VERSION ""

NS_ :

BS_:

BU_: WCM VPM VLM VKM UVM TIM TEST_TOOL_2 TEST_TOOL_1 TCP TCM TCCM3 TCCM STC SRR_SRR SRR_SLR SRR_RR SRR_RF SRR_LR_CR SRR_LF SIB SDM SCL SBZA_R SBZA_L SBM SADS RadioLow RSC RDCM PTM PDR PA NVM MTCM_R MTCM_L MSM_RR MSM_P MSM_LR MSM_D MSB2 MSB1 MRCM_R MRCM_L MFC LRR_HC LRR LIB1 IPC ICS_Info ICCM HVAC_FP_R HVAC_FP_F HUD_CAN HDLM FCM_LC FCM EPS EOCM_HCP2 EOCM_HCP1 EOCM ELM ECP_X1 ECP_MC ECP_E ECM EBCM DMS DEFC DCM CSM CMMb CMMa CGM BSM_MH BSM BCM ARS ARB APA AOS AMP ALC AHS AHL_AFL AGC
VAL_TABLE_ PrsnlMdBrkPdlCstmCurSetVal 0 "SETTING_UNKNOWN" 1 "PERSONAL_MODE_1" 2 "PERSONAL_MODE_2" 3 "PERSONAL_MODE_3" 4 "PERSONAL_MODE_4" 5 "PERSONAL_MODE_5" 6 "PERSONAL_MODE_6" 7 "PERSONAL_MODE_7" ;
VAL_TABLE_ PrsnlMdSpnCstmCurSetVal 0 "SETTING_UNKNOWN" 1 "PERSONAL_MODE_1" 2 "PERSONAL_MODE_2" 3 "PERSONAL_MODE_3" 4 "PERSONAL_MODE_4" 5 "PERSONAL_MODE_5" 6 "PERSONAL_MODE_6" 7 "PERSONAL_MODE_7" ;
VAL_TABLE_ PrsnlMdSndCstmCurSetVal 0 "SETTING_UNKNOWN" 1 "PERSONAL_MODE_1" 2 "PERSONAL_MODE_2" 3 "PERSONAL_MODE_3" 4 "PERSONAL_MODE_4" 5 "PERSONAL_MODE_5" 6 "PERSONAL_MODE_6" 7 "PERSONAL_MODE_7" ;
VAL_TABLE_ PrsnlMdRideHghtCstmSetAv 0 "FALSE" 1 "TRUE" ;
VAL_TABLE_ PrsnlMdDrvlCstmSetAv 0 "FALSE" 1 "TRUE" ;
VAL_TABLE_ PrsnlMdBrkPdlCstmSetAv 0 "FALSE" 1 "TRUE" ;
VAL_TABLE_ PrsnlMdActAeroCstmSetAv 0 "FALSE" 1 "TRUE" ;
VAL_TABLE_ ExtdHillStrtAstCustSetAvl 0 "FALSE" 1 "TRUE" ;
VAL_TABLE_ PrsnlMdStrCstmCurSetVal 0 "SETTING_UNKNOWN" 1 "PERSONAL_MODE_1" 2 "PERSONAL_MODE_2" 3 "PERSONAL_MODE_3" 4 "PERSONAL_MODE_4" 5 "PERSONAL_MODE_5" 6 "PERSONAL_MODE_6" 7 "PERSONAL_MODE_7" ;
VAL_TABLE_ TrlrBrkDtd 0 "FALSE" 1 "TRUE" ;
VAL_TABLE_ PrsnlMdStrCstmSetAv 0 "FALSE" 1 "TRUE" ;
VAL_TABLE_ PrsnlMdSpnCstmSetAv 0 "FALSE" 1 "TRUE" ;
VAL_TABLE_ PrsnlMdSndCstmSetAv 0 "FALSE" 1 "TRUE" ;
VAL_TABLE_ JckKnfDtnCstAvlFlg1 0 "FALSE" 1 "TRUE" ;
VAL_TABLE_ CrgBedVwAutoLgtCstAvlFlg7 0 "FALSE" 1 "TRUE" ;
VAL_TABLE_ CrgBedVwAutoLgtCstAvlFlg6 0 "FALSE" 1 "TRUE" ;
VAL_TABLE_ CrgBedVwAutoLgtCstAvlFlg5 0 "FALSE" 1 "TRUE" ;
VAL_TABLE_ CrgBedVwAutoLgtCstAvlFlg4 0 "FALSE" 1 "TRUE" ;
VAL_TABLE_ CrgBedVwAutoLgtCstAvlFlg3 0 "FALSE" 1 "TRUE" ;
VAL_TABLE_ CrgBedVwAutoLgtCstAvlFlg2 0 "FALSE" 1 "TRUE" ;
VAL_TABLE_ CrgBedVwAutoLgtCstAvlFlg1 0 "FALSE" 1 "TRUE" ;
VAL_TABLE_ RrVwPrkAstSymCsAvlFlg2 0 "FALSE" 1 "TRUE" ;
VAL_TABLE_ RrVwPrkAstSymCsAvlFlg1 0 "FALSE" 1 "TRUE" ;
VAL_TABLE_ JckKnfDtnCstAvlFlg7 0 "FALSE" 1 "TRUE" ;
VAL_TABLE_ JckKnfDtnCstAvlFlg6 0 "FALSE" 1 "TRUE" ;
VAL_TABLE_ JckKnfDtnCstAvlFlg5 0 "FALSE" 1 "TRUE" ;
VAL_TABLE_ JckKnfDtnCstAvlFlg4 0 "FALSE" 1 "TRUE" ;
VAL_TABLE_ JckKnfDtnCstAvlFlg3 0 "FALSE" 1 "TRUE" ;
VAL_TABLE_ JckKnfDtnCstAvlFlg2 0 "FALSE" 1 "TRUE" ;
VAL_TABLE_ SrrndVwLghtCsAvlFlg3 0 "FALSE" 1 "TRUE" ;
VAL_TABLE_ SrrndVwLghtCsAvlFlg2 0 "FALSE" 1 "TRUE" ;
VAL_TABLE_ SrrndVwLghtCsAvlFlg1 0 "FALSE" 1 "TRUE" ;
VAL_TABLE_ RrVwPrkAstSymCsAvlFlg7 0 "FALSE" 1 "TRUE" ;
VAL_TABLE_ RrVwPrkAstSymCsAvlFlg6 0 "FALSE" 1 "TRUE" ;
VAL_TABLE_ RrVwPrkAstSymCsAvlFlg5 0 "FALSE" 1 "TRUE" ;
VAL_TABLE_ RrVwPrkAstSymCsAvlFlg4 0 "FALSE" 1 "TRUE" ;
VAL_TABLE_ RrVwPrkAstSymCsAvlFlg3 0 "FALSE" 1 "TRUE" ;
VAL_TABLE_ TrlrMirVidEnblCstAvlFlg4 0 "FALSE" 1 "TRUE" ;
VAL_TABLE_ TrlrMirVidEnblCstAvlFlg3 0 "FALSE" 1 "TRUE" ;
VAL_TABLE_ TrlrMirVidEnblCstAvlFlg2 0 "FALSE" 1 "TRUE" ;
VAL_TABLE_ TrlrMirVidEnblCstAvlFlg1 0 "FALSE" 1 "TRUE" ;
VAL_TABLE_ SrrndVwLghtCsAvlFlg7 0 "FALSE" 1 "TRUE" ;
VAL_TABLE_ SrrndVwLghtCsAvlFlg6 0 "FALSE" 1 "TRUE" ;
VAL_TABLE_ SrrndVwLghtCsAvlFlg5 0 "FALSE" 1 "TRUE" ;
VAL_TABLE_ SrrndVwLghtCsAvlFlg4 0 "FALSE" 1 "TRUE" ;
VAL_TABLE_ TrlrMirVidGdlnsCstAvlFlg5 0 "FALSE" 1 "TRUE" ;
VAL_TABLE_ TrlrMirVidGdlnsCstAvlFlg4 0 "FALSE" 1 "TRUE" ;
VAL_TABLE_ TrlrMirVidGdlnsCstAvlFlg3 0 "FALSE" 1 "TRUE" ;
VAL_TABLE_ TrlrMirVidGdlnsCstAvlFlg2 0 "FALSE" 1 "TRUE" ;
VAL_TABLE_ TrlrMirVidGdlnsCstAvlFlg1 0 "FALSE" 1 "TRUE" ;
VAL_TABLE_ TrlrMirVidEnblCstAvlFlg7 0 "FALSE" 1 "TRUE" ;
VAL_TABLE_ TrlrMirVidEnblCstAvlFlg6 0 "FALSE" 1 "TRUE" ;
VAL_TABLE_ TrlrMirVidEnblCstAvlFlg5 0 "FALSE" 1 "TRUE" ;
VAL_TABLE_ TrlrMirVidGdlnsCstAvlFlg7 0 "FALSE" 1 "TRUE" ;
VAL_TABLE_ TrlrMirVidGdlnsCstAvlFlg6 0 "FALSE" 1 "TRUE" ;
VAL_TABLE_ IndTmpStngStFR 0 "Off" 1 "Auto" 2 "Auto Lo" 3 "Auto Hi" 4 "Manual" ;
VAL_TABLE_ IndTmpStngStFL 0 "Off" 1 "Auto" 2 "Auto Lo" 3 "Auto Hi" 4 "Manual" ;
VAL_TABLE_ IndTmpStngStRR 0 "Off" 1 "Auto" 2 "Auto Lo" 3 "Auto Hi" 4 "Manual" ;
VAL_TABLE_ IndTmpStngStRL 0 "Off" 1 "Auto" 2 "Auto Lo" 3 "Auto Hi" 4 "Manual" ;
VAL_TABLE_ NoRtDetWrngChmEvSt 0 "NO_ACTION" 1 "ACTIVE" 2 "CANCEL_CHIME" ;
VAL_TABLE_ ManlPrkLmpChmEvtSt 0 "NO ACTION" 1 "ACTIVE" 2 "CANCEL CHIME" ;
VAL_TABLE_ LDCLDlydLkChmEvSt 0 "NO_ACTION" 1 "ACTIVE" 2 "CANCEL_CHIME" ;
VAL_TABLE_ KeyInRmdrChmEvntSt 0 "NO_ACTION" 1 "ACTIVE" 2 "CANCEL_CHIME" ;
VAL_TABLE_ PwrRrClsrObstclChmEvntStat 0 "No_Action" 1 "Active" 2 "Cancel_Chime" ;
VAL_TABLE_ PwrRrClsrNtfnChmEvntStat 0 "No_Action" 1 "Active" 2 "Cancel_Chime" ;
VAL_TABLE_ PwrRrClsrNormOpChmEvntStat 0 "No_Action" 1 "Active" 2 "Cancel_Chime" ;
VAL_TABLE_ OneSidedPrkLmpActvnChmEvtSt 0 "NO_ACTION" 1 "ACTIVE" 2 "CANCEL_CHIME" ;
VAL_TABLE_ StrgLckd 0 "FALSE" 1 "TRUE" ;
VAL_TABLE_ WlkAwyLkInhbtChmEvSt 0 "NO_ACTION" 1 "ACTIVE" 2 "CANCEL_CHIME" ;
VAL_TABLE_ ShfttoPrkChmEvntSt 0 "NO_ACTION" 1 "ACTIVE" 2 "CANCEL_CHIME" ;
VAL_TABLE_ RemLtInVhWrngChmEvSt 0 "NO_ACTION" 1 "ACTIVE" 2 "CANCEL_CHIME" ;
VAL_TABLE_ IndAirDstFR 0 "Off" 1 "Auto" 2 "Floor" 3 "Floor And Vent" 4 "Vent" 5 "Vent And Windshield" 6 "Windshield" 7 "Floor And Windshield" 8 "Floor And Vent And Windshield" 9 "Max Defrost" ;
VAL_TABLE_ IndAirDstFL 0 "Off" 1 "Auto" 2 "Floor" 3 "Floor And Vent" 4 "Vent" 5 "Vent And Windshield" 6 "Windshield" 7 "Floor And Windshield" 8 "Floor And Vent And Windshield" 9 "Max Defrost" ;
VAL_TABLE_ IndBlwStngStFrt 0 "Off" 1 "Auto" 2 "Manual" ;
VAL_TABLE_ IndRecircStng 0 "Off" 1 "Fresh Air" 2 "Recirc" ;
VAL_TABLE_ IndCompStng 0 "OFF" 1 "COMP_OFF" 2 "COMP_ON" 3 "COMP_ECON" ;
VAL_TABLE_ IndClmMdStng 0 "OFF" 1 "Comfort" 2 "ECO" 3 "Fan Only" ;
VAL_TABLE_ IndBlwStngStRr 0 "Off" 1 "Auto" 2 "Manual" ;
VAL_TABLE_ IndAirDstRL 0 "Off" 1 "Auto" 2 "Floor" 3 "Floor And Vent" 4 "Vent" 5 "Vent And Roof" 6 "Roof" 7 "Roof And Floor" 8 "Floor And Vent And Roof" ;
VAL_TABLE_ IndSYNC_Rr 0 "FALSE" 1 "TRUE" ;
VAL_TABLE_ IndSYNC_All 0 "FALSE" 1 "TRUE" ;
VAL_TABLE_ IndRrWndDfgStng 0 "Rear Defog OFF" 1 "Rear Defog ON" ;
VAL_TABLE_ IndRrHVAC_On 0 "FALSE" 1 "TRUE" ;
VAL_TABLE_ IndRrHVAC_Lckd 0 "FALSE" 1 "TRUE" ;
VAL_TABLE_ IndHtdFrtWshldSet 0 "HFWS_OFF" 1 "HFWS_ON" ;
VAL_TABLE_ IndFrtHVAC_On 0 "FALSE" 1 "TRUE" ;
VAL_TABLE_ IndAirDstRR 0 "Off" 1 "Auto" 2 "Floor" 3 "Floor And Vent" 4 "Vent" 5 "Vent And Roof" 6 "Roof" 7 "Roof And Floor" 8 "Floor And Vent And Roof" ;
VAL_TABLE_ DslExhFldRmnDist_Inv 0 "FALSE" 1 "TRUE" ;
VAL_TABLE_ FI_FiltdDispTotFlLvlPct_Inv 0 "FALSE" 1 "TRUE" ;
VAL_TABLE_ FI_FiltdDispTotFlLvlTnk2Pct_Inv 0 "FALSE" 1 "TRUE" ;
VAL_TABLE_ EngIntAirTmp_Inv 0 "FALSE" 1 "TRUE" ;
VAL_TABLE_ ASIRI_Ind08 0 "FALSE" 1 "TRUE" ;
VAL_TABLE_ ASIRI_Ind06 0 "FALSE" 1 "TRUE" ;
VAL_TABLE_ ASIRI_Ind04 0 "FALSE" 1 "TRUE" ;
VAL_TABLE_ ASIRI_Ind01 0 "FALSE" 1 "TRUE" ;
VAL_TABLE_ ASIRI_Ind05 0 "FALSE" 1 "TRUE" ;
VAL_TABLE_ ASIRI_Ind07 0 "FALSE" 1 "TRUE" ;
VAL_TABLE_ ASIRI_Ind02 0 "FALSE" 1 "TRUE" ;
VAL_TABLE_ VhSpdCntlSystmTyp 0 "No Vehicle Speed Control" 1 "Conventional Cruise Control" 2 "Adaptive Cruise Control" ;
VAL_TABLE_ MnlTrnsIndReq 0 "No Indication" 1 "Indication 1" 2 "Indication 2" 3 "Indication 3" ;
VAL_TABLE_ EngEmsRltMlfIndRq 0 "Continuous Indication" 1 "No Indication" 2 "Flashing 1 Hertz Indication" 3 "Flashing 2 Hertz Indication" 4 "Flashing 0.5 Hertz Indication" ;
VAL_TABLE_ ASIRI_Ind03 0 "FALSE" 1 "TRUE" ;
VAL_TABLE_ ElecShfPriTransCtlrMalfIndOn 0 "FALSE" 1 "TRUE" ;
VAL_TABLE_ ElecShfPriShfToDrvTryAgnIndOn 0 "FALSE" 1 "TRUE" ;
VAL_TABLE_ EngCmptHotWrnIndReq 0 "Off" 1 "Service" 2 "Hot Idle" 3 "Hot" ;
VAL_TABLE_ ElecShftPrTwoGrsSelIndRq 0 "OFF" 1 "PARK" 2 "NEUTRAL" 3 "DRIVE" ;
VAL_TABLE_ ElecShftPrLtdPrfMdIO 0 "FALSE" 1 "TRUE" ;
VAL_TABLE_ ElecShftPrHldShftLevEngRngIO 0 "FALSE" 1 "TRUE" ;
VAL_TABLE_ ElecShftPrDrPrkIntShftAtmpIO 0 "FALSE" 1 "TRUE" ;
VAL_TABLE_ ElecShftPrDrIntShftAtmpIO 0 "FALSE" 1 "TRUE" ;
VAL_TABLE_ ElecShftPrDrExitIO 0 "FALSE" 1 "TRUE" ;
VAL_TABLE_ ElecShftPrDrDoorStIndIO 0 "FALSE" 1 "TRUE" ;
VAL_TABLE_ ElecShftPrAtPrkIO 0 "FALSE" 1 "TRUE" ;
VAL_TABLE_ ElecShfPriTrnVehOffForPrkIndOn 0 "FALSE" 1 "TRUE" ;
VAL_TABLE_ EngOilChngIO 0 "FALSE" 1 "TRUE" ;
VAL_TABLE_ EngNEmsnsRltMlfnAct 0 "FALSE" 1 "TRUE" ;
VAL_TABLE_ EngHtStpEngIO 0 "FALSE" 1 "TRUE" ;
VAL_TABLE_ EngHtFlEnrchmntIO 0 "FALSE" 1 "TRUE" ;
VAL_TABLE_ EngCstFlCtOffAct 0 "FALSE" 1 "TRUE" ;
VAL_TABLE_ ElecShftPrTrnMlfIO 0 "FALSE" 1 "TRUE" ;
VAL_TABLE_ ElecShftPrRngInvRqIO 0 "FALSE" 1 "TRUE" ;
VAL_TABLE_ ElecShftPrPrkInvRqIO 0 "FALSE" 1 "TRUE" ;
VAL_TABLE_ GenFld 0 "FALSE" 1 "TRUE" ;
VAL_TABLE_ EngWtrInFlIO 0 "FALSE" 1 "TRUE" ;
VAL_TABLE_ EngSpdLmtnMdAct 0 "FALSE" 1 "TRUE" ;
VAL_TABLE_ EngShtdwnPndgIO 0 "FALSE" 1 "TRUE" ;
VAL_TABLE_ EngOilStrvtnIO 0 "FALSE" 1 "TRUE" ;
VAL_TABLE_ EngOilPrsLwIO 0 "FALSE" 1 "TRUE" ;
VAL_TABLE_ EngOilLvlLwIO 0 "FALSE" 1 "TRUE" ;
VAL_TABLE_ EngOilHotIO 0 "FALSE" 1 "TRUE" ;
VAL_TABLE_ TrnsSkpShftIO 0 "FALSE" 1 "TRUE" ;
VAL_TABLE_ PTWrmgWtToShftIO 0 "FALSE" 1 "TRUE" ;
VAL_TABLE_ PTExPrtclFltrWrnIO 0 "FALSE" 1 "TRUE" ;
VAL_TABLE_ PTExPrtclFltrWrn2IO 0 "FALSE" 1 "TRUE" ;
VAL_TABLE_ DslExFldCnWrngIndRq 0 "No Indication" 1 "Warning Level 1" 2 "Warning Level 2" 3 "Warning Level 3" 4 "Warning Level 4" 5 "Warning Level 5" 6 "Warning Level 6" 7 "Warning Level 7" 8 "Warning Level 8" 9 "Warning Level 9" 10 "Warning Level 10" 11 "Warning Level 11" 12 "Warning Level 12" 13 "Warning Level 13" 14 "Warning Level 14" 15 "Warning Level 15" ;
VAL_TABLE_ DslExNxEmWrngIndRq 0 "No Indication" 1 "Warning Level 1" 2 "Warning Level 2" 3 "Warning Level 3" 4 "Warning Level 4" 5 "Warning Level 5" 6 "Warning Level 6" 7 "Warning Level 7" 8 "Warning Level 8" 9 "Warning Level 9" 10 "Warning Level 10" 11 "Warning Level 11" 12 "Warning Level 12" 13 "Warning Level 13" 14 "Warning Level 14" 15 "Warning Level 15" ;
VAL_TABLE_ DslExFldTpWrngIndRq 0 "No Indication" 1 "Warning Level 1" 2 "Warning Level 2" 3 "Warning Level 3" 4 "Warning Level 4" 5 "Warning Level 5" 6 "Warning Level 6" 7 "Warning Level 7" 8 "Warning Level 8" 9 "Warning Level 9" 10 "Warning Level 10" 11 "Warning Level 11" 12 "Warning Level 12" 13 "Warning Level 13" 14 "Warning Level 14" 15 "Warning Level 15" ;
VAL_TABLE_ DslExhFldWrngIdRqER 0 "No Indication" 1 "Warning Level 1" 2 "Warning Level 2" 3 "Warning Level 3" 4 "Warning Level 4" 5 "Warning Level 5" 6 "Warning Level 6" 7 "Warning Level 7" 8 "Warning Level 8" 9 "Warning Level 9" 10 "Warning Level 10" 11 "Warning Level 11" 12 "Warning Level 12" 13 "Warning Level 13" 14 "Warning Level 14" 15 "Warning Level 15" ;
VAL_TABLE_ DslExhFldQlyWrngIReq 0 "No Indication" 1 "Warning Level 1" 2 "Warning Level 2" 3 "Warning Level 3" 4 "Warning Level 4" 5 "Warning Level 5" 6 "Warning Level 6" 7 "Warning Level 7" 8 "Warning Level 8" 9 "Warning Level 9" 10 "Warning Level 10" 11 "Warning Level 11" 12 "Warning Level 12" 13 "Warning Level 13" 14 "Warning Level 14" 15 "Warning Level 15" ;
VAL_TABLE_ DslExhFldDiagWrnIdRq 0 "No Indication" 1 "Warning Level 1" 2 "Warning Level 2" 3 "Warning Level 3" 4 "Warning Level 4" 5 "Warning Level 5" 6 "Warning Level 6" 7 "Warning Level 7" ;
VAL_TABLE_ DrvrSeltdSpdLmtrIndReq 0 "No Action" 1 "Driver Selected Speed Limiter Telltale Off" 2 "Driver Selected Speed Limiter Unavailable Telltale On" 3 "Driver Selected Speed Limiter White Telltale On" 4 "Driver Selected Speed Limiter Green Telltale On" ;
VAL_TABLE_ CnvntlCruzCtlIndReq 0 "No Action" 1 "Cruise Control Telltale Off" 2 "Cruise Control Unavailable Telltale On" 3 "Cruise Control White Telltale On" 4 "Cruise Control Green Telltale On" 5 "Cruise Control Blue Telltale On" ;
VAL_TABLE_ ACCompCmnd 0 "Off" 1 "On" ;
VAL_TABLE_ DslEmnsOBDMrkt 0 "North America" 1 "Europe" ;
VAL_TABLE_ DrSlctdSpdLmtrStSpdLmtRchd 0 "No Limit Reached" 1 "High Limit Reached" 2 "Low Limit Reached" 3 "Reserved" ;
VAL_TABLE_ DrSlctdSpdLmtrSetTypActv 0 "Off" 1 "Manual" 2 "Auto" 3 "Reserved" ;
VAL_TABLE_ ElecShfPriRdcSpdForReqdShfIndOn 0 "FALSE" 1 "TRUE" ;
VAL_TABLE_ CbnHtrWrmUpIndOn 0 "FALSE" 1 "TRUE" ;
VAL_TABLE_ DrSlctdSpdLmtrEnbld 0 "FALSE" 1 "TRUE" ;
VAL_TABLE_ DrSlctdSpdLmtrActv 0 "FALSE" 1 "TRUE" ;
VAL_TABLE_ CkFlFilrCapIO 0 "FALSE" 1 "TRUE" ;
VAL_TABLE_ Bat12VSysUnStab 0 "FALSE" 1 "TRUE" ;
VAL_TABLE_ AppCltchAutSrtIO 0 "FALSE" 1 "TRUE" ;
VAL_TABLE_ AirCndOffIO 0 "FALSE" 1 "TRUE" ;
VAL_TABLE_ EBDFld 0 "FALSE" 1 "TRUE" ;
VAL_TABLE_ CustMdTrcStbCstmAvFlg7 0 "FALSE" 1 "TRUE" ;
VAL_TABLE_ CustMdTrcStbCstmAvFlg6 0 "FALSE" 1 "TRUE" ;
VAL_TABLE_ CustMdTrcStbCstmAvFlg5 0 "FALSE" 1 "TRUE" ;
VAL_TABLE_ CustMdTrcStbCstmAvFlg4 0 "FALSE" 1 "TRUE" ;
VAL_TABLE_ CustMdTrcStbCstmAvFlg3 0 "FALSE" 1 "TRUE" ;
VAL_TABLE_ CustMdTrcStbCstmAvFlg2 0 "FALSE" 1 "TRUE" ;
VAL_TABLE_ CustMdTrcStbCstmAvFlg1 0 "FALSE" 1 "TRUE" ;
VAL_TABLE_ PrsnlMdActAeroCstmAvFlg1 0 "FALSE" 1 "TRUE" ;
VAL_TABLE_ ExtdHillStrtAstCustAvlFlg7 0 "FALSE" 1 "TRUE" ;
VAL_TABLE_ ExtdHillStrtAstCustAvlFlg6 0 "FALSE" 1 "TRUE" ;
VAL_TABLE_ ExtdHillStrtAstCustAvlFlg5 0 "FALSE" 1 "TRUE" ;
VAL_TABLE_ ExtdHillStrtAstCustAvlFlg4 0 "FALSE" 1 "TRUE" ;
VAL_TABLE_ ExtdHillStrtAstCustAvlFlg3 0 "FALSE" 1 "TRUE" ;
VAL_TABLE_ ExtdHillStrtAstCustAvlFlg2 0 "FALSE" 1 "TRUE" ;
VAL_TABLE_ ExtdHillStrtAstCustAvlFlg1 0 "FALSE" 1 "TRUE" ;
VAL_TABLE_ PrsnlMdBrkPdlCstmAvFlg2 0 "FALSE" 1 "TRUE" ;
VAL_TABLE_ PrsnlMdBrkPdlCstmAvFlg1 0 "FALSE" 1 "TRUE" ;
VAL_TABLE_ PrsnlMdActAeroCstmAvFlg7 0 "FALSE" 1 "TRUE" ;
VAL_TABLE_ PrsnlMdActAeroCstmAvFlg6 0 "FALSE" 1 "TRUE" ;
VAL_TABLE_ PrsnlMdActAeroCstmAvFlg5 0 "FALSE" 1 "TRUE" ;
VAL_TABLE_ PrsnlMdActAeroCstmAvFlg4 0 "FALSE" 1 "TRUE" ;
VAL_TABLE_ PrsnlMdActAeroCstmAvFlg3 0 "FALSE" 1 "TRUE" ;
VAL_TABLE_ PrsnlMdActAeroCstmAvFlg2 0 "FALSE" 1 "TRUE" ;
VAL_TABLE_ PrsnlMdDrvlCstmAvFlg3 0 "FALSE" 1 "TRUE" ;
VAL_TABLE_ PrsnlMdDrvlCstmAvFlg2 0 "FALSE" 1 "TRUE" ;
VAL_TABLE_ PrsnlMdDrvlCstmAvFlg1 0 "FALSE" 1 "TRUE" ;
VAL_TABLE_ PrsnlMdBrkPdlCstmAvFlg7 0 "FALSE" 1 "TRUE" ;
VAL_TABLE_ PrsnlMdBrkPdlCstmAvFlg6 0 "FALSE" 1 "TRUE" ;
VAL_TABLE_ PrsnlMdBrkPdlCstmAvFlg5 0 "FALSE" 1 "TRUE" ;
VAL_TABLE_ PrsnlMdBrkPdlCstmAvFlg4 0 "FALSE" 1 "TRUE" ;
VAL_TABLE_ PrsnlMdBrkPdlCstmAvFlg3 0 "FALSE" 1 "TRUE" ;
VAL_TABLE_ PrsnlMdRideHghtCstmAvFlg4 0 "FALSE" 1 "TRUE" ;
VAL_TABLE_ PrsnlMdRideHghtCstmAvFlg3 0 "FALSE" 1 "TRUE" ;
VAL_TABLE_ PrsnlMdRideHghtCstmAvFlg2 0 "FALSE" 1 "TRUE" ;
VAL_TABLE_ PrsnlMdRideHghtCstmAvFlg1 0 "FALSE" 1 "TRUE" ;
VAL_TABLE_ PrsnlMdDrvlCstmAvFlg7 0 "FALSE" 1 "TRUE" ;
VAL_TABLE_ PrsnlMdDrvlCstmAvFlg6 0 "FALSE" 1 "TRUE" ;
VAL_TABLE_ PrsnlMdDrvlCstmAvFlg5 0 "FALSE" 1 "TRUE" ;
VAL_TABLE_ PrsnlMdDrvlCstmAvFlg4 0 "FALSE" 1 "TRUE" ;
VAL_TABLE_ PrsnlMdSndCstmAvFlg5 0 "FALSE" 1 "TRUE" ;
VAL_TABLE_ PrsnlMdSndCstmAvFlg4 0 "FALSE" 1 "TRUE" ;
VAL_TABLE_ PrsnlMdSndCstmAvFlg3 0 "FALSE" 1 "TRUE" ;
VAL_TABLE_ PrsnlMdSndCstmAvFlg2 0 "FALSE" 1 "TRUE" ;
VAL_TABLE_ PrsnlMdSndCstmAvFlg1 0 "FALSE" 1 "TRUE" ;
VAL_TABLE_ PrsnlMdRideHghtCstmAvFlg7 0 "FALSE" 1 "TRUE" ;
VAL_TABLE_ PrsnlMdRideHghtCstmAvFlg6 0 "FALSE" 1 "TRUE" ;
VAL_TABLE_ PrsnlMdRideHghtCstmAvFlg5 0 "FALSE" 1 "TRUE" ;
VAL_TABLE_ PrsnlMdSpnCstmAvFlg6 0 "FALSE" 1 "TRUE" ;
VAL_TABLE_ PrsnlMdSpnCstmAvFlg5 0 "FALSE" 1 "TRUE" ;
VAL_TABLE_ PrsnlMdSpnCstmAvFlg4 0 "FALSE" 1 "TRUE" ;
VAL_TABLE_ PrsnlMdSpnCstmAvFlg3 0 "FALSE" 1 "TRUE" ;
VAL_TABLE_ PrsnlMdSpnCstmAvFlg2 0 "FALSE" 1 "TRUE" ;
VAL_TABLE_ PrsnlMdSpnCstmAvFlg1 0 "FALSE" 1 "TRUE" ;
VAL_TABLE_ PrsnlMdSndCstmAvFlg7 0 "FALSE" 1 "TRUE" ;
VAL_TABLE_ PrsnlMdSndCstmAvFlg6 0 "FALSE" 1 "TRUE" ;
VAL_TABLE_ PrsnlMdStrCstmAvFlg7 0 "FALSE" 1 "TRUE" ;
VAL_TABLE_ PrsnlMdStrCstmAvFlg6 0 "FALSE" 1 "TRUE" ;
VAL_TABLE_ PrsnlMdStrCstmAvFlg5 0 "FALSE" 1 "TRUE" ;
VAL_TABLE_ PrsnlMdStrCstmAvFlg4 0 "FALSE" 1 "TRUE" ;
VAL_TABLE_ PrsnlMdStrCstmAvFlg3 0 "FALSE" 1 "TRUE" ;
VAL_TABLE_ PrsnlMdStrCstmAvFlg2 0 "FALSE" 1 "TRUE" ;
VAL_TABLE_ PrsnlMdStrCstmAvFlg1 0 "FALSE" 1 "TRUE" ;
VAL_TABLE_ PrsnlMdSpnCstmAvFlg7 0 "FALSE" 1 "TRUE" ;
VAL_TABLE_ CustMdActAeroCstmAvFlg6 0 "FALSE" 1 "TRUE" ;
VAL_TABLE_ CustMdActAeroCstmAvFlg5 0 "FALSE" 1 "TRUE" ;
VAL_TABLE_ CustMdActAeroCstmAvFlg4 0 "FALSE" 1 "TRUE" ;
VAL_TABLE_ CustMdActAeroCstmAvFlg3 0 "FALSE" 1 "TRUE" ;
VAL_TABLE_ CustMdActAeroCstmAvFlg2 0 "FALSE" 1 "TRUE" ;
VAL_TABLE_ CustMdActAeroCstmAvFlg1 0 "FALSE" 1 "TRUE" ;
VAL_TABLE_ BrkFldLvlSt 0 "Normal" 1 "Low" 2 "Unknown" ;
VAL_TABLE_ CustMdBrkPdlCstmAvFlg7 0 "FALSE" 1 "TRUE" ;
VAL_TABLE_ CustMdBrkPdlCstmAvFlg6 0 "FALSE" 1 "TRUE" ;
VAL_TABLE_ CustMdBrkPdlCstmAvFlg5 0 "FALSE" 1 "TRUE" ;
VAL_TABLE_ CustMdBrkPdlCstmAvFlg4 0 "FALSE" 1 "TRUE" ;
VAL_TABLE_ CustMdBrkPdlCstmAvFlg3 0 "FALSE" 1 "TRUE" ;
VAL_TABLE_ CustMdBrkPdlCstmAvFlg2 0 "FALSE" 1 "TRUE" ;
VAL_TABLE_ CustMdBrkPdlCstmAvFlg1 0 "FALSE" 1 "TRUE" ;
VAL_TABLE_ CustMdActAeroCstmAvFlg7 0 "FALSE" 1 "TRUE" ;
VAL_TABLE_ CustMdPTCstmAvFlg1 0 "FALSE" 1 "TRUE" ;
VAL_TABLE_ CustMdDrvlCstmAvFlg7 0 "FALSE" 1 "TRUE" ;
VAL_TABLE_ CustMdDrvlCstmAvFlg6 0 "FALSE" 1 "TRUE" ;
VAL_TABLE_ CustMdDrvlCstmAvFlg5 0 "FALSE" 1 "TRUE" ;
VAL_TABLE_ CustMdDrvlCstmAvFlg4 0 "FALSE" 1 "TRUE" ;
VAL_TABLE_ CustMdDrvlCstmAvFlg3 0 "FALSE" 1 "TRUE" ;
VAL_TABLE_ CustMdDrvlCstmAvFlg2 0 "FALSE" 1 "TRUE" ;
VAL_TABLE_ CustMdDrvlCstmAvFlg1 0 "FALSE" 1 "TRUE" ;
VAL_TABLE_ CustMdRideHghtCstmAvFlg2 0 "FALSE" 1 "TRUE" ;
VAL_TABLE_ CustMdRideHghtCstmAvFlg1 0 "FALSE" 1 "TRUE" ;
VAL_TABLE_ CustMdPTCstmAvFlg7 0 "FALSE" 1 "TRUE" ;
VAL_TABLE_ CustMdPTCstmAvFlg6 0 "FALSE" 1 "TRUE" ;
VAL_TABLE_ CustMdPTCstmAvFlg5 0 "FALSE" 1 "TRUE" ;
VAL_TABLE_ CustMdPTCstmAvFlg4 0 "FALSE" 1 "TRUE" ;
VAL_TABLE_ CustMdPTCstmAvFlg3 0 "FALSE" 1 "TRUE" ;
VAL_TABLE_ CustMdPTCstmAvFlg2 0 "FALSE" 1 "TRUE" ;
VAL_TABLE_ CustMdSndCstmAvFlg3 0 "FALSE" 1 "TRUE" ;
VAL_TABLE_ CustMdSndCstmAvFlg2 0 "FALSE" 1 "TRUE" ;
VAL_TABLE_ CustMdSndCstmAvFlg1 0 "FALSE" 1 "TRUE" ;
VAL_TABLE_ CustMdRideHghtCstmAvFlg7 0 "FALSE" 1 "TRUE" ;
VAL_TABLE_ CustMdRideHghtCstmAvFlg6 0 "FALSE" 1 "TRUE" ;
VAL_TABLE_ CustMdRideHghtCstmAvFlg5 0 "FALSE" 1 "TRUE" ;
VAL_TABLE_ CustMdRideHghtCstmAvFlg4 0 "FALSE" 1 "TRUE" ;
VAL_TABLE_ CustMdRideHghtCstmAvFlg3 0 "FALSE" 1 "TRUE" ;
VAL_TABLE_ CustMdSpnCstmAvFlg4 0 "FALSE" 1 "TRUE" ;
VAL_TABLE_ CustMdSpnCstmAvFlg3 0 "FALSE" 1 "TRUE" ;
VAL_TABLE_ CustMdSpnCstmAvFlg2 0 "FALSE" 1 "TRUE" ;
VAL_TABLE_ CustMdSpnCstmAvFlg1 0 "FALSE" 1 "TRUE" ;
VAL_TABLE_ CustMdSndCstmAvFlg7 0 "FALSE" 1 "TRUE" ;
VAL_TABLE_ CustMdSndCstmAvFlg6 0 "FALSE" 1 "TRUE" ;
VAL_TABLE_ CustMdSndCstmAvFlg5 0 "FALSE" 1 "TRUE" ;
VAL_TABLE_ CustMdSndCstmAvFlg4 0 "FALSE" 1 "TRUE" ;
VAL_TABLE_ CustMdStrCstmAvFlg5 0 "FALSE" 1 "TRUE" ;
VAL_TABLE_ CustMdStrCstmAvFlg4 0 "FALSE" 1 "TRUE" ;
VAL_TABLE_ CustMdStrCstmAvFlg3 0 "FALSE" 1 "TRUE" ;
VAL_TABLE_ CustMdStrCstmAvFlg2 0 "FALSE" 1 "TRUE" ;
VAL_TABLE_ CustMdStrCstmAvFlg1 0 "FALSE" 1 "TRUE" ;
VAL_TABLE_ CustMdSpnCstmAvFlg7 0 "FALSE" 1 "TRUE" ;
VAL_TABLE_ CustMdSpnCstmAvFlg6 0 "FALSE" 1 "TRUE" ;
VAL_TABLE_ CustMdSpnCstmAvFlg5 0 "FALSE" 1 "TRUE" ;
VAL_TABLE_ CustMdStrCstmAvFlg7 0 "FALSE" 1 "TRUE" ;
VAL_TABLE_ CustMdStrCstmAvFlg6 0 "FALSE" 1 "TRUE" ;
VAL_TABLE_ TkModeDrvlineVisDispVal 0 "Setting_Unknown" 1 "Custom_Mode_1" 2 "Custom_Mode_2" 3 "Custom_Mode_3" 4 "Custom_Mode_4" 5 "Custom_Mode_5" 6 "Custom_Mode_6" 7 "Custom_Mode_7" ;
VAL_TABLE_ TkModeBrkPedVisDispVal 0 "Setting_Unknown" 1 "Custom_Mode_1" 2 "Custom_Mode_2" 3 "Custom_Mode_3" 4 "Custom_Mode_4" 5 "Custom_Mode_5" 6 "Custom_Mode_6" 7 "Custom_Mode_7" ;
VAL_TABLE_ TkModeActvAeroVisDispVal 0 "Setting_Unknown" 1 "Custom_Mode_1" 2 "Custom_Mode_2" 3 "Custom_Mode_3" 4 "Custom_Mode_4" 5 "Custom_Mode_5" 6 "Custom_Mode_6" 7 "Custom_Mode_7" ;
VAL_TABLE_ TkModeRideHghtVisDispVal 0 "Setting_Unknown" 1 "Custom_Mode_1" 2 "Custom_Mode_2" 3 "Custom_Mode_3" 4 "Custom_Mode_4" 5 "Custom_Mode_5" 6 "Custom_Mode_6" 7 "Custom_Mode_7" ;
VAL_TABLE_ TkModePwrtrnVisDispVal 0 "Setting_Unknown" 1 "Custom_Mode_1" 2 "Custom_Mode_2" 3 "Custom_Mode_3" 4 "Custom_Mode_4" 5 "Custom_Mode_5" 6 "Custom_Mode_6" 7 "Custom_Mode_7" ;
VAL_TABLE_ TkModeESCVisDispVal 0 "Setting_Unknown" 1 "Custom_Mode_1" 2 "Custom_Mode_2" 3 "Custom_Mode_3" 4 "Custom_Mode_4" 5 "Custom_Mode_5" 6 "Custom_Mode_6" 7 "Custom_Mode_7" ;
VAL_TABLE_ TkModeSpnsnVisDispVal 0 "Setting_Unknown" 1 "Custom_Mode_1" 2 "Custom_Mode_2" 3 "Custom_Mode_3" 4 "Custom_Mode_4" 5 "Custom_Mode_5" 6 "Custom_Mode_6" 7 "Custom_Mode_7" ;
VAL_TABLE_ TkModeSndVisDispVal 0 "Setting_Unknown" 1 "Custom_Mode_1" 2 "Custom_Mode_2" 3 "Custom_Mode_3" 4 "Custom_Mode_4" 5 "Custom_Mode_5" 6 "Custom_Mode_6" 7 "Custom_Mode_7" ;
VAL_TABLE_ WthrSnwModeBrkPedVisDispVal 0 "Setting_Unknown" 1 "Custom_Mode_1" 2 "Custom_Mode_2" 3 "Custom_Mode_3" 4 "Custom_Mode_4" 5 "Custom_Mode_5" 6 "Custom_Mode_6" 7 "Custom_Mode_7" ;
VAL_TABLE_ WthrSnwModeActvAeroVisDispVal 0 "Setting_Unknown" 1 "Custom_Mode_1" 2 "Custom_Mode_2" 3 "Custom_Mode_3" 4 "Custom_Mode_4" 5 "Custom_Mode_5" 6 "Custom_Mode_6" 7 "Custom_Mode_7" ;
VAL_TABLE_ TkModeStrgVisDispVal 0 "Setting_Unknown" 1 "Custom_Mode_1" 2 "Custom_Mode_2" 3 "Custom_Mode_3" 4 "Custom_Mode_4" 5 "Custom_Mode_5" 6 "Custom_Mode_6" 7 "Custom_Mode_7" ;
VAL_TABLE_ WthrSnwModePwrtrnVisDispVal 0 "Setting_Unknown" 1 "Custom_Mode_1" 2 "Custom_Mode_2" 3 "Custom_Mode_3" 4 "Custom_Mode_4" 5 "Custom_Mode_5" 6 "Custom_Mode_6" 7 "Custom_Mode_7" ;
VAL_TABLE_ WthrSnwModeESCVisDispVal 0 "Setting_Unknown" 1 "Custom_Mode_1" 2 "Custom_Mode_2" 3 "Custom_Mode_3" 4 "Custom_Mode_4" 5 "Custom_Mode_5" 6 "Custom_Mode_6" 7 "Custom_Mode_7" ;
VAL_TABLE_ WthrSnwModeDrvlineVisDispVal 0 "Setting_Unknown" 1 "Custom_Mode_1" 2 "Custom_Mode_2" 3 "Custom_Mode_3" 4 "Custom_Mode_4" 5 "Custom_Mode_5" 6 "Custom_Mode_6" 7 "Custom_Mode_7" ;
VAL_TABLE_ WthrSnwModeSndVisDispVal 0 "Setting_Unknown" 1 "Custom_Mode_1" 2 "Custom_Mode_2" 3 "Custom_Mode_3" 4 "Custom_Mode_4" 5 "Custom_Mode_5" 6 "Custom_Mode_6" 7 "Custom_Mode_7" ;
VAL_TABLE_ WthrSnwModeRideHghtVisDispVal 0 "Setting_Unknown" 1 "Custom_Mode_1" 2 "Custom_Mode_2" 3 "Custom_Mode_3" 4 "Custom_Mode_4" 5 "Custom_Mode_5" 6 "Custom_Mode_6" 7 "Custom_Mode_7" ;
VAL_TABLE_ TrcStbScrConfig 0 "None" 1 "TCS Only" 2 "TCS and ESC" 3 "TCS ESC and Comp" ;
VAL_TABLE_ WthrSnwModeStrgVisDispVal 0 "Setting_Unknown" 1 "Custom_Mode_1" 2 "Custom_Mode_2" 3 "Custom_Mode_3" 4 "Custom_Mode_4" 5 "Custom_Mode_5" 6 "Custom_Mode_6" 7 "Custom_Mode_7" ;
VAL_TABLE_ WthrSnwModeSpnsnVisDispVal 0 "Setting_Unknown" 1 "Custom_Mode_1" 2 "Custom_Mode_2" 3 "Custom_Mode_3" 4 "Custom_Mode_4" 5 "Custom_Mode_5" 6 "Custom_Mode_6" 7 "Custom_Mode_7" ;
VAL_TABLE_ TrcCntrlSysTmpDisReqIO 0 "FALSE" 1 "TRUE" ;
VAL_TABLE_ TrcCntrlOnIO 0 "FALSE" 1 "TRUE" ;
VAL_TABLE_ TrcCntrlOffIO 0 "FALSE" 1 "TRUE" ;
VAL_TABLE_ TCSCustAv 0 "FALSE" 1 "TRUE" ;
VAL_TABLE_ TCSCurStat 0 "On" 1 "Off" ;
VAL_TABLE_ SprtModeBrkPedVisDispVal 0 "Setting_Unknown" 1 "Custom_Mode_1" 2 "Custom_Mode_2" 3 "Custom_Mode_3" 4 "Custom_Mode_4" 5 "Custom_Mode_5" 6 "Custom_Mode_6" 7 "Custom_Mode_7" ;
VAL_TABLE_ SprtModeActvAeroVisDispVal 0 "Setting_Unknown" 1 "Custom_Mode_1" 2 "Custom_Mode_2" 3 "Custom_Mode_3" 4 "Custom_Mode_4" 5 "Custom_Mode_5" 6 "Custom_Mode_6" 7 "Custom_Mode_7" ;
VAL_TABLE_ PerfTracMgmtMode 0 "Disabled" 1 "Wet" 2 "Dry" 3 "Sport 1" 4 "Sport 2/Race 1" 5 "Race" 6 "Inactive" ;
VAL_TABLE_ SprtModePwrtrnVisDispVal 0 "Setting_Unknown" 1 "Custom_Mode_1" 2 "Custom_Mode_2" 3 "Custom_Mode_3" 4 "Custom_Mode_4" 5 "Custom_Mode_5" 6 "Custom_Mode_6" 7 "Custom_Mode_7" ;
VAL_TABLE_ SprtModeESCVisDispVal 0 "Setting_Unknown" 1 "Custom_Mode_1" 2 "Custom_Mode_2" 3 "Custom_Mode_3" 4 "Custom_Mode_4" 5 "Custom_Mode_5" 6 "Custom_Mode_6" 7 "Custom_Mode_7" ;
VAL_TABLE_ SprtModeDrvlineVisDispVal 0 "Setting_Unknown" 1 "Custom_Mode_1" 2 "Custom_Mode_2" 3 "Custom_Mode_3" 4 "Custom_Mode_4" 5 "Custom_Mode_5" 6 "Custom_Mode_6" 7 "Custom_Mode_7" ;
VAL_TABLE_ SprtModeSndVisDispVal 0 "Setting_Unknown" 1 "Custom_Mode_1" 2 "Custom_Mode_2" 3 "Custom_Mode_3" 4 "Custom_Mode_4" 5 "Custom_Mode_5" 6 "Custom_Mode_6" 7 "Custom_Mode_7" ;
VAL_TABLE_ SprtModeRideHghtVisDispVal 0 "Setting_Unknown" 1 "Custom_Mode_1" 2 "Custom_Mode_2" 3 "Custom_Mode_3" 4 "Custom_Mode_4" 5 "Custom_Mode_5" 6 "Custom_Mode_6" 7 "Custom_Mode_7" ;
VAL_TABLE_ TireTrdTempSts 0 "Unknown" 1 "Cold" 2 "Cool" 3 "Normal" 4 "Warm" 5 "Hot" ;
VAL_TABLE_ SprtModeStrgVisDispVal 0 "Setting_Unknown" 1 "Custom_Mode_1" 2 "Custom_Mode_2" 3 "Custom_Mode_3" 4 "Custom_Mode_4" 5 "Custom_Mode_5" 6 "Custom_Mode_6" 7 "Custom_Mode_7" ;
VAL_TABLE_ SprtModeSpnsnVisDispVal 0 "Setting_Unknown" 1 "Custom_Mode_1" 2 "Custom_Mode_2" 3 "Custom_Mode_3" 4 "Custom_Mode_4" 5 "Custom_Mode_5" 6 "Custom_Mode_6" 7 "Custom_Mode_7" ;
VAL_TABLE_ TourModeDrvlineVisDispVal 0 "Setting_Unknown" 1 "Custom_Mode_1" 2 "Custom_Mode_2" 3 "Custom_Mode_3" 4 "Custom_Mode_4" 5 "Custom_Mode_5" 6 "Custom_Mode_6" 7 "Custom_Mode_7" ;
VAL_TABLE_ TourModeBrkPedVisDispVal 0 "Setting_Unknown" 1 "Custom_Mode_1" 2 "Custom_Mode_2" 3 "Custom_Mode_3" 4 "Custom_Mode_4" 5 "Custom_Mode_5" 6 "Custom_Mode_6" 7 "Custom_Mode_7" ;
VAL_TABLE_ TourModeActvAeroVisDispVal 0 "Setting_Unknown" 1 "Custom_Mode_1" 2 "Custom_Mode_2" 3 "Custom_Mode_3" 4 "Custom_Mode_4" 5 "Custom_Mode_5" 6 "Custom_Mode_6" 7 "Custom_Mode_7" ;
VAL_TABLE_ TourModePwrtrnVisDispVal 0 "Setting_Unknown" 1 "Custom_Mode_1" 2 "Custom_Mode_2" 3 "Custom_Mode_3" 4 "Custom_Mode_4" 5 "Custom_Mode_5" 6 "Custom_Mode_6" 7 "Custom_Mode_7" ;
VAL_TABLE_ TourModeESCVisDispVal 0 "Setting_Unknown" 1 "Custom_Mode_1" 2 "Custom_Mode_2" 3 "Custom_Mode_3" 4 "Custom_Mode_4" 5 "Custom_Mode_5" 6 "Custom_Mode_6" 7 "Custom_Mode_7" ;
VAL_TABLE_ TourModeSpnsnVisDispVal 0 "Setting_Unknown" 1 "Custom_Mode_1" 2 "Custom_Mode_2" 3 "Custom_Mode_3" 4 "Custom_Mode_4" 5 "Custom_Mode_5" 6 "Custom_Mode_6" 7 "Custom_Mode_7" ;
VAL_TABLE_ TourModeSndVisDispVal 0 "Setting_Unknown" 1 "Custom_Mode_1" 2 "Custom_Mode_2" 3 "Custom_Mode_3" 4 "Custom_Mode_4" 5 "Custom_Mode_5" 6 "Custom_Mode_6" 7 "Custom_Mode_7" ;
VAL_TABLE_ TourModeRideHghtVisDispVal 0 "Setting_Unknown" 1 "Custom_Mode_1" 2 "Custom_Mode_2" 3 "Custom_Mode_3" 4 "Custom_Mode_4" 5 "Custom_Mode_5" 6 "Custom_Mode_6" 7 "Custom_Mode_7" ;
VAL_TABLE_ TnDrvTrCtrlOffUnvIndOn 0 "FALSE" 1 "TRUE" ;
VAL_TABLE_ SrBkLwBkFlDrVisMsgRqOn 0 "FALSE" 1 "TRUE" ;
VAL_TABLE_ ShfToPrkBfrExtIndOn 0 "FALSE" 1 "TRUE" ;
VAL_TABLE_ TourModeStrgVisDispVal 0 "Setting_Unknown" 1 "Custom_Mode_1" 2 "Custom_Mode_2" 3 "Custom_Mode_3" 4 "Custom_Mode_4" 5 "Custom_Mode_5" 6 "Custom_Mode_6" 7 "Custom_Mode_7" ;
VAL_TABLE_ HillDscntCtlSysSts 0 "Unknown" 1 "Normal" 2 "Enabled" 3 "Active" 4 "Failed" ;
VAL_TABLE_ EngSndPerfModeReq 0 "No Action" 1 "Tour" 2 "Sport" 3 "Track" 4 "Stealth" 5 "Performance Mode 5" 6 "Performance Mode 6" 7 "Performance Mode 7" ;
VAL_TABLE_ DrvModeVisScreenSts 0 "No_Action" 1 "Custom" 2 "Personal" 3 "Sport" 4 "Snow_Ice" 5 "Weather" 6 "Tour" 7 "Track" 8 "Offroad" 9 "TowHaul" 10 "PerformanceSportPlus" ;
VAL_TABLE_ BrksOvrht 0 "FALSE" 1 "TRUE" ;
VAL_TABLE_ BrkSysHillStrtAsstAvl 0 "FALSE" 1 "TRUE" ;
VAL_TABLE_ BrkPadLifeRrCnfrmRplcmtIndOn 0 "FALSE" 1 "TRUE" ;
VAL_TABLE_ BrkPadLifeFrtCnfrmRplcmtIndOn 0 "FALSE" 1 "TRUE" ;
VAL_TABLE_ BrkPadLifeRrDistWrnIndReq 0 "No Action" 1 "Low" 2 "Display Distance" ;
VAL_TABLE_ HillDscntCtlRdcVehSpdIndOn 0 "FALSE" 1 "TRUE" ;
VAL_TABLE_ CustmStbCtlRdctReqIndOn 0 "FALSE" 1 "TRUE" ;
VAL_TABLE_ AutMirFldCstCurSetVal 0 "SETTING_UNKNOWN" 1 "Off" 2 "On" 3 "RESERVED_3" 4 "RESERVED_4" 5 "RESERVED_5" 6 "RESERVED_6" 7 "RESERVED_7" ;
VAL_TABLE_ AutDrvLckCstCurSetVal 0 "SETTING_UNKNOWN" 1 "OFF" 2 "ON" 3 "RESERVED_3" 4 "RESERVED_4" 5 "RESERVED_5" 6 "RESERVED_6" 7 "RESERVED_7" ;
VAL_TABLE_ AirQltySnsCstCrStVal 0 "SETTING_UNKNOWN" 1 "OFF" 2 "LOW_SENSITIVITY" 3 "HI_SENSITIVITY" 4 "RESERVED_1" 5 "RESERVED_2" 6 "RESERVED_3" 7 "RESERVED_4" ;
VAL_TABLE_ AutoCoolStCstCrStVal 0 "SETTING_UNKNOWN" 1 "OFF" 2 "ON" 3 "RESERVED_1" 4 "RESERVED_2" 5 "RESERVED_3" 6 "RESERVED_4" 7 "RESERVED_5" ;
VAL_TABLE_ AutoAirDstCstCrStVal 0 "SETTING_UNKNOWN" 1 "DIFFUSE_AIRFLOW" 2 "NORMAL" 3 "DIRECT_AIRFLOW" 4 "OSCILLATING_AIRFLOW" 5 "RESERVED_1" 6 "RESERVED_2" 7 "RESERVED_3" ;
VAL_TABLE_ AutUnlckCstCurSetVal 0 "NO_ACTION" 1 "OFF" 2 "ALL_DOORS" 3 "DRIVER_DOOR" 4 "RESERVED_4" 5 "RESERVED_5" 6 "RESERVED_6" 7 "RESERVED_7" ;
VAL_TABLE_ AutoFanCstCrStVal 0 "SETTING_UNKNOWN" 1 "LOW" 2 "NORMAL" 3 "HIGH" 4 "RESERVED_1" 5 "RESERVED_2" 6 "RESERVED_3" 7 "RESERVED_4" ;
VAL_TABLE_ AutoDfgCstCrStVal 0 "SETTING_UNKNOWN" 1 "OFF" 2 "ON" 3 "RESERVED_1" 4 "RESERVED_2" 5 "RESERVED_3" 6 "RESERVED_4" 7 "RESERVED_5" ;
VAL_TABLE_ DaytimeTlLghtsCstCurSetVal 0 "SETTING_UNKNOWN" 1 "OFF" 2 "ON" 3 "RESERVED_3" 4 "RESERVED_4" 5 "RESERVED_5" 6 "RESERVED_6" 7 "RESERVED_7" ;
VAL_TABLE_ AutoRrWpCstCurSetVal 0 "SETTING_UNKNOWN" 1 "OFF" 2 "ON" 3 "RESERVED_3" 4 "RESERVED_4" 5 "RESERVED_5" 6 "RESERVED_6" 7 "RESERVED_7" ;
VAL_TABLE_ AutoHtdStCstCrStVal 0 "SETTING_UNKNOWN" 1 "OFF" 2 "ON" 3 "RESERVED_1" 4 "RESERVED_2" 5 "RESERVED_3" 6 "RESERVED_4" 7 "RESERVED_5" ;
VAL_TABLE_ AutoAirDstCstStAvl 0 "FALSE" 1 "TRUE" ;
VAL_TABLE_ AutUnlckCstStAvl 0 "FALSE" 1 "TRUE" ;
VAL_TABLE_ AutMirFldCstStAvl 0 "FALSE" 1 "TRUE" ;
VAL_TABLE_ AutDrvLckCstStAvl 0 "FALSE" 1 "TRUE" ;
VAL_TABLE_ AirQltySnsCstStAvl 0 "FALSE" 1 "TRUE" ;
VAL_TABLE_ CurbVwFtrActvReq 0 "On" 1 "Off" 2 "Failed" ;
VAL_TABLE_ DM1Unavailable 0 "FALSE" 1 "TRUE" ;
VAL_TABLE_ DM1Pending 0 "FALSE" 1 "TRUE" ;
VAL_TABLE_ CrsCntCncRq 0 "Do Not Cancel" 1 "Cancel" ;
VAL_TABLE_ AutoRrWpCstStAvl 0 "FALSE" 1 "TRUE" ;
VAL_TABLE_ AutoHtdStCstStAvl 0 "FALSE" 1 "TRUE" ;
VAL_TABLE_ AutoFanCstStAvl 0 "FALSE" 1 "TRUE" ;
VAL_TABLE_ AutoDfgCstStAvl 0 "FALSE" 1 "TRUE" ;
VAL_TABLE_ AutoCoolStCstStAvl 0 "FALSE" 1 "TRUE" ;
VAL_TABLE_ DM5Unavailable 0 "FALSE" 1 "TRUE" ;
VAL_TABLE_ DM5Pending 0 "FALSE" 1 "TRUE" ;
VAL_TABLE_ DM4Unavailable 0 "FALSE" 1 "TRUE" ;
VAL_TABLE_ DM4Pending 0 "FALSE" 1 "TRUE" ;
VAL_TABLE_ DM3Unavailable 0 "FALSE" 1 "TRUE" ;
VAL_TABLE_ DM3Pending 0 "FALSE" 1 "TRUE" ;
VAL_TABLE_ DM2Unavailable 0 "FALSE" 1 "TRUE" ;
VAL_TABLE_ DM2Pending 0 "FALSE" 1 "TRUE" ;
VAL_TABLE_ DaytimeTlLghtsCstStAvl 0 "FALSE" 1 "TRUE" ;
VAL_TABLE_ DM8Unavailable 0 "FALSE" 1 "TRUE" ;
VAL_TABLE_ DM8Pending 0 "FALSE" 1 "TRUE" ;
VAL_TABLE_ DM7Unavailable 0 "FALSE" 1 "TRUE" ;
VAL_TABLE_ DM7Pending 0 "FALSE" 1 "TRUE" ;
VAL_TABLE_ DM6Unavailable 0 "FALSE" 1 "TRUE" ;
VAL_TABLE_ DM6Pending 0 "FALSE" 1 "TRUE" ;
VAL_TABLE_ IntDimSeldAnmTypStVal 0 "No Action" 1 "Off" 2 "Animation Type 1" 3 "Animation Type 2" 4 "Animation Type 3" 5 "Animation Type 4" 6 "Animation Type 5" 7 "Animation Type 6" 8 "Animation Type 7" 9 "Animation Type 8" 10 "Animation Type 9" 11 "Animation Type 10" 12 "Animation Type 11" 13 "Animation Type 12" 14 "Animation Type 13" 15 "Animation Type 14" ;
VAL_TABLE_ IntDimSeldClrTypStVal 0 "No Action" 1 "Off" 2 "Color Type 1" 3 "Color Type 2" 4 "Color Type 3" 5 "Color Type 4" 6 "Color Type 5" 7 "Color Type 6" 8 "Color Type 7" 9 "Color Type 8" 10 "Color Type 9" 11 "Color Type 10" 12 "Color Type 11" 13 "Color Type 12" 14 "Color Type 13" 15 "Color Type 14" 16 "Color Type 15" 17 "Color Type 16" 18 "Color Type 17" 19 "Color Type 18" 20 "Color Type 19" 21 "Color Type 20" 22 "Color Type 21" 23 "Color Type 22" 24 "Color Type 23" 25 "Color Type 24" 26 "Color Type 25" 27 "Color Type 26" 28 "Color Type 27" 29 "Color Type 28" 30 "Color Type 29" 31 "Color Type 30" ;
VAL_TABLE_ IonzrCtrlCstCrStVal 0 "SETTING_UNKNOWN" 1 "OFF" 2 "ON" 3 "RESERVED_1" 4 "RESERVED_2" 5 "RESERVED_3" 6 "RESERVED_4" 7 "RESERVED_5" ;
VAL_TABLE_ HFRCCstCurSetVal 0 "SETTING_UNKNOWN" 1 "OFF" 2 "OPEN_AND_CLOSE" 3 "OPEN_ONLY" 4 "RESERVED_4" 5 "RESERVED_5" 6 "RESERVED_6" 7 "RESERVED_7" ;
VAL_TABLE_ ExtLghtCstCurSetVal 0 "SETTING_UNKNOWN" 1 "OFF" 2 "THIRTY_SECONDS_DEFAULT" 3 "ONE_MINUTE" 4 "TWO_MINUTES" 5 "RESERVED_5" 6 "RESERVED_6" 7 "RESERVED_7" ;
VAL_TABLE_ OpDrAtLOCstCurSetVal 0 "SETTING_UNKNOWN" 1 "OFF" 2 "ON" 3 "RESERVED_3" 4 "RESERVED_4" 5 "RESERVED_5" 6 "RESERVED_6" 7 "RESERVED_7" ;
VAL_TABLE_ LDCLCstCurSetVal 0 "SETTING_UNKNOWN" 1 "OFF" 2 "ON" 3 "RESERVED_3" 4 "RESERVED_4" 5 "RESERVED_5" 6 "RESERVED_6" 7 "RESERVED_7" ;
VAL_TABLE_ RlkRtUlkDrCstCrSetVal 0 "SETTING_UNKNOWN" 1 "OFF" 2 "ON" 3 "RESERVED_3" 4 "RESERVED_4" 5 "RESERVED_5" 6 "RESERVED_6" 7 "RESERVED_7" ;
VAL_TABLE_ PsvUnlckCstCurSetVal 0 "SETTING_UNKNOWN" 1 "DRIVER_DOOR" 2 "ALL_DOORS" 3 "OFF" 4 "RESERVED_4" 5 "RESERVED_5" 6 "RESERVED_6" 7 "RESERVED_7" ;
VAL_TABLE_ PlltnCtrlCstCrStVal 0 "SETTING_UNKNOWN" 1 "OFF" 2 "ON" 3 "RESERVED_1" 4 "RESERVED_2" 5 "RESERVED_3" 6 "RESERVED_4" 7 "RESERVED_5" ;
VAL_TABLE_ RrStRmndrEnblDsblCstCurrSetVal 0 "Setting_Unknown" 1 "Off" 2 "On" 3 "(Reserved_3" 4 "Reserved_4" 5 "Reserved_5" 6 "Reserved_6" 7 "Reserved_7)" ;
VAL_TABLE_ RrDfgStUpCstCrStVal 0 "SETTING_UNKNOWN" 1 "MANUAL" 2 "AUTOMATIC" 3 "RESERVED_1" 4 "RESERVED_2" 5 "RESERVED_3" 6 "RESERVED_4" 7 "RESERVED_5" ;
VAL_TABLE_ RnSnsCstCurSetVal 0 "SETTING_UNKNOWN" 1 "OFF" 2 "ON" 3 "RESERVED_3" 4 "RESERVED_4" 5 "RESERVED_5" 6 "RESERVED_6" 7 "RESERVED_7" ;
VAL_TABLE_ ExtLghtCstStAvl 0 "FALSE" 1 "TRUE" ;
VAL_TABLE_ RrAirHandlingDrActrPwrReq 0 "No Action" 1 "Power Off" 2 "Power On" ;
VAL_TABLE_ RrZnStUpCstCrStVal 0 "SETTING_UNKNOWN" 1 "REAR_OFF" 2 "REAR_MIMIC_FRONT" 3 "REAR_LAST_KNOWN" 4 "RESERVED_1" 5 "RESERVED_2" 6 "RESERVED_3" 7 "RESERVED_4" ;
VAL_TABLE_ RnSnsCstStAvl 0 "FALSE" 1 "TRUE" ;
VAL_TABLE_ RlkRtUlkDrCstStAvl 0 "FALSE" 1 "TRUE" ;
VAL_TABLE_ PsvUnlckCstStAvl 0 "FALSE" 1 "TRUE" ;
VAL_TABLE_ PlltnCtrlCstStAvl 0 "FALSE" 1 "TRUE" ;
VAL_TABLE_ OpDrAtLOCstStAvl 0 "FALSE" 1 "TRUE" ;
VAL_TABLE_ LDCLCstStAvl 0 "FALSE" 1 "TRUE" ;
VAL_TABLE_ IonzrCtrlCstStAvl 0 "FALSE" 1 "TRUE" ;
VAL_TABLE_ HFRCCstStAvl 0 "FALSE" 1 "TRUE" ;
VAL_TABLE_ RrZnStUpCstStAvl 0 "FALSE" 1 "TRUE" ;
VAL_TABLE_ RrStRmndrEnblDsblCstSetAval 0 "FALSE" 1 "TRUE" ;
VAL_TABLE_ RrDfgStUpCstStAvl 0 "FALSE" 1 "TRUE" ;
VAL_TABLE_ RevTltMirCstCurSetVal 0 "SETTING_UNKNOWN" 1 "OFF" 2 "DRIVER" 3 "PASSENGER" 4 "DRIVER_AND_PASSENGER" 5 "RESERVED_5" 6 "RESERVED_6" 7 "RESERVED_7" ;
VAL_TABLE_ RemLftVehRmndrCstCurSetVal 0 "SETTING_UNKNOWN" 1 "OFF" 2 "ON" 3 "RESERVED_3" 4 "RESERVED_4" 5 "RESERVED_5" 6 "RESERVED_6" 7 "RESERVED_7" ;
VAL_TABLE_ RemInVehRmndrCstCurSetVal 0 "SETTING_UNKNOWN" 1 "OFF" 2 "ON" 3 "RESERVED_3" 4 "RESERVED_4" 5 "RESERVED_5" 6 "RESERVED_6" 7 "RESERVED_7" ;
VAL_TABLE_ RmtStrtHtdStCstCrStVal 0 "SETTING_UNKNOWN" 1 "OFF" 2 "ON" 3 "RESERVED_1" 4 "RESERVED_2" 5 "RESERVED_3" 6 "RESERVED_4" 7 "RESERVED_5" ;
VAL_TABLE_ RmtStrtCoolStCstCrStVal 0 "SETTING_UNKNOWN" 1 "OFF" 2 "ON" 3 "RESERVED_1" 4 "RESERVED_2" 5 "RESERVED_3" 6 "RESERVED_4" 7 "RESERVED_5" ;
VAL_TABLE_ RmtSnrfOpCstCurrSetVal 0 "Setting_Unknown" 1 "Off" 2 "On" 3 "Reserved_3" 4 "Reserved_4" 5 "Reserved_5" 6 "Reserved_6" 7 "Reserved_7" ;
VAL_TABLE_ RtLkFdbkCstCurSetVal 0 "SETTING_UNKNOWN" 1 "HORN_AND_LIGHTS_OFF" 2 "HORN_AND_LIGHTS_ON" 3 "FLASH_LIGHTS_ONLY" 4 "HORN_CHIRP_ONLY" 5 "RESERVED_5" 6 "RESERVED_6" 7 "RESERVED_7" ;
VAL_TABLE_ RmtWndOpCstCurSetVal 0 "SETTING_UNKNOWN" 1 "OFF" 2 "ON" 3 "RESERVED_3" 4 "RESERVED_4" 5 "RESERVED_5" 6 "RESERVED_6" 7 "RESERVED_7" ;
VAL_TABLE_ VehLctrLghtsCstCurSetVal 0 "SETTING_UNKNOWN" 1 "OFF" 2 "ON" 3 "RESERVED_3" 4 "RESERVED_4" 5 "RESERVED_5" 6 "RESERVED_6" 7 "RESERVED_7" ;
VAL_TABLE_ SelUlkCstCurSetVal 0 "SETTING_UNKNOWN" 1 "DRIVER_DOOR_ONLY" 2 "ALL_DOORS" 3 "RESERVED_3" 4 "RESERVED_4" 5 "RESERVED_5" 6 "RESERVED_6" 7 "RESERVED_7" ;
VAL_TABLE_ RtUlkLtFbCstCurSetVal 0 "SETTING_UNKNOWN" 1 "OFF" 2 "FLASH_LIGHTS_ON" 3 "RESERVED_3" 4 "RESERVED_4" 5 "RESERVED_5" 6 "RESERVED_6" 7 "RESERVED_7" ;
VAL_TABLE_ RemLftVehRmndrCstStAvl 0 "FALSE" 1 "TRUE" ;
VAL_TABLE_ RemInVehRmndrCstStAvl 0 "FALSE" 1 "TRUE" ;
VAL_TABLE_ TrnSwAct 0 "NO_ACTIVATION" 1 "LEFT" 2 "RIGHT" ;
VAL_TABLE_ WlkAwyLckCstCurSetVal 0 "SETTING_UNKNOWN" 1 "OFF" 2 "ON" 3 "ON_WITH_CHIRP" 4 "RESERVED_4" 5 "RESERVED_5" 6 "RESERVED_6" 7 "RESERVED_7" ;
VAL_TABLE_ SelUlkCstStAvl 0 "FALSE" 1 "TRUE" ;
VAL_TABLE_ RtUlkLtFbCstStAvl 0 "FALSE" 1 "TRUE" ;
VAL_TABLE_ RtLkFdbkCstStAvl 0 "FALSE" 1 "TRUE" ;
VAL_TABLE_ RmtWndOpCstStAvl 0 "FALSE" 1 "TRUE" ;
VAL_TABLE_ RmtStrtHtdStCstStAvl 0 "FALSE" 1 "TRUE" ;
VAL_TABLE_ RmtStrtCoolStCstStAvl 0 "FALSE" 1 "TRUE" ;
VAL_TABLE_ RmtSnrfOpCstSetAval 0 "FALSE" 1 "TRUE" ;
VAL_TABLE_ RevTltMirCstStAvl 0 "FALSE" 1 "TRUE" ;
VAL_TABLE_ WprFrActFltdStat 0 "FALSE" 1 "TRUE" ;
VAL_TABLE_ WlkAwyLckCstStAvl 0 "FALSE" 1 "TRUE" ;
VAL_TABLE_ VehLctrLghtsCstStAvl 0 "FALSE" 1 "TRUE" ;
VAL_TABLE_ TnDrvSpdLmtCstStAvl 0 "FALSE" 1 "TRUE" ;
VAL_TABLE_ TnDrvOvSpdWrnCstStAvl 0 "FALSE" 1 "TRUE" ;
VAL_TABLE_ IHVSLF_HtdBckLvl1 0 "FALSE" 1 "TRUE" ;
VAL_TABLE_ IHVSLF_HtdCushBckMd 0 "FALSE" 1 "TRUE" ;
VAL_TABLE_ IHVSLF_HtdBckLvl3 0 "FALSE" 1 "TRUE" ;
VAL_TABLE_ IHVSLF_HtdCushBckLvl3 0 "FALSE" 1 "TRUE" ;
VAL_TABLE_ IHVSLF_HtdCushBckAuto 0 "FALSE" 1 "TRUE" ;
VAL_TABLE_ IHVSLF_VntLvl1 0 "FALSE" 1 "TRUE" ;
VAL_TABLE_ IHVSLF_HtdBckAuto 0 "FALSE" 1 "TRUE" ;
VAL_TABLE_ IHVSLF_VntLvl2 0 "FALSE" 1 "TRUE" ;
VAL_TABLE_ IHVSRF_HtdBckMd 0 "FALSE" 1 "TRUE" ;
VAL_TABLE_ IHVSLF_VntLvl3 0 "FALSE" 1 "TRUE" ;
VAL_TABLE_ IHVSLF_HtdBckLvl2 0 "FALSE" 1 "TRUE" ;
VAL_TABLE_ IHVSLF_HtdBckMd 0 "FALSE" 1 "TRUE" ;
VAL_TABLE_ IHVSLF_HtdCushBckLvl1 0 "FALSE" 1 "TRUE" ;
VAL_TABLE_ IHVSLF_VntAuto 0 "FALSE" 1 "TRUE" ;
VAL_TABLE_ IHVSLF_HtdCushBckLvl2 0 "FALSE" 1 "TRUE" ;
VAL_TABLE_ IHVSLF_VntMd 0 "FALSE" 1 "TRUE" ;
VAL_TABLE_ IHVSRF_VntLvl2 0 "FALSE" 1 "TRUE" ;
VAL_TABLE_ IHVSRF_HtdCushBckMd 0 "FALSE" 1 "TRUE" ;
VAL_TABLE_ IHVSRF_HtdBckLvl3 0 "FALSE" 1 "TRUE" ;
VAL_TABLE_ IHVSRF_HtdCushBckAuto 0 "FALSE" 1 "TRUE" ;
VAL_TABLE_ IHVSRF_HtdCushBckLvl3 0 "FALSE" 1 "TRUE" ;
VAL_TABLE_ IHVSRF_HtdBckAuto 0 "FALSE" 1 "TRUE" ;
VAL_TABLE_ IHVSRF_HtdCushBckLvl1 0 "FALSE" 1 "TRUE" ;
VAL_TABLE_ IHVSRF_VntLvl1 0 "FALSE" 1 "TRUE" ;
VAL_TABLE_ TDOSWCCSV_CrSetVal 0 "SETTING_UNKNOWN" 1 "OFF" 2 "ON" 3 "RESERVED_3" 4 "RESERVED_4" 5 "RESERVED_5" 6 "RESERVED_6" 7 "RESERVED_7" ;
VAL_TABLE_ IHVSRF_VntAuto 0 "FALSE" 1 "TRUE" ;
VAL_TABLE_ IHVSRF_HtdBckLvl1 0 "FALSE" 1 "TRUE" ;
VAL_TABLE_ IHVSRF_HtdBckLvl2 0 "FALSE" 1 "TRUE" ;
VAL_TABLE_ IHVSRF_VntLvl3 0 "FALSE" 1 "TRUE" ;
VAL_TABLE_ IHVSRF_HtdCushBckLvl2 0 "FALSE" 1 "TRUE" ;
VAL_TABLE_ IHVSRF_VntMd 0 "FALSE" 1 "TRUE" ;
VAL_TABLE_ TDSLCCSV_CrSetVal 0 "SETTING_UNKNOWN" 1 "OFF" 2 "ON" 3 "RESERVED_3" 4 "RESERVED_4" 5 "RESERVED_5" 6 "RESERVED_6" 7 "RESERVED_7" ;
VAL_TABLE_ AmbtLgtMnMenuTyp 0 "Off" 1 "RGB Lighting" 2 "Ambient Brightness Only" 3 "Reserved 1" 4 "Reserved 2" 5 "Reserved 3" 6 "Reserved 4" 7 "Reserved 5" ;
VAL_TABLE_ ConThftAlrmTrg 0 "NO_DATA" 1 "DRIVER DOOR AJAR" 2 "CODRIVER DOOR AJAR" 3 "LEFT REAR DOOR AJAR" 4 "RIGHT REAR DOOR AJAR" 5 "GLASS BREAKAGE" 6 "HOOD AJAR" 7 "INTRUSION" 8 "INCLINATION" 9 "REAR CLOSURE AJAR" 10 "LIFTGLASS AJAR" 11 "TARGA AJAR" 12 "TONNEAU AJAR" 13 "VEHICLE POWER MODE" 14 "CHARGE CORD ALERT" 15 "WHEEL TAMPER" 16 "PANIC ALARM" 17 "MODULE RESET" 18 "ENHANCED SERVICES ALARM" 19 "Trailer Theft" ;
VAL_TABLE_ BattVltIRq 0 "Battery Voltage OK" 1 "Battery Voltage Low" 2 "Battery Voltage High" 3 "Battery Voltage Very Low" ;
VAL_TABLE_ AlrmClckMgrAlrmCmdFtr6 0 "InActive" 1 "Active" 2 "Expired" ;
VAL_TABLE_ BdyCtlTopSpdLimSrc 0 "None" 1 "Teen" 2 "Valet" 3 "HoodOpen" 4 "Reserved" 5 "Reserved" 6 "Reserved" 7 "Reserved" ;
VAL_TABLE_ BdyCtlTopSpdLimIndOn 0 "FALSE" 1 "TRUE" ;
VAL_TABLE_ BdyCtlAccelLimIndOn 0 "FALSE" 1 "TRUE" ;
VAL_TABLE_ BatLoStrtVehIndOn 0 "FALSE" 1 "TRUE" ;
VAL_TABLE_ AutoLgtsInActvIndOn 0 "FALSE" 1 "TRUE" ;
VAL_TABLE_ AutoLgtsActvIndOn 0 "FALSE" 1 "TRUE" ;
VAL_TABLE_ ACCmpsrOprtng 0 "FALSE" 1 "TRUE" ;
VAL_TABLE_ HtdFrntWSSt 0 "UNKNOWN" 1 "OFF" 2 "ON" ;
VAL_TABLE_ ConThftAttmpdIO 0 "FALSE" 1 "TRUE" ;
VAL_TABLE_ CnvtBkWndNotNormzIO 0 "FALSE" 1 "TRUE" ;
VAL_TABLE_ CmpSftTopMotBfrOpTrnkIO 0 "FALSE" 1 "TRUE" ;
VAL_TABLE_ CmbdDrHndlActvRF 0 "INACTIVE" 1 "ACTIVE" ;
VAL_TABLE_ CmbdDrHndlActvLF 0 "INACTIVE" 1 "ACTIVE" ;
VAL_TABLE_ ClmSysDfgRdcdIndOn 0 "FALSE" 1 "TRUE" ;
VAL_TABLE_ ClmSysDfgActvIndOn 0 "FALSE" 1 "TRUE" ;
VAL_TABLE_ ClmCtlBatSvrIndOn 0 "FALSE" 1 "TRUE" ;
VAL_TABLE_ FobProgMdStatCmplt 0 "FALSE" 1 "TRUE" ;
VAL_TABLE_ FobPrevLrndIndOn 0 "FALSE" 1 "TRUE" ;
VAL_TABLE_ FobPogLimRchdIndOn 0 "FALSE" 1 "TRUE" ;
VAL_TABLE_ EntrFobProgIndOn 0 "FALSE" 1 "TRUE" ;
VAL_TABLE_ DlydAccTmrActv 0 "FALSE" 1 "TRUE" ;
VAL_TABLE_ CrgLghtEnbldIO 0 "FALSE" 1 "TRUE" ;
VAL_TABLE_ CrgLghtDsbldIO 0 "FALSE" 1 "TRUE" ;
VAL_TABLE_ ConThftSrvcIO 0 "FALSE" 1 "TRUE" ;
VAL_TABLE_ HiVltgHtrFaildIndOn 0 "FALSE" 1 "TRUE" ;
VAL_TABLE_ HiBmIO 0 "FALSE" 1 "TRUE" ;
VAL_TABLE_ HazSwAtvIO 0 "FALSE" 1 "TRUE" ;
VAL_TABLE_ HVAC_StngsCtrlAvlbl 0 "FALSE" 1 "TRUE" ;
VAL_TABLE_ FrtSnshdNormzRqrdIO 0 "FALSE" 1 "TRUE" ;
VAL_TABLE_ FrtCmptServIndOn 0 "FALSE" 1 "TRUE" ;
VAL_TABLE_ FrtClmAppFltDtnActv 0 "FALSE" 1 "TRUE" ;
VAL_TABLE_ FuelOprtdHtrOprtgMode 0 "Unknown" 1 "Off" 2 "Parkheater" 3 "auxiliary mode" 4 "ventilation" ;
VAL_TABLE_ HtdFrtWshldUnvIndOn 0 "FALSE" 1 "TRUE" ;
VAL_TABLE_ HiVltgHtrOvrTempIndOn 0 "FALSE" 1 "TRUE" ;
VAL_TABLE_ IAQI_IntrAirQltyGasStat 0 "NoDisplay" 1 "AQIstate1" 2 "AQIstate2" 3 "AQIstate3" 4 "AQIstate4" 5 "AQIstate5" 6 "AQIstate6" 7 "NoDataAvailable" 8 "ServiceSensor" 9 "Unknown" ;
VAL_TABLE_ IAQI_IntrAirQltyOvrallStat 0 "NoDisplay" 1 "AQIstate1" 2 "AQIstate2" 3 "AQIstate3" 4 "AQIstate4" 5 "AQIstate5" 6 "AQIstate6" 7 "NoDataAvailable" 8 "ServiceSensor" 9 "Unknown" ;
VAL_TABLE_ IAQI_IntrAirQltyPrtclteStat 0 "NoDisplay" 1 "AQIstate1" 2 "AQIstate2" 3 "AQIstate3" 4 "AQIstate4" 5 "AQIstate5" 6 "AQIstate6" 7 "NoDataAvailable" 8 "ServiceSensor" 9 "Unknown" ;
VAL_TABLE_ TDRCADD_WOTEvnts 0 "FALSE" 1 "TRUE" ;
VAL_TABLE_ TDRCADD_StCtrlEvnts 0 "FALSE" 1 "TRUE" ;
VAL_TABLE_ TDRCADD_OvrSpdDistDrvn 0 "FALSE" 1 "TRUE" ;
VAL_TABLE_ TDRCADD_ABSAtvEvt 0 "FALSE" 1 "TRUE" ;
VAL_TABLE_ TDRCADD_DistDrvn 0 "FALSE" 1 "TRUE" ;
VAL_TABLE_ TDRCADD_FCHdwyAlrt 0 "FALSE" 1 "TRUE" ;
VAL_TABLE_ TDRCADD_LKAstAlrtsEvnts 0 "FALSE" 1 "TRUE" ;
VAL_TABLE_ TDRCADD_MaxSpd 0 "FALSE" 1 "TRUE" ;
VAL_TABLE_ TDRCADD_TrCtrlEvnts 0 "FALSE" 1 "TRUE" ;
VAL_TABLE_ TDRCADD_FCMBrEvts 0 "FALSE" 1 "TRUE" ;
VAL_TABLE_ TDRCADD_LDWEvnts 0 "FALSE" 1 "TRUE" ;
VAL_TABLE_ TDRCADD_RCMBrEvts 0 "FALSE" 1 "TRUE" ;
VAL_TABLE_ TDRCADD_OvSpdEvnt 0 "FALSE" 1 "TRUE" ;
VAL_TABLE_ TDRCADD_DrwDrvAlrt 0 "FALSE" 1 "TRUE" ;
VAL_TABLE_ TDRCADD_FCImntAlrts 0 "FALSE" 1 "TRUE" ;
VAL_TABLE_ TDRCADD_UnbckldDistDrvn 0 "FALSE" 1 "TRUE" ;
VAL_TABLE_ WndNormzRR 0 "FALSE" 1 "TRUE" ;
VAL_TABLE_ WndNormzRF 0 "FALSE" 1 "TRUE" ;
VAL_TABLE_ WndNormzLR 0 "FALSE" 1 "TRUE" ;
VAL_TABLE_ WndNormzLF 0 "FALSE" 1 "TRUE" ;
VAL_TABLE_ VTDDrvMsgIO 0 "FALSE" 1 "TRUE" ;
VAL_TABLE_ VTDDrvIndReq 0 "OFF" 1 "ON" 2 "0.5_Hz" 3 "1_Hz" 4 "2_Hz" 5 "4_Hz" 6 "RESERVED" ;
VAL_TABLE_ WndNtNrmzdIORR 0 "FALSE" 1 "TRUE" ;
VAL_TABLE_ WndNtNrmzdIOLR 0 "FALSE" 1 "TRUE" ;
VAL_TABLE_ WndNtNrmzdIODrv 0 "FALSE" 1 "TRUE" ;
VAL_TABLE_ WndNtNrmzdIOCoDrv 0 "FALSE" 1 "TRUE" ;
VAL_TABLE_ TirePrsStatLR 0 "Unknown" 1 "Nominal" 2 "Low - Service Now" 3 "Low" 4 "Low - Extended Mobility" 5 "High" ;
VAL_TABLE_ TirePrsStatLR_Inv 0 "FALSE" 1 "TRUE" ;
VAL_TABLE_ TirePrsStatLF 0 "Unknown" 1 "Nominal" 2 "Low - Service Now" 3 "Low" 4 "Low - Extended Mobility" 5 "High" ;
VAL_TABLE_ TirePrsStatLF_Inv 0 "FALSE" 1 "TRUE" ;
VAL_TABLE_ TirePrsStatRR 0 "Unknown" 1 "Nominal" 2 "Low - Service Now" 3 "Low" 4 "Low - Extended Mobility" 5 "High" ;
VAL_TABLE_ TirePrsStatRR_Inv 0 "FALSE" 1 "TRUE" ;
VAL_TABLE_ TirePrsStatRF 0 "Unknown" 1 "Nominal" 2 "Low - Service Now" 3 "Low" 4 "Low - Extended Mobility" 5 "High" ;
VAL_TABLE_ TirePrsStatRF_Inv 0 "FALSE" 1 "TRUE" ;
VAL_TABLE_ TrPrsMntrTrLdStat 0 "Unkown" 1 "Light Load" 2 "Best Economy Load" 3 "Max Load" ;
VAL_TABLE_ TrlrLtngSeqStat 0 "Sequence_Off" 1 "Sequence_On" ;
VAL_TABLE_ TrPrsMntrSysFld 0 "FALSE" 1 "TRUE" ;
VAL_TABLE_ TlmtcsImmbAtv 0 "FALSE" 1 "TRUE" ;
VAL_TABLE_ TirePrsLrnActIO 0 "FALSE" 1 "TRUE" ;
VAL_TABLE_ TireLocatnWarnEn 0 "FALSE" 1 "TRUE" ;
VAL_TABLE_ TPMTrLrnMdCmplt 0 "FALSE" 1 "TRUE" ;
VAL_TABLE_ ValetMdResponse 0 "No Action" 1 "Valet Active - PIN Updated" 2 "Valet Active - PIN Invalid" 3 "Valet Inactive - PIN Valid" ;
VAL_TABLE_ XmtrSecurConfRqrdIO 0 "FALSE" 1 "TRUE" ;
VAL_TABLE_ VehLoBatIndOn 0 "FALSE" 1 "TRUE" ;
VAL_TABLE_ UIDInStatusSD 0 "Not Present" 1 "Present" ;
VAL_TABLE_ TxLrnFldIO 0 "FALSE" 1 "TRUE" ;
VAL_TABLE_ TxBkUpLctIO 0 "FALSE" 1 "TRUE" ;
VAL_TABLE_ TurnWprIntIO 0 "FALSE" 1 "TRUE" ;
VAL_TABLE_ TrnstStrgLogisticsMdActivation 0 "FALSE" 1 "TRUE" ;
VAL_TABLE_ TeenDrvRsp 0 "No_Action" 1 "Teen PIN Verified" 2 "Teen PIN Updated" 3 "Teen PIN Mismatch" 4 "Teen Key Set Complete" 5 "Teen Key Clear Complete" 6 "Key Not Present" 7 "Key Detected As Teen Key" 8 "Key Detected As NOT Teen Key" 9 "PIN Locked" ;
VAL_TABLE_ TnDrvRptCrdAval 0 "FALSE" 1 "TRUE" ;
VAL_TABLE_ TnDrvPINStrd 0 "FALSE" 1 "TRUE" ;
VAL_TABLE_ TnDrvOvrSpdIO 0 "FALSE" 1 "TRUE" ;
VAL_TABLE_ RemCtrlFobNumForProg 0 "No Fob" 1 "Remote Control Fob #1" 2 "Remote Control Fob #2" 3 "Remote Control Fob #3" 4 "Remote Control Fob #4" 5 "Remote Control Fob #5" 6 "Remote Control Fob #6" 7 "Remote Control Fob #7" 8 "Remote Control Fob #8" 9 "Reserved_1" 10 "Reserved_2" 11 "Reserved_3" 12 "Reserved_4" 13 "Reserved_5" 14 "Reserved_6" 15 "Reserved_7" ;
VAL_TABLE_ DrExtHndlActnStatRR 0 "INACTIVE" 1 "ACTIVE" ;
VAL_TABLE_ DrExtHndlActnStatRF 0 "INACTIVE" 1 "ACTIVE" ;
VAL_TABLE_ SnrfPstnSts 0 "Fully Closed" 1 "Vent" 2 "Partially Open" 3 "Fully Open" 4 "Comfort Open" ;
VAL_TABLE_ ServPwrLftgtIndOn 0 "FALSE" 1 "TRUE" ;
VAL_TABLE_ ServKylsStSysIO 0 "FALSE" 1 "TRUE" ;
VAL_TABLE_ ServHtdStrgWhlIndOn 0 "FALSE" 1 "TRUE" ;
VAL_TABLE_ ServDrLtchSysIO 0 "FALSE" 1 "TRUE" ;
VAL_TABLE_ ServBatChrgSysIndOn 0 "FALSE" 1 "TRUE" ;
VAL_TABLE_ RmtCtlFobBatLoIndOn 0 "FALSE" 1 "TRUE" ;
VAL_TABLE_ DrIntHndlActnStatRR 0 "INACTIVE" 1 "ACTIVE" ;
VAL_TABLE_ DrIntHndlActnStatRF 0 "INACTIVE" 1 "ACTIVE" ;
VAL_TABLE_ TnDrvDRLOffUnbIO 0 "FALSE" 1 "TRUE" ;
VAL_TABLE_ TnDrvALCOffUnbIO 0 "FALSE" 1 "TRUE" ;
VAL_TABLE_ TeenDrvFtrAvl 0 "FALSE" 1 "TRUE" ;
VAL_TABLE_ StlthModeActv 0 "FALSE" 1 "TRUE" ;
VAL_TABLE_ StNtLtchdThrdRowIO 0 "FALSE" 1 "TRUE" ;
VAL_TABLE_ SnrfNormzRqrdIO 0 "FALSE" 1 "TRUE" ;
VAL_TABLE_ ShftoNeutIndOn 0 "FALSE" 1 "TRUE" ;
VAL_TABLE_ DrExtHndlActnStatLF 0 "INACTIVE" 1 "ACTIVE" ;
VAL_TABLE_ LstKyFbFnctnReq 0 "No Request" 1 "Remote Door Unlock Request" 2 "Remote Door Lock Request" 3 "Remote Start Request" 4 "Remote Stop Request" 5 "Remote Rear Closure Release Request" 6 "Remote Power Rear Closure Start Request" 7 "Remote Power Rear Closure Stop Request" 8 "Remote Fuel Operated Heater Request Off" 9 "RFA Mirror Unfold Request" 10 "RFA Mirror Fold Request" 11 "RFA Window Open Request" 12 "RFA Windows Close Request" 13 "Remote Fuel Operated Heater Request On" 14 "Remote Power Top Open" 15 "Remote Power Top Close" 16 "Remote Power Top Pause" 17 "Remote Power Top Stop" 18 "Remote Panic Alarm" 19 "Remote Locator Alarm" 20 "Remote Front Closure Release Request" ;
VAL_TABLE_ IndLowSpdPlltnTkngRecircActMsg 0 "FALSE" 1 "TRUE" ;
VAL_TABLE_ IndIntrAirQltyDispActv 0 "FALSE" 1 "TRUE" ;
VAL_TABLE_ IndFogPrtcTkngFrshAirActMsg 0 "FALSE" 1 "TRUE" ;
VAL_TABLE_ IndAirQltSysTkngRecircActMsg 0 "FALSE" 1 "TRUE" ;
VAL_TABLE_ IndAC_OnBatCoolMsg 0 "FALSE" 1 "TRUE" ;
VAL_TABLE_ DrIntHndlActnStatLR 0 "INACTIVE" 1 "ACTIVE" ;
VAL_TABLE_ DrIntHndlActnStatLF 0 "INACTIVE" 1 "ACTIVE" ;
VAL_TABLE_ DrExtHndlActnStatLR 0 "INACTIVE" 1 "ACTIVE" ;
VAL_TABLE_ PwrLftgtOffIndOn 0 "FALSE" 1 "TRUE" ;
VAL_TABLE_ PrkLmpIO 0 "FALSE" 1 "TRUE" ;
VAL_TABLE_ NghtSchmAtv 0 "FALSE" 1 "TRUE" ;
VAL_TABLE_ LdShedRdcdFtrsIndOn 0 "FALSE" 1 "TRUE" ;
VAL_TABLE_ KyIdDevNotPrIO 0 "FALSE" 1 "TRUE" ;
VAL_TABLE_ KeyInWrnIO 0 "FALSE" 1 "TRUE" ;
VAL_TABLE_ IntrSnsDsbld 0 "FALSE" 1 "TRUE" ;
VAL_TABLE_ IndTmpUnts 0 "Celcius" 1 "Fahrenheit" ;
VAL_TABLE_ IndInzrStat 0 "OFF" 1 "Ionizer ON" 2 "Ionizer OFF" 3 "Ionizer LO" 4 "Ionizer HI" ;
VAL_TABLE_ RrStRmndrIndOn 0 "FALSE" 1 "TRUE" ;
VAL_TABLE_ RrSnshdNormzRqrdIO 0 "FALSE" 1 "TRUE" ;
VAL_TABLE_ RrDrUnlckIO 0 "FALSE" 1 "TRUE" ;
VAL_TABLE_ RnSnsOffIO 0 "FALSE" 1 "TRUE" ;
VAL_TABLE_ RnSnsActIO 0 "FALSE" 1 "TRUE" ;
VAL_TABLE_ PwrLftgtUnvIndOn 0 "FALSE" 1 "TRUE" ;
VAL_TABLE_ AutDrvLckCstAvlFlg1 0 "FALSE" 1 "TRUE" ;
VAL_TABLE_ AirQltySnsCstAvlFlg7 0 "FALSE" 1 "TRUE" ;
VAL_TABLE_ AirQltySnsCstAvlFlg6 0 "FALSE" 1 "TRUE" ;
VAL_TABLE_ AirQltySnsCstAvlFlg5 0 "FALSE" 1 "TRUE" ;
VAL_TABLE_ AirQltySnsCstAvlFlg4 0 "FALSE" 1 "TRUE" ;
VAL_TABLE_ AirQltySnsCstAvlFlg3 0 "FALSE" 1 "TRUE" ;
VAL_TABLE_ AirQltySnsCstAvlFlg2 0 "FALSE" 1 "TRUE" ;
VAL_TABLE_ AirQltySnsCstAvlFlg1 0 "FALSE" 1 "TRUE" ;
VAL_TABLE_ AutMirFldCstAvlFlg2 0 "FALSE" 1 "TRUE" ;
VAL_TABLE_ AutMirFldCstAvlFlg1 0 "FALSE" 1 "TRUE" ;
VAL_TABLE_ AutDrvLckCstAvlFlg7 0 "FALSE" 1 "TRUE" ;
VAL_TABLE_ AutDrvLckCstAvlFlg6 0 "FALSE" 1 "TRUE" ;
VAL_TABLE_ AutDrvLckCstAvlFlg5 0 "FALSE" 1 "TRUE" ;
VAL_TABLE_ AutDrvLckCstAvlFlg4 0 "FALSE" 1 "TRUE" ;
VAL_TABLE_ AutDrvLckCstAvlFlg3 0 "FALSE" 1 "TRUE" ;
VAL_TABLE_ AutDrvLckCstAvlFlg2 0 "FALSE" 1 "TRUE" ;
VAL_TABLE_ AutUnlckCstAvlFlg3 0 "FALSE" 1 "TRUE" ;
VAL_TABLE_ AutUnlckCstAvlFlg2 0 "FALSE" 1 "TRUE" ;
VAL_TABLE_ AutUnlckCstAvlFlg1 0 "FALSE" 1 "TRUE" ;
VAL_TABLE_ AutMirFldCstAvlFlg7 0 "FALSE" 1 "TRUE" ;
VAL_TABLE_ AutMirFldCstAvlFlg6 0 "FALSE" 1 "TRUE" ;
VAL_TABLE_ AutMirFldCstAvlFlg5 0 "FALSE" 1 "TRUE" ;
VAL_TABLE_ AutMirFldCstAvlFlg4 0 "FALSE" 1 "TRUE" ;
VAL_TABLE_ AutMirFldCstAvlFlg3 0 "FALSE" 1 "TRUE" ;
VAL_TABLE_ AutoAirDstCstAvlFlg4 0 "FALSE" 1 "TRUE" ;
VAL_TABLE_ AutoAirDstCstAvlFlg3 0 "FALSE" 1 "TRUE" ;
VAL_TABLE_ AutoAirDstCstAvlFlg2 0 "FALSE" 1 "TRUE" ;
VAL_TABLE_ AutoAirDstCstAvlFlg1 0 "FALSE" 1 "TRUE" ;
VAL_TABLE_ AutUnlckCstAvlFlg7 0 "FALSE" 1 "TRUE" ;
VAL_TABLE_ AutUnlckCstAvlFlg6 0 "FALSE" 1 "TRUE" ;
VAL_TABLE_ AutUnlckCstAvlFlg5 0 "FALSE" 1 "TRUE" ;
VAL_TABLE_ AutUnlckCstAvlFlg4 0 "FALSE" 1 "TRUE" ;
VAL_TABLE_ AutoCoolStCstAvlFlg5 0 "FALSE" 1 "TRUE" ;
VAL_TABLE_ AutoCoolStCstAvlFlg4 0 "FALSE" 1 "TRUE" ;
VAL_TABLE_ AutoCoolStCstAvlFlg3 0 "FALSE" 1 "TRUE" ;
VAL_TABLE_ AutoCoolStCstAvlFlg2 0 "FALSE" 1 "TRUE" ;
VAL_TABLE_ AutoCoolStCstAvlFlg1 0 "FALSE" 1 "TRUE" ;
VAL_TABLE_ AutoAirDstCstAvlFlg7 0 "FALSE" 1 "TRUE" ;
VAL_TABLE_ AutoAirDstCstAvlFlg6 0 "FALSE" 1 "TRUE" ;
VAL_TABLE_ AutoAirDstCstAvlFlg5 0 "FALSE" 1 "TRUE" ;
VAL_TABLE_ AutoDfgCstAvlFlg6 0 "FALSE" 1 "TRUE" ;
VAL_TABLE_ AutoDfgCstAvlFlg5 0 "FALSE" 1 "TRUE" ;
VAL_TABLE_ AutoDfgCstAvlFlg4 0 "FALSE" 1 "TRUE" ;
VAL_TABLE_ AutoDfgCstAvlFlg3 0 "FALSE" 1 "TRUE" ;
VAL_TABLE_ AutoDfgCstAvlFlg2 0 "FALSE" 1 "TRUE" ;
VAL_TABLE_ AutoDfgCstAvlFlg1 0 "FALSE" 1 "TRUE" ;
VAL_TABLE_ AutoCoolStCstAvlFlg7 0 "FALSE" 1 "TRUE" ;
VAL_TABLE_ AutoCoolStCstAvlFlg6 0 "FALSE" 1 "TRUE" ;
VAL_TABLE_ AutoFanCstAvlFlg7 0 "FALSE" 1 "TRUE" ;
VAL_TABLE_ AutoFanCstAvlFlg6 0 "FALSE" 1 "TRUE" ;
VAL_TABLE_ AutoFanCstAvlFlg5 0 "FALSE" 1 "TRUE" ;
VAL_TABLE_ AutoFanCstAvlFlg4 0 "FALSE" 1 "TRUE" ;
VAL_TABLE_ AutoFanCstAvlFlg3 0 "FALSE" 1 "TRUE" ;
VAL_TABLE_ AutoFanCstAvlFlg2 0 "FALSE" 1 "TRUE" ;
VAL_TABLE_ AutoFanCstAvlFlg1 0 "FALSE" 1 "TRUE" ;
VAL_TABLE_ AutoDfgCstAvlFlg7 0 "FALSE" 1 "TRUE" ;
VAL_TABLE_ AutoHtdStCstAvlFlg7 0 "FALSE" 1 "TRUE" ;
VAL_TABLE_ AutoHtdStCstAvlFlg6 0 "FALSE" 1 "TRUE" ;
VAL_TABLE_ AutoHtdStCstAvlFlg5 0 "FALSE" 1 "TRUE" ;
VAL_TABLE_ AutoHtdStCstAvlFlg4 0 "FALSE" 1 "TRUE" ;
VAL_TABLE_ AutoHtdStCstAvlFlg3 0 "FALSE" 1 "TRUE" ;
VAL_TABLE_ AutoHtdStCstAvlFlg2 0 "FALSE" 1 "TRUE" ;
VAL_TABLE_ AutoHtdStCstAvlFlg1 0 "FALSE" 1 "TRUE" ;
VAL_TABLE_ AutoRrWpCstAvlFlg7 0 "FALSE" 1 "TRUE" ;
VAL_TABLE_ AutoRrWpCstAvlFlg6 0 "FALSE" 1 "TRUE" ;
VAL_TABLE_ AutoRrWpCstAvlFlg5 0 "FALSE" 1 "TRUE" ;
VAL_TABLE_ AutoRrWpCstAvlFlg4 0 "FALSE" 1 "TRUE" ;
VAL_TABLE_ AutoRrWpCstAvlFlg3 0 "FALSE" 1 "TRUE" ;
VAL_TABLE_ AutoRrWpCstAvlFlg2 0 "FALSE" 1 "TRUE" ;
VAL_TABLE_ AutoRrWpCstAvlFlg1 0 "FALSE" 1 "TRUE" ;
VAL_TABLE_ ExtLghtCstAvlFlg1 0 "FALSE" 1 "TRUE" ;
VAL_TABLE_ DaytimeTlLghtsCstAvlFlg7 0 "FALSE" 1 "TRUE" ;
VAL_TABLE_ DaytimeTlLghtsCstAvlFlg6 0 "FALSE" 1 "TRUE" ;
VAL_TABLE_ DaytimeTlLghtsCstAvlFlg5 0 "FALSE" 1 "TRUE" ;
VAL_TABLE_ DaytimeTlLghtsCstAvlFlg4 0 "FALSE" 1 "TRUE" ;
VAL_TABLE_ DaytimeTlLghtsCstAvlFlg3 0 "FALSE" 1 "TRUE" ;
VAL_TABLE_ DaytimeTlLghtsCstAvlFlg2 0 "FALSE" 1 "TRUE" ;
VAL_TABLE_ DaytimeTlLghtsCstAvlFlg1 0 "FALSE" 1 "TRUE" ;
VAL_TABLE_ HFRCCstAvlFlg2 0 "FALSE" 1 "TRUE" ;
VAL_TABLE_ HFRCCstAvlFlg1 0 "FALSE" 1 "TRUE" ;
VAL_TABLE_ ExtLghtCstAvlFlg7 0 "FALSE" 1 "TRUE" ;
VAL_TABLE_ ExtLghtCstAvlFlg6 0 "FALSE" 1 "TRUE" ;
VAL_TABLE_ ExtLghtCstAvlFlg5 0 "FALSE" 1 "TRUE" ;
VAL_TABLE_ ExtLghtCstAvlFlg4 0 "FALSE" 1 "TRUE" ;
VAL_TABLE_ ExtLghtCstAvlFlg3 0 "FALSE" 1 "TRUE" ;
VAL_TABLE_ ExtLghtCstAvlFlg2 0 "FALSE" 1 "TRUE" ;
VAL_TABLE_ HFRCCstAvlFlg7 0 "FALSE" 1 "TRUE" ;
VAL_TABLE_ HFRCCstAvlFlg6 0 "FALSE" 1 "TRUE" ;
VAL_TABLE_ HFRCCstAvlFlg5 0 "FALSE" 1 "TRUE" ;
VAL_TABLE_ HFRCCstAvlFlg4 0 "FALSE" 1 "TRUE" ;
VAL_TABLE_ HFRCCstAvlFlg3 0 "FALSE" 1 "TRUE" ;
VAL_TABLE_ IonzrCtrlCstAvlFlg4 0 "FALSE" 1 "TRUE" ;
VAL_TABLE_ IonzrCtrlCstAvlFlg3 0 "FALSE" 1 "TRUE" ;
VAL_TABLE_ IonzrCtrlCstAvlFlg2 0 "FALSE" 1 "TRUE" ;
VAL_TABLE_ IonzrCtrlCstAvlFlg1 0 "FALSE" 1 "TRUE" ;
VAL_TABLE_ LDCLCstAvlFlg5 0 "FALSE" 1 "TRUE" ;
VAL_TABLE_ LDCLCstAvlFlg4 0 "FALSE" 1 "TRUE" ;
VAL_TABLE_ LDCLCstAvlFlg3 0 "FALSE" 1 "TRUE" ;
VAL_TABLE_ LDCLCstAvlFlg2 0 "FALSE" 1 "TRUE" ;
VAL_TABLE_ LDCLCstAvlFlg1 0 "FALSE" 1 "TRUE" ;
VAL_TABLE_ IonzrCtrlCstAvlFlg7 0 "FALSE" 1 "TRUE" ;
VAL_TABLE_ IonzrCtrlCstAvlFlg6 0 "FALSE" 1 "TRUE" ;
VAL_TABLE_ IonzrCtrlCstAvlFlg5 0 "FALSE" 1 "TRUE" ;
VAL_TABLE_ OpDrAtLOCstAvlFlg6 0 "FALSE" 1 "TRUE" ;
VAL_TABLE_ OpDrAtLOCstAvlFlg5 0 "FALSE" 1 "TRUE" ;
VAL_TABLE_ OpDrAtLOCstAvlFlg4 0 "FALSE" 1 "TRUE" ;
VAL_TABLE_ OpDrAtLOCstAvlFlg3 0 "FALSE" 1 "TRUE" ;
VAL_TABLE_ OpDrAtLOCstAvlFlg2 0 "FALSE" 1 "TRUE" ;
VAL_TABLE_ OpDrAtLOCstAvlFlg1 0 "FALSE" 1 "TRUE" ;
VAL_TABLE_ LDCLCstAvlFlg7 0 "FALSE" 1 "TRUE" ;
VAL_TABLE_ LDCLCstAvlFlg6 0 "FALSE" 1 "TRUE" ;
VAL_TABLE_ PlltnCtrlCstAvlFlg7 0 "FALSE" 1 "TRUE" ;
VAL_TABLE_ PlltnCtrlCstAvlFlg6 0 "FALSE" 1 "TRUE" ;
VAL_TABLE_ PlltnCtrlCstAvlFlg5 0 "FALSE" 1 "TRUE" ;
VAL_TABLE_ PlltnCtrlCstAvlFlg4 0 "FALSE" 1 "TRUE" ;
VAL_TABLE_ PlltnCtrlCstAvlFlg3 0 "FALSE" 1 "TRUE" ;
VAL_TABLE_ PlltnCtrlCstAvlFlg2 0 "FALSE" 1 "TRUE" ;
VAL_TABLE_ PlltnCtrlCstAvlFlg1 0 "FALSE" 1 "TRUE" ;
VAL_TABLE_ OpDrAtLOCstAvlFlg7 0 "FALSE" 1 "TRUE" ;
VAL_TABLE_ PsvUnlckCstAvlFlg7 0 "FALSE" 1 "TRUE" ;
VAL_TABLE_ PsvUnlckCstAvlFlg6 0 "FALSE" 1 "TRUE" ;
VAL_TABLE_ PsvUnlckCstAvlFlg5 0 "FALSE" 1 "TRUE" ;
VAL_TABLE_ PsvUnlckCstAvlFlg4 0 "FALSE" 1 "TRUE" ;
VAL_TABLE_ PsvUnlckCstAvlFlg3 0 "FALSE" 1 "TRUE" ;
VAL_TABLE_ PsvUnlckCstAvlFlg2 0 "FALSE" 1 "TRUE" ;
VAL_TABLE_ PsvUnlckCstAvlFlg1 0 "FALSE" 1 "TRUE" ;
VAL_TABLE_ RlkRtUlkDrCstAvlFlg1 0 "FALSE" 1 "TRUE" ;
VAL_TABLE_ RemInVehRmndrCstAvlFlg7 0 "FALSE" 1 "TRUE" ;
VAL_TABLE_ RemInVehRmndrCstAvlFlg6 0 "FALSE" 1 "TRUE" ;
VAL_TABLE_ RemInVehRmndrCstAvlFlg5 0 "FALSE" 1 "TRUE" ;
VAL_TABLE_ RemInVehRmndrCstAvlFlg4 0 "FALSE" 1 "TRUE" ;
VAL_TABLE_ RemInVehRmndrCstAvlFlg3 0 "FALSE" 1 "TRUE" ;
VAL_TABLE_ RemInVehRmndrCstAvlFlg2 0 "FALSE" 1 "TRUE" ;
VAL_TABLE_ RemInVehRmndrCstAvlFlg1 0 "FALSE" 1 "TRUE" ;
VAL_TABLE_ RmtSnrfOpCstAvlFlg2 0 "FALSE" 1 "TRUE" ;
VAL_TABLE_ RmtSnrfOpCstAvlFlg1 0 "FALSE" 1 "TRUE" ;
VAL_TABLE_ RlkRtUlkDrCstAvlFlg7 0 "FALSE" 1 "TRUE" ;
VAL_TABLE_ RlkRtUlkDrCstAvlFlg6 0 "FALSE" 1 "TRUE" ;
VAL_TABLE_ RlkRtUlkDrCstAvlFlg5 0 "FALSE" 1 "TRUE" ;
VAL_TABLE_ RlkRtUlkDrCstAvlFlg4 0 "FALSE" 1 "TRUE" ;
VAL_TABLE_ RlkRtUlkDrCstAvlFlg3 0 "FALSE" 1 "TRUE" ;
VAL_TABLE_ RlkRtUlkDrCstAvlFlg2 0 "FALSE" 1 "TRUE" ;
VAL_TABLE_ RmtStrtCoolStCstAvlFlg3 0 "FALSE" 1 "TRUE" ;
VAL_TABLE_ RmtStrtCoolStCstAvlFlg2 0 "FALSE" 1 "TRUE" ;
VAL_TABLE_ RmtStrtCoolStCstAvlFlg1 0 "FALSE" 1 "TRUE" ;
VAL_TABLE_ RmtSnrfOpCstAvlFlg7 0 "FALSE" 1 "TRUE" ;
VAL_TABLE_ RmtSnrfOpCstAvlFlg6 0 "FALSE" 1 "TRUE" ;
VAL_TABLE_ RmtSnrfOpCstAvlFlg5 0 "FALSE" 1 "TRUE" ;
VAL_TABLE_ RmtSnrfOpCstAvlFlg4 0 "FALSE" 1 "TRUE" ;
VAL_TABLE_ RmtSnrfOpCstAvlFlg3 0 "FALSE" 1 "TRUE" ;
VAL_TABLE_ RmtStrtHtdStCstAvlFlg4 0 "FALSE" 1 "TRUE" ;
VAL_TABLE_ RmtStrtHtdStCstAvlFlg3 0 "FALSE" 1 "TRUE" ;
VAL_TABLE_ RmtStrtHtdStCstAvlFlg2 0 "FALSE" 1 "TRUE" ;
VAL_TABLE_ RmtStrtHtdStCstAvlFlg1 0 "FALSE" 1 "TRUE" ;
VAL_TABLE_ RmtStrtCoolStCstAvlFlg7 0 "FALSE" 1 "TRUE" ;
VAL_TABLE_ RmtStrtCoolStCstAvlFlg6 0 "FALSE" 1 "TRUE" ;
VAL_TABLE_ RmtStrtCoolStCstAvlFlg5 0 "FALSE" 1 "TRUE" ;
VAL_TABLE_ RmtStrtCoolStCstAvlFlg4 0 "FALSE" 1 "TRUE" ;
VAL_TABLE_ RnSnsCstAvlFlg5 0 "FALSE" 1 "TRUE" ;
VAL_TABLE_ RnSnsCstAvlFlg4 0 "FALSE" 1 "TRUE" ;
VAL_TABLE_ RnSnsCstAvlFlg3 0 "FALSE" 1 "TRUE" ;
VAL_TABLE_ RnSnsCstAvlFlg2 0 "FALSE" 1 "TRUE" ;
VAL_TABLE_ RnSnsCstAvlFlg1 0 "FALSE" 1 "TRUE" ;
VAL_TABLE_ RmtStrtHtdStCstAvlFlg7 0 "FALSE" 1 "TRUE" ;
VAL_TABLE_ RmtStrtHtdStCstAvlFlg6 0 "FALSE" 1 "TRUE" ;
VAL_TABLE_ RmtStrtHtdStCstAvlFlg5 0 "FALSE" 1 "TRUE" ;
VAL_TABLE_ RrDfgStUpCstAvlFlg6 0 "FALSE" 1 "TRUE" ;
VAL_TABLE_ RrDfgStUpCstAvlFlg5 0 "FALSE" 1 "TRUE" ;
VAL_TABLE_ RrDfgStUpCstAvlFlg4 0 "FALSE" 1 "TRUE" ;
VAL_TABLE_ RrDfgStUpCstAvlFlg3 0 "FALSE" 1 "TRUE" ;
VAL_TABLE_ RrDfgStUpCstAvlFlg2 0 "FALSE" 1 "TRUE" ;
VAL_TABLE_ RrDfgStUpCstAvlFlg1 0 "FALSE" 1 "TRUE" ;
VAL_TABLE_ RnSnsCstAvlFlg7 0 "FALSE" 1 "TRUE" ;
VAL_TABLE_ RnSnsCstAvlFlg6 0 "FALSE" 1 "TRUE" ;
VAL_TABLE_ RrStRmndrEnblDsblCstAvlFlg7 0 "FALSE" 1 "TRUE" ;
VAL_TABLE_ RrStRmndrEnblDsblCstAvlFlg6 0 "FALSE" 1 "TRUE" ;
VAL_TABLE_ RrStRmndrEnblDsblCstAvlFlg5 0 "FALSE" 1 "TRUE" ;
VAL_TABLE_ RrStRmndrEnblDsblCstAvlFlg4 0 "FALSE" 1 "TRUE" ;
VAL_TABLE_ RrStRmndrEnblDsblCstAvlFlg3 0 "FALSE" 1 "TRUE" ;
VAL_TABLE_ RrStRmndrEnblDsblCstAvlFlg2 0 "FALSE" 1 "TRUE" ;
VAL_TABLE_ RrStRmndrEnblDsblCstAvlFlg1 0 "FALSE" 1 "TRUE" ;
VAL_TABLE_ RrDfgStUpCstAvlFlg7 0 "FALSE" 1 "TRUE" ;
VAL_TABLE_ RrZnStUpCstAvlFlg7 0 "FALSE" 1 "TRUE" ;
VAL_TABLE_ RrZnStUpCstAvlFlg6 0 "FALSE" 1 "TRUE" ;
VAL_TABLE_ RrZnStUpCstAvlFlg5 0 "FALSE" 1 "TRUE" ;
VAL_TABLE_ RrZnStUpCstAvlFlg4 0 "FALSE" 1 "TRUE" ;
VAL_TABLE_ RrZnStUpCstAvlFlg3 0 "FALSE" 1 "TRUE" ;
VAL_TABLE_ RrZnStUpCstAvlFlg2 0 "FALSE" 1 "TRUE" ;
VAL_TABLE_ RrZnStUpCstAvlFlg1 0 "FALSE" 1 "TRUE" ;
VAL_TABLE_ RemLftVehRmndrCstAvlFlg6 0 "FALSE" 1 "TRUE" ;
VAL_TABLE_ RemLftVehRmndrCstAvlFlg5 0 "FALSE" 1 "TRUE" ;
VAL_TABLE_ RemLftVehRmndrCstAvlFlg4 0 "FALSE" 1 "TRUE" ;
VAL_TABLE_ RemLftVehRmndrCstAvlFlg3 0 "FALSE" 1 "TRUE" ;
VAL_TABLE_ RemLftVehRmndrCstAvlFlg2 0 "FALSE" 1 "TRUE" ;
VAL_TABLE_ RemLftVehRmndrCstAvlFlg1 0 "FALSE" 1 "TRUE" ;
VAL_TABLE_ RVCBatSOCOver 0 "None" 1 "Plant Assembly Mode" 2 "Charge Recovery Mode" 3 "Default Mode" ;
VAL_TABLE_ RevTltMirCstAvlFlg7 0 "FALSE" 1 "TRUE" ;
VAL_TABLE_ RevTltMirCstAvlFlg6 0 "FALSE" 1 "TRUE" ;
VAL_TABLE_ RevTltMirCstAvlFlg5 0 "FALSE" 1 "TRUE" ;
VAL_TABLE_ RevTltMirCstAvlFlg4 0 "FALSE" 1 "TRUE" ;
VAL_TABLE_ RevTltMirCstAvlFlg3 0 "FALSE" 1 "TRUE" ;
VAL_TABLE_ RevTltMirCstAvlFlg2 0 "FALSE" 1 "TRUE" ;
VAL_TABLE_ RevTltMirCstAvlFlg1 0 "FALSE" 1 "TRUE" ;
VAL_TABLE_ RemLftVehRmndrCstAvlFlg7 0 "FALSE" 1 "TRUE" ;
VAL_TABLE_ RtLkFdbkCstAvlFlg1 0 "FALSE" 1 "TRUE" ;
VAL_TABLE_ RmtWndOpCstAvlFlg7 0 "FALSE" 1 "TRUE" ;
VAL_TABLE_ RmtWndOpCstAvlFlg6 0 "FALSE" 1 "TRUE" ;
VAL_TABLE_ RmtWndOpCstAvlFlg5 0 "FALSE" 1 "TRUE" ;
VAL_TABLE_ RmtWndOpCstAvlFlg4 0 "FALSE" 1 "TRUE" ;
VAL_TABLE_ RmtWndOpCstAvlFlg3 0 "FALSE" 1 "TRUE" ;
VAL_TABLE_ RmtWndOpCstAvlFlg2 0 "FALSE" 1 "TRUE" ;
VAL_TABLE_ RmtWndOpCstAvlFlg1 0 "FALSE" 1 "TRUE" ;
VAL_TABLE_ RtUlkLtFbCstAvlFlg2 0 "FALSE" 1 "TRUE" ;
VAL_TABLE_ RtUlkLtFbCstAvlFlg1 0 "FALSE" 1 "TRUE" ;
VAL_TABLE_ RtLkFdbkCstAvlFlg7 0 "FALSE" 1 "TRUE" ;
VAL_TABLE_ RtLkFdbkCstAvlFlg6 0 "FALSE" 1 "TRUE" ;
VAL_TABLE_ RtLkFdbkCstAvlFlg5 0 "FALSE" 1 "TRUE" ;
VAL_TABLE_ RtLkFdbkCstAvlFlg4 0 "FALSE" 1 "TRUE" ;
VAL_TABLE_ RtLkFdbkCstAvlFlg3 0 "FALSE" 1 "TRUE" ;
VAL_TABLE_ RtLkFdbkCstAvlFlg2 0 "FALSE" 1 "TRUE" ;
VAL_TABLE_ SelUlkCstAvlFlg3 0 "FALSE" 1 "TRUE" ;
VAL_TABLE_ SelUlkCstAvlFlg2 0 "FALSE" 1 "TRUE" ;
VAL_TABLE_ SelUlkCstAvlFlg1 0 "FALSE" 1 "TRUE" ;
VAL_TABLE_ RtUlkLtFbCstAvlFlg7 0 "FALSE" 1 "TRUE" ;
VAL_TABLE_ RtUlkLtFbCstAvlFlg6 0 "FALSE" 1 "TRUE" ;
VAL_TABLE_ RtUlkLtFbCstAvlFlg5 0 "FALSE" 1 "TRUE" ;
VAL_TABLE_ RtUlkLtFbCstAvlFlg4 0 "FALSE" 1 "TRUE" ;
VAL_TABLE_ RtUlkLtFbCstAvlFlg3 0 "FALSE" 1 "TRUE" ;
VAL_TABLE_ SelUlkCstAvlFlg7 0 "FALSE" 1 "TRUE" ;
VAL_TABLE_ SelUlkCstAvlFlg6 0 "FALSE" 1 "TRUE" ;
VAL_TABLE_ SelUlkCstAvlFlg5 0 "FALSE" 1 "TRUE" ;
VAL_TABLE_ SelUlkCstAvlFlg4 0 "FALSE" 1 "TRUE" ;
VAL_TABLE_ IDCTA_ClrTyp20Avl 0 "FALSE" 1 "TRUE" ;
VAL_TABLE_ IDCTA_ClrTyp28Avl 0 "FALSE" 1 "TRUE" ;
VAL_TABLE_ IDCTA_ClrTyp15Avl 0 "FALSE" 1 "TRUE" ;
VAL_TABLE_ IDCTA_ClrTyp30Avl 0 "FALSE" 1 "TRUE" ;
VAL_TABLE_ IDCTA_ClrTyp13Avl 0 "FALSE" 1 "TRUE" ;
VAL_TABLE_ IDCTA_ClrTyp22Avl 0 "FALSE" 1 "TRUE" ;
VAL_TABLE_ IDCTA_ClrTyp17Avl 0 "FALSE" 1 "TRUE" ;
VAL_TABLE_ IDCTA_OffAvl 0 "FALSE" 1 "TRUE" ;
VAL_TABLE_ IDCTA_ClrTyp29Avl 0 "FALSE" 1 "TRUE" ;
VAL_TABLE_ IDCTA_ClrTyp8Avl 0 "FALSE" 1 "TRUE" ;
VAL_TABLE_ IDCTA_ClrTyp27Avl 0 "FALSE" 1 "TRUE" ;
VAL_TABLE_ IDCTA_ClrTyp1Avl 0 "FALSE" 1 "TRUE" ;
VAL_TABLE_ IDCTA_ClrTyp14Avl 0 "FALSE" 1 "TRUE" ;
VAL_TABLE_ IDCTA_ClrTyp25Avl 0 "FALSE" 1 "TRUE" ;
VAL_TABLE_ IDCTA_ClrTyp3Avl 0 "FALSE" 1 "TRUE" ;
VAL_TABLE_ IDCTA_ClrTyp12Avl 0 "FALSE" 1 "TRUE" ;
VAL_TABLE_ IDCTA_ClrTyp18Avl 0 "FALSE" 1 "TRUE" ;
VAL_TABLE_ IDCTA_ClrTyp9Avl 0 "FALSE" 1 "TRUE" ;
VAL_TABLE_ IDCTA_ClrTyp16Avl 0 "FALSE" 1 "TRUE" ;
VAL_TABLE_ IDCTA_ClrTyp21Avl 0 "FALSE" 1 "TRUE" ;
VAL_TABLE_ IDCTA_ClrTyp11Avl 0 "FALSE" 1 "TRUE" ;
VAL_TABLE_ IDCTA_ClrTyp5Avl 0 "FALSE" 1 "TRUE" ;
VAL_TABLE_ IDCTA_ClrTyp24Avl 0 "FALSE" 1 "TRUE" ;
VAL_TABLE_ IDCTA_ClrTyp7Avl 0 "FALSE" 1 "TRUE" ;
VAL_TABLE_ IDATA_AnmTyp10Avl 0 "FALSE" 1 "TRUE" ;
VAL_TABLE_ IDCTA_ClrTyp23Avl 0 "FALSE" 1 "TRUE" ;
VAL_TABLE_ IDCTA_ClrTyp19Avl 0 "FALSE" 1 "TRUE" ;
VAL_TABLE_ IDCTA_ClrTyp26Avl 0 "FALSE" 1 "TRUE" ;
VAL_TABLE_ IDCTA_ClrTyp2Avl 0 "FALSE" 1 "TRUE" ;
VAL_TABLE_ IDCTA_ClrTyp6Avl 0 "FALSE" 1 "TRUE" ;
VAL_TABLE_ IDCTA_ClrTyp4Avl 0 "FALSE" 1 "TRUE" ;
VAL_TABLE_ IDCTA_ClrTyp10Avl 0 "FALSE" 1 "TRUE" ;
VAL_TABLE_ IDATA_AnmTyp7Avl 0 "FALSE" 1 "TRUE" ;
VAL_TABLE_ IDATA_AnmTyp9Avl 0 "FALSE" 1 "TRUE" ;
VAL_TABLE_ IDATA_AnmTyp3Avl 0 "FALSE" 1 "TRUE" ;
VAL_TABLE_ IDATA_AnmTyp14Avl 0 "FALSE" 1 "TRUE" ;
VAL_TABLE_ IDATA_AnmTyp12Avl 0 "FALSE" 1 "TRUE" ;
VAL_TABLE_ IDATA_OffAvl 0 "FALSE" 1 "TRUE" ;
VAL_TABLE_ IDATA_AnmTyp8Avl 0 "FALSE" 1 "TRUE" ;
VAL_TABLE_ IDATA_AnmTyp13Avl 0 "FALSE" 1 "TRUE" ;
VAL_TABLE_ WlkAwyLckCstAvlFlg2 0 "FALSE" 1 "TRUE" ;
VAL_TABLE_ WlkAwyLckCstAvlFlg1 0 "FALSE" 1 "TRUE" ;
VAL_TABLE_ IDATA_AnmTyp2Avl 0 "FALSE" 1 "TRUE" ;
VAL_TABLE_ IDATA_AnmTyp4Avl 0 "FALSE" 1 "TRUE" ;
VAL_TABLE_ IDATA_AnmTyp5Avl 0 "FALSE" 1 "TRUE" ;
VAL_TABLE_ IDATA_AnmTyp1Avl 0 "FALSE" 1 "TRUE" ;
VAL_TABLE_ IDATA_AnmTyp6Avl 0 "FALSE" 1 "TRUE" ;
VAL_TABLE_ IDATA_AnmTyp11Avl 0 "FALSE" 1 "TRUE" ;
VAL_TABLE_ WlkAwyLckCstAvlFlg7 0 "FALSE" 1 "TRUE" ;
VAL_TABLE_ WlkAwyLckCstAvlFlg6 0 "FALSE" 1 "TRUE" ;
VAL_TABLE_ WlkAwyLckCstAvlFlg5 0 "FALSE" 1 "TRUE" ;
VAL_TABLE_ WlkAwyLckCstAvlFlg4 0 "FALSE" 1 "TRUE" ;
VAL_TABLE_ WlkAwyLckCstAvlFlg3 0 "FALSE" 1 "TRUE" ;
VAL_TABLE_ TrlrTireRRPres_Inv 0 "FALSE" 1 "TRUE" ;
VAL_TABLE_ TrlrTireRRTemp_Inv 0 "FALSE" 1 "TRUE" ;
VAL_TABLE_ VehLctrLghtsCstAvlFlg2 0 "FALSE" 1 "TRUE" ;
VAL_TABLE_ VehLctrLghtsCstAvlFlg1 0 "FALSE" 1 "TRUE" ;
VAL_TABLE_ TrlrTireRRPresSts 0 "Unknown" 1 "Normal" 2 "Low Pressure" 3 "Malfunction" 4 "Learning in Progress" 5 "Learn Tire" 6 "Tire Learning Complete" 7 "High Pressure" 8 "High Temperature" ;
VAL_TABLE_ TrlrTireRRPresSts_Inv 0 "FALSE" 1 "TRUE" ;
VAL_TABLE_ VehLctrLghtsCstAvlFlg7 0 "FALSE" 1 "TRUE" ;
VAL_TABLE_ VehLctrLghtsCstAvlFlg6 0 "FALSE" 1 "TRUE" ;
VAL_TABLE_ VehLctrLghtsCstAvlFlg5 0 "FALSE" 1 "TRUE" ;
VAL_TABLE_ VehLctrLghtsCstAvlFlg4 0 "FALSE" 1 "TRUE" ;
VAL_TABLE_ VehLctrLghtsCstAvlFlg3 0 "FALSE" 1 "TRUE" ;
VAL_TABLE_ TrlrTireRtMdlPres_Inv 0 "FALSE" 1 "TRUE" ;
VAL_TABLE_ TrlrTireRtMdlTemp_Inv 0 "FALSE" 1 "TRUE" ;
VAL_TABLE_ TrlrTireRtMdlPresSts 0 "Unknown" 1 "Normal" 2 "Low Pressure" 3 "Malfunction" 4 "Learning in Progress" 5 "Learn Tire" 6 "Tire Learning Complete" 7 "High Pressure" 8 "High Temperature" ;
VAL_TABLE_ TrlrTireRtMdlPresSts_Inv 0 "FALSE" 1 "TRUE" ;
VAL_TABLE_ TrlrTireRFPres_Inv 0 "FALSE" 1 "TRUE" ;
VAL_TABLE_ TrlrTireRFTemp_Inv 0 "FALSE" 1 "TRUE" ;
VAL_TABLE_ TrlrTirePresSysFaild 0 "FALSE" 1 "TRUE" ;
VAL_TABLE_ TrlrTirePresFtrEnbld 0 "FALSE" 1 "TRUE" ;
VAL_TABLE_ TrlrTireRFPresSts 0 "Unknown" 1 "Normal" 2 "Low Pressure" 3 "Malfunction" 4 "Learning in Progress" 5 "Learn Tire" 6 "Tire Learning Complete" 7 "High Pressure" 8 "High Temperature" ;
VAL_TABLE_ TrlrTireRFPresSts_Inv 0 "FALSE" 1 "TRUE" ;
VAL_TABLE_ TrlrTireLRPres_Inv 0 "FALSE" 1 "TRUE" ;
VAL_TABLE_ TrlrTireLRTemp_Inv 0 "FALSE" 1 "TRUE" ;
VAL_TABLE_ TnDrvOvSpdWrnCstAvlFlg2 0 "FALSE" 1 "TRUE" ;
VAL_TABLE_ TnDrvOvSpdWrnCstAvlFlg1 0 "FALSE" 1 "TRUE" ;
VAL_TABLE_ TrlrTireLRPresSts 0 "Unknown" 1 "Normal" 2 "Low Pressure" 3 "Malfunction" 4 "Learning in Progress" 5 "Learn Tire" 6 "Tire Learning Complete" 7 "High Pressure" 8 "High Temperature" ;
VAL_TABLE_ TrlrTireLRPresSts_Inv 0 "FALSE" 1 "TRUE" ;
VAL_TABLE_ TnDrvOvSpdWrnCstAvlFlg7 0 "FALSE" 1 "TRUE" ;
VAL_TABLE_ TnDrvOvSpdWrnCstAvlFlg6 0 "FALSE" 1 "TRUE" ;
VAL_TABLE_ TnDrvOvSpdWrnCstAvlFlg5 0 "FALSE" 1 "TRUE" ;
VAL_TABLE_ TnDrvOvSpdWrnCstAvlFlg4 0 "FALSE" 1 "TRUE" ;
VAL_TABLE_ TnDrvOvSpdWrnCstAvlFlg3 0 "FALSE" 1 "TRUE" ;
VAL_TABLE_ TrlrTireLtMdlPres_Inv 0 "FALSE" 1 "TRUE" ;
VAL_TABLE_ TrlrTireLtMdlTemp_Inv 0 "FALSE" 1 "TRUE" ;
VAL_TABLE_ TnDrvSpdLmtCstAvlFlg2 0 "FALSE" 1 "TRUE" ;
VAL_TABLE_ TnDrvSpdLmtCstAvlFlg1 0 "FALSE" 1 "TRUE" ;
VAL_TABLE_ TrlrTireLtMdlPresSts 0 "Unknown" 1 "Normal" 2 "Low Pressure" 3 "Malfunction" 4 "Learning in Progress" 5 "Learn Tire" 6 "Tire Learning Complete" 7 "High Pressure" 8 "High Temperature" ;
VAL_TABLE_ TrlrTireLtMdlPresSts_Inv 0 "FALSE" 1 "TRUE" ;
VAL_TABLE_ TnDrvSpdLmtCstAvlFlg7 0 "FALSE" 1 "TRUE" ;
VAL_TABLE_ TnDrvSpdLmtCstAvlFlg6 0 "FALSE" 1 "TRUE" ;
VAL_TABLE_ TnDrvSpdLmtCstAvlFlg5 0 "FALSE" 1 "TRUE" ;
VAL_TABLE_ TnDrvSpdLmtCstAvlFlg4 0 "FALSE" 1 "TRUE" ;
VAL_TABLE_ TnDrvSpdLmtCstAvlFlg3 0 "FALSE" 1 "TRUE" ;
VAL_TABLE_ TrlrTireLFPres_Inv 0 "FALSE" 1 "TRUE" ;
VAL_TABLE_ TrlrTireLFTemp_Inv 0 "FALSE" 1 "TRUE" ;
VAL_TABLE_ TrlrTireLFPresSts 0 "Unknown" 1 "Normal" 2 "Low Pressure" 3 "Malfunction" 4 "Learning in Progress" 5 "Learn Tire" 6 "Tire Learning Complete" 7 "High Pressure" 8 "High Temperature" ;
VAL_TABLE_ TrlrTireLFPresSts_Inv 0 "FALSE" 1 "TRUE" ;
VAL_TABLE_ TrlrProfSeltnResp 0 "No Action" 1 "Default Profile" 2 "Profile1" 3 "Profile2" 4 "Profile3" 5 "Profile4" 6 "Profile5" 7 "Profile6" 8 "Profile7" 9 "Profile8" 10 "Profile9" 11 "Profile10" 12 "Profile11" 13 "Profile12" 14 "Profile13" 15 "Profile14" 16 "Profile15" 17 "Profile16" 18 "Profile17" 19 "Profile18" 20 "Profile19" 21 "Profile20" ;
VAL_TABLE_ TrlrTireLrnSts 0 "Unknown" 1 "Learn Completed" 2 "Learn Progressing" 3 "Learn Failed" 4 "Tires not Learned" ;
VAL_TABLE_ TireTmpLF_Inv 0 "FALSE" 1 "TRUE" ;
VAL_TABLE_ TireTmpLR_Inv 0 "FALSE" 1 "TRUE" ;
VAL_TABLE_ TireTmpRF_Inv 0 "FALSE" 1 "TRUE" ;
VAL_TABLE_ TireTmpRR_Inv 0 "FALSE" 1 "TRUE" ;
VAL_TABLE_ HVACFCRADSF_LtSet 0 "NoAction" 1 "Auto" 2 "Floor" 3 "FloorAndVent" 4 "Vent" 5 "VentAndWindshield" 6 "Windshield" 7 "FloorAndWindshield" 8 "FloorAndVentAndWindshield" ;
VAL_TABLE_ HVACFCRADSF_RtSet 0 "NoAction" 1 "Auto" 2 "Floor" 3 "FloorAndVent" 4 "Vent" 5 "VentAndWindshield" 6 "Windshield" 7 "FloorAndWindshield" 8 "FloorAndVentAndWindshield" ;
VAL_TABLE_ HVACFCRRFA_FrshAirSetChg 0 "FALSE" 1 "TRUE" ;
VAL_TABLE_ HVACFCRRFA_FrtAutoSetChg 0 "FALSE" 1 "TRUE" ;
VAL_TABLE_ HVACFCRRFA_RecircSetChg 0 "FALSE" 1 "TRUE" ;
VAL_TABLE_ HVACFCRTLCFR_ORL2 0 "FALSE" 1 "TRUE" ;
VAL_TABLE_ HVACFCRTLCFR_ORL1 0 "FALSE" 1 "TRUE" ;
VAL_TABLE_ HVACFCRTLCFR_ORH2 0 "FALSE" 1 "TRUE" ;
VAL_TABLE_ HVACFCRTLCFR_ORL3 0 "FALSE" 1 "TRUE" ;
VAL_TABLE_ HVACFCRTLCFR_ORH1 0 "FALSE" 1 "TRUE" ;
VAL_TABLE_ HVACFCRTLCFR_ORH3 0 "FALSE" 1 "TRUE" ;
VAL_TABLE_ HVACFCRTLCFR_CktCorr 0 "Indeterminate" 1 "Pass Criteria Met" 2 "Fail Criteria Met" ;
VAL_TABLE_ HVACFCRACH_CompSetChg 0 "FALSE" 1 "TRUE" ;
VAL_TABLE_ HVACFCRACH_HtrSetChg 0 "FALSE" 1 "TRUE" ;
VAL_TABLE_ HVACFCRACH_HtrSet 0 "NoAction" 1 "HEAT_OFF" 2 "HEAT_ON" ;
VAL_TABLE_ RHVSLF_HtdCushBckLvlChgDn 0 "FALSE" 1 "TRUE" ;
VAL_TABLE_ RHVSLF_HtdBckLvlChgDn 0 "FALSE" 1 "TRUE" ;
VAL_TABLE_ RHVSLF_VntLvlChgUp 0 "FALSE" 1 "TRUE" ;
VAL_TABLE_ RHVSLF_VntLvlChgDn 0 "FALSE" 1 "TRUE" ;
VAL_TABLE_ RHVSLF_HtdCushBckLvlChgUp 0 "FALSE" 1 "TRUE" ;
VAL_TABLE_ RHVSLF_HtdBckLvlChgUp 0 "FALSE" 1 "TRUE" ;
VAL_TABLE_ HVACFCRL_SetChg 0 "FALSE" 1 "TRUE" ;
VAL_TABLE_ HtdStBckCushStckSwLF 0 "FALSE" 1 "TRUE" ;
VAL_TABLE_ HVACFrtCtlReqSyncRrSetChg 0 "FALSE" 1 "TRUE" ;
VAL_TABLE_ RHVSRF_VntLvlChgUp 0 "FALSE" 1 "TRUE" ;
VAL_TABLE_ RHVSRF_HtdCushBckLvlChgUp 0 "FALSE" 1 "TRUE" ;
VAL_TABLE_ RHVSRF_HtdCushBckLvlChgDn 0 "FALSE" 1 "TRUE" ;
VAL_TABLE_ RHVSRF_VntLvlChgDn 0 "FALSE" 1 "TRUE" ;
VAL_TABLE_ RHVSRF_HtdBckLvlChgUp 0 "FALSE" 1 "TRUE" ;
VAL_TABLE_ RHVSRF_HtdBckLvlChgDn 0 "FALSE" 1 "TRUE" ;
VAL_TABLE_ VntStStckSwRF 0 "FALSE" 1 "TRUE" ;
VAL_TABLE_ VntStStckSwLF 0 "FALSE" 1 "TRUE" ;
VAL_TABLE_ HtdVntStSwActvRF 0 "FALSE" 1 "TRUE" ;
VAL_TABLE_ HtdVntStSwActvLF 0 "FALSE" 1 "TRUE" ;
VAL_TABLE_ HtdStBckStckSwRF 0 "FALSE" 1 "TRUE" ;
VAL_TABLE_ HtdStBckStckSwLF 0 "FALSE" 1 "TRUE" ;
VAL_TABLE_ HtdStBckCushStckSwRF 0 "FALSE" 1 "TRUE" ;
VAL_TABLE_ HVACFCRBLCF_ORL1 0 "FALSE" 1 "TRUE" ;
VAL_TABLE_ HVACFCRBLCF_ORH2 0 "FALSE" 1 "TRUE" ;
VAL_TABLE_ HVACFCRBLCF_ORH1 0 "FALSE" 1 "TRUE" ;
VAL_TABLE_ HVACFCRBLCF_ORL2 0 "FALSE" 1 "TRUE" ;
VAL_TABLE_ HVACFCRBLCF_CktCorr 0 "Indeterminate" 1 "Pass Criteria Met" 2 "Fail Criteria Met" ;
VAL_TABLE_ HVACFCRDP_FrtPwrSetChg_Inv 0 "FALSE" 1 "TRUE" ;
VAL_TABLE_ HVACFCRDP_FrtPwrSetChg 0 "FALSE" 1 "TRUE" ;
VAL_TABLE_ HVACFCRDP_IntrnlFltSts 0 "Fault1" 1 "Fault2" 2 "Fault3" 3 "Fault4" 4 "Fault5" 5 "Fault6" 6 "Fault7" 7 "Fault8" 8 "Fault9" 9 "Fault10" 10 "Fault11" 11 "Fault12" 12 "Fault13" 13 "Fault14" 14 "Fault15" 15 "Fault16" ;
VAL_TABLE_ HVACFCRDP_InitFin 0 "FALSE" 1 "TRUE" ;
VAL_TABLE_ HVACFCRDP_HtdFrtWshldSetChgd 0 "FALSE" 1 "TRUE" ;
VAL_TABLE_ HVACFCRDP_MaxDefrSetChg 0 "FALSE" 1 "TRUE" ;
VAL_TABLE_ HVACFCRADSCF_LtChgNext 0 "FALSE" 1 "TRUE" ;
VAL_TABLE_ HVACFCRADSCF_RtChgNext 0 "FALSE" 1 "TRUE" ;
VAL_TABLE_ HVACFCRBLR_LvlActv 0 "FALSE" 1 "TRUE" ;
VAL_TABLE_ HVACFCRTLCFL_ORL2 0 "FALSE" 1 "TRUE" ;
VAL_TABLE_ HVACFCRTLCFL_ORL1 0 "FALSE" 1 "TRUE" ;
VAL_TABLE_ HVACFCRTLCFL_ORH3 0 "FALSE" 1 "TRUE" ;
VAL_TABLE_ HVACFCRTLCFL_ORH2 0 "FALSE" 1 "TRUE" ;
VAL_TABLE_ HVACFCRTLCFL_ORH1 0 "FALSE" 1 "TRUE" ;
VAL_TABLE_ HVACFCRTLCFL_ORL3 0 "FALSE" 1 "TRUE" ;
VAL_TABLE_ HVACFCRTLCFL_CktCorr 0 "Indeterminate" 1 "Pass Criteria Met" 2 "Fail Criteria Met" ;
VAL_TABLE_ HVACFCRTLF_RtLvlActv 0 "FALSE" 1 "TRUE" ;
VAL_TABLE_ HVACFCRTLF_LtLvlActv 0 "FALSE" 1 "TRUE" ;
VAL_TABLE_ HVACFCRTLR_RtLvlActv 0 "FALSE" 1 "TRUE" ;
VAL_TABLE_ HVACFCRTLR_LtLvlActv 0 "FALSE" 1 "TRUE" ;
VAL_TABLE_ ADASIS_NAVILINK_FncRdClss 0 "LOCAL" 1 "SFREEWAY" 2 "FREEWAY" 3 "PED-MALL" 4 "HIGHWAY" 5 "ARTERIAL" 6 "ALLEY" 7 "COLLECTOR" ;
VAL_TABLE_ ADASIS_NAVILINK_DigMpVerYr 0 "2000" 1 "2001" 2 "2002" 3 "2003" 4 "2004" 5 "2005" 6 "2006" 7 "2007" 8 "2008" 9 "2009" 10 "2010" 11 "2011" 12 "2012" 13 "2013" 14 "2014" 15 "2015" 16 "2016" 17 "2017" 18 "2018" 19 "2019" 20 "2020" 21 "2021" 22 "2022" 23 "2023" 24 "2024" 25 "2025" 26 "2026" 27 "2027" 28 "2028" 29 "2029" 30 "2030" 31 "2031" 32 "2032" 33 "2033" 34 "2034" 35 "2035" 36 "2036" 37 "2037" 38 "2038" 39 "2039" 40 "2040" 41 "2041" 42 "2042" 43 "2043" 44 "2044" 45 "2045" 46 "2046" 47 "2047" 48 "2048" 49 "2049" 50 "2050" 51 "2051" 52 "2052" 53 "2053" 54 "2054" 55 "2055" 56 "2056" 57 "2057" 58 "2058" 59 "2059" 60 "2060" 61 "2061" 62 "2062" 63 "NOT APPLICABLE" ;
VAL_TABLE_ ADASIS_NAVILINK_SpdLmtUnt 0 "MILES/H" 1 "KM/H" ;
VAL_TABLE_ ADASIS_NAVILINK_SpdLmtPsdSpd_DuD 0 "FALSE" 1 "TRUE" ;
VAL_TABLE_ ADASIS_NAVILINK_MpDtAv 0 "NOT VALID" 1 "VALID" ;
VAL_TABLE_ ADASIS_NAVILINK_LnCtgry 0 "NO INFO AVAILABLE" 1 "ONE LANE" 2 "TWO OR THREE LANES" 3 "FOUR OR MORE LANES" ;
VAL_TABLE_ ADASIS_NAVILINK_DigMpVerQtr 0 "QUARTER 1" 1 "QUARTER 2" 2 "QUARTER 3" 3 "QUARTER 4" ;
VAL_TABLE_ ADASIS_NAVILINK_SprtdLnRd 0 "ROAD IS NOT CONTROLLED ACCESS ROAD" 1 "ROAD IS CONTROLLED ACCESS ROAD" ;
VAL_TABLE_ VehStbEnhCurrStReq 0 "No action" 1 "OFF" 2 "ON" ;
VAL_TABLE_ VehStbCompMdCurrStReq 0 "No action" 1 "OFF" 2 "ON" ;
VAL_TABLE_ TCStmpDsblReqConf 0 "No action" 1 "NO" 2 "YES" ;
VAL_TABLE_ TCSCurrStReq 0 "No action" 1 "OFF" 2 "ON" ;
VAL_TABLE_ CustMdActAeroCstChngSetReq 0 "NO_ACTION" 1 "CUSTOM_MODE_1" 2 "CUSTOM_MODE_2" 3 "CUSTOM_MODE_3" 4 "CUSTOM_MODE_4" 5 "CUSTOM_MODE_5" 6 "CUSTOM_MODE_6" 7 "CUSTOM_MODE_7" ;
VAL_TABLE_ CustmPT_CfgPgAct 0 "FALSE" 1 "TRUE" ;
VAL_TABLE_ ExtdHillStrtAsstCstChgSetReq 0 "NO_ACTION" 1 "EXTENDED_HOLD" 2 "STANDARD_HOLD" 3 "RESERVED_3" 4 "RESERVED_4" 5 "RESERVED_5" 6 "RESERVED_6" 7 "RESERVED_7" ;
VAL_TABLE_ DrvrSeltdConf 0 "NO_ACTION" 1 "SETTINGS_ACCEPTED" 2 "SETTINGS_CANCELED" 3 "MENU_ERROR_EVENT" ;
VAL_TABLE_ CustMdTrcStbCstChngSetReq 0 "NO_ACTION" 1 "CUSTOM_MODE_1" 2 "CUSTOM_MODE_2" 3 "CUSTOM_MODE_3" 4 "CUSTOM_MODE_4" 5 "CUSTOM_MODE_5" 6 "CUSTOM_MODE_6" 7 "CUSTOM_MODE_7" ;
VAL_TABLE_ CustMdPTCstChngSetReq 0 "NO ACTION" 1 "CUSTOM_MODE_1" 2 "CUSTOM_MODE_2" 3 "CUSTOM_MODE_3" 4 "CUSTOM_MODE_4" 5 "CUSTOM_MODE_5" 6 "CUSTOM_MODE_6" 7 "CUSTOM_MODE_7" ;
VAL_TABLE_ CustMdBrkPdlCstChngSetReq 0 "NO_ACTION" 1 "CUSTOM_MODE_1" 2 "CUSTOM_MODE_2" 3 "CUSTOM_MODE_3" 4 "CUSTOM_MODE_4" 5 "CUSTOM_MODE_5" 6 "CUSTOM_MODE_6" 7 "CUSTOM_MODE_7" ;
VAL_TABLE_ BatVltOBD_Inv 0 "FALSE" 1 "TRUE" ;
VAL_TABLE_ PTExPrtclFltrMnlRgnRq 0 "FALSE" 1 "TRUE" ;
VAL_TABLE_ CustmStbCtlRdctReqConf 0 "No Action" 1 "No" 2 "Yes" ;
VAL_TABLE_ OTARC_RejCrdntnECP_MC 0 "FALSE" 1 "TRUE" ;
VAL_TABLE_ OTARC_RejCrdntnBSM_MH 0 "FALSE" 1 "TRUE" ;
VAL_TABLE_ OTARC_RejCrdntnECP_X2 0 "FALSE" 1 "TRUE" ;
VAL_TABLE_ OTARC_RejCrdntnECP_X1 0 "FALSE" 1 "TRUE" ;
VAL_TABLE_ OTARC_RejCrdntnECM 0 "FALSE" 1 "TRUE" ;
VAL_TABLE_ OTARC_RejCrdntnEBCM 0 "FALSE" 1 "TRUE" ;
VAL_TABLE_ OTARC_RejCrdntnBSM 0 "FALSE" 1 "TRUE" ;
VAL_TABLE_ OTARC_RejCrdntnBCM 0 "FALSE" 1 "TRUE" ;
VAL_TABLE_ OTARC_RejCrdntnECU_19 0 "FALSE" 1 "TRUE" ;
VAL_TABLE_ OTARC_RejCrdntnECU_18 0 "FALSE" 1 "TRUE" ;
VAL_TABLE_ OTARC_RejCrdntnECU_17 0 "FALSE" 1 "TRUE" ;
VAL_TABLE_ OTARC_RejCrdntnECU_16 0 "FALSE" 1 "TRUE" ;
VAL_TABLE_ OTARC_RejCrdntnECU_15 0 "FALSE" 1 "TRUE" ;
VAL_TABLE_ OTARC_RejCrdntnECU_14 0 "FALSE" 1 "TRUE" ;
VAL_TABLE_ OTARC_RejCrdntnECU_13 0 "FALSE" 1 "TRUE" ;
VAL_TABLE_ OTARC_RejCrdntnECP_S 0 "FALSE" 1 "TRUE" ;
VAL_TABLE_ OTARC_RejCrdntnECU_27 0 "FALSE" 1 "TRUE" ;
VAL_TABLE_ OTARC_RejCrdntnECU_26 0 "FALSE" 1 "TRUE" ;
VAL_TABLE_ OTARC_RejCrdntnECU_25 0 "FALSE" 1 "TRUE" ;
VAL_TABLE_ OTARC_RejCrdntnECU_24 0 "FALSE" 1 "TRUE" ;
VAL_TABLE_ OTARC_RejCrdntnECU_23 0 "FALSE" 1 "TRUE" ;
VAL_TABLE_ OTARC_RejCrdntnECU_22 0 "FALSE" 1 "TRUE" ;
VAL_TABLE_ OTARC_RejCrdntnECU_21 0 "FALSE" 1 "TRUE" ;
VAL_TABLE_ OTARC_RejCrdntnECU_20 0 "FALSE" 1 "TRUE" ;
VAL_TABLE_ OTARC_RejCrdntnTCM 0 "FALSE" 1 "TRUE" ;
VAL_TABLE_ OTARC_RejCrdntnICCM 0 "FALSE" 1 "TRUE" ;
VAL_TABLE_ OTARC_RejCrdntnFICM 0 "FALSE" 1 "TRUE" ;
VAL_TABLE_ OTARC_RejCrdntnECU_32 0 "FALSE" 1 "TRUE" ;
VAL_TABLE_ OTARC_RejCrdntnECU_31 0 "FALSE" 1 "TRUE" ;
VAL_TABLE_ OTARC_RejCrdntnECU_30 0 "FALSE" 1 "TRUE" ;
VAL_TABLE_ OTARC_RejCrdntnECU_29 0 "FALSE" 1 "TRUE" ;
VAL_TABLE_ OTARC_RejCrdntnECU_28 0 "FALSE" 1 "TRUE" ;
VAL_TABLE_ HMIGI1P_TrlrBrkDispActvAuth 0 "FALSE" 1 "TRUE" ;
VAL_TABLE_ HMIGI1P_TrlrBrkDispActvAuth_DuD 0 "FALSE" 1 "TRUE" ;
VAL_TABLE_ HMIGI1P_EnvModPrsntRspdr4Auth 0 "FALSE" 1 "TRUE" ;
VAL_TABLE_ HMIGI2P_LnFllwgInterFltDtdAuth 0 "FALSE" 1 "TRUE" ;
VAL_TABLE_ HMIGI2P_IPCFlrIndOnAuth 0 "FALSE" 1 "TRUE" ;
VAL_TABLE_ HMII1P_ACCSetTypAuth 0 "Manual" 1 "Auto" ;
VAL_TABLE_ HMII1P_AutoModeSpdLimCnfrmdAuth 0 "FALSE" 1 "TRUE" ;
VAL_TABLE_ HMII1P_ChmSysSOHAuth 0 "Unknown" 1 "Healthy" 2 "Faulted" ;
VAL_TABLE_ HMII1P_LnFllwgChInterFltDtdAuth 0 "FALSE" 1 "TRUE" ;
VAL_TABLE_ HMII1P_MCRLDOprtlStsAuth 0 "Working as Intended" 1 "Not Working as Intended" 2 "Unknown" ;
VAL_TABLE_ HMII1P_IPCDispStsAuth 0 "Unknown" 1 "Normal" 2 "Fault" ;
VAL_TABLE_ HMIR1P_MCRLDAnmProfReqAuth 0 "Animation Profile Off" 1 "Animation Profile bulb check" 2 "Animation Profile 1" 3 "Animation Profile 2" 4 "Animation Profile 3" 5 "Animation Profile 4" 6 "Animation Profile 5" 7 "Animation Profile 6" 8 "Animation Profile 7" 9 "Animation Profile 8" 10 "Animation Profile 9" 11 "Animation Profile 10" 12 "Animation Profile 11" 13 "Animation Profile 12" 14 "Animation Profile 13" 15 "Animation Profile 14" 16 "Animation Profile 15" 17 "Animation Profile 16" 18 "Animation Profile 17" 19 "Animation Profile 18" 20 "Animation Profile 19" 21 "Animation Profile 20" 22 "Animation Profile 21" 23 "Animation Profile 22" 24 "Animation Profile 23" 25 "Animation Profile 24" 26 "Animation Profile 25" 27 "Animation Profile 26" 28 "Animation Profile 27" 29 "Animation Profile 28" 30 "Animation Profile 29" 31 "Animation Profile 30" ;
VAL_TABLE_ HMIR1P_LnFllwgRHSChEvntStatAuth 0 "No Action" 1 "Active" 2 "Cancel Chime" ;
VAL_TABLE_ HMIR1P_MCRLDAnmProfReqAuth_Inv 0 "FALSE" 1 "TRUE" ;
VAL_TABLE_ HMIR1P_MCRLDAnmProfReqAuth_DuD 0 "FALSE" 1 "TRUE" ;
VAL_TABLE_ HMIR1P_LnFllwgLHSChEvntStatAuth 0 "No Action" 1 "Active" 2 "Cancel Chime" ;
VAL_TABLE_ HMIR1P_LnFllwgGenChEvntStatAuth 0 "No Action" 1 "Active" 2 "Cancel Chime" ;
VAL_TABLE_ HVACFCRBLF_LvlActv 0 "FALSE" 1 "TRUE" ;
VAL_TABLE_ HVACFCRTLCFLI2_ORL4 0 "FALSE" 1 "TRUE" ;
VAL_TABLE_ HVACFCRTLCFLI2_ORH4 0 "FALSE" 1 "TRUE" ;
VAL_TABLE_ HVACFCRTLCFRI2_ORL4 0 "FALSE" 1 "TRUE" ;
VAL_TABLE_ HVACFCRTLCFRI2_ORH4 0 "FALSE" 1 "TRUE" ;
VAL_TABLE_ HVACICR1_IntrnlFltSts 0 "Fault1" 1 "Fault2" 2 "Fault3" 3 "Fault4" 4 "Fault5" 5 "Fault6" 6 "Fault7" 7 "Fault8" 8 "Fault9" 9 "Fault10" 10 "Fault11" 11 "Fault12" 12 "Fault13" 13 "Fault14" 14 "Fault15" 15 "Fault16" ;
VAL_TABLE_ HVACICR1_FrtAutoSetChg 0 "FALSE" 1 "TRUE" ;
VAL_TABLE_ HVACICR1_FrtPwrSetChg 0 "FALSE" 1 "TRUE" ;
VAL_TABLE_ HVACICR1_HtrSet 0 "NoAction" 1 "HEAT_OFF" 2 "HEAT_ON" ;
VAL_TABLE_ HVACICR1_CompSetChg 0 "FALSE" 1 "TRUE" ;
VAL_TABLE_ HVACICR1_CompSet 0 "NoAction" 1 "COMP_OFF" 2 "COMP_ON" 3 "COMP_ECON" ;
VAL_TABLE_ HVACICR1_MaxDefrSetChg 0 "FALSE" 1 "TRUE" ;
VAL_TABLE_ HVACICR1_MaxDefrSet 0 "NoAction" 1 "MaxDefrostOff" 2 "MaxDefrostOn" ;
VAL_TABLE_ HVACICR1_HtrSetChg 0 "FALSE" 1 "TRUE" ;
VAL_TABLE_ HVACICR1_FrtRrPwrSet 0 "NoAction" 1 "FrontOFF_RearOFF" 2 "FrontON_RearON" 3 "FrontON_RearOFF" 4 "FrontOFF_RearON" ;
VAL_TABLE_ HVACICR1_BlwLvlFrtActv 0 "FALSE" 1 "TRUE" ;
VAL_TABLE_ HVACICR2_AirDstRtSet 0 "NoAction" 1 "Auto" 2 "Floor" 3 "FloorAndVent" 4 "Vent" 5 "VentAndWindshield" 6 "Windshield" 7 "FloorAndWindshield" 8 "FloorAndVentAndWindshield" ;
VAL_TABLE_ HVACICR2_AirDstLtSet 0 "NoAction" 1 "Auto" 2 "Floor" 3 "FloorAndVent" 4 "Vent" 5 "VentAndWindshield" 6 "Windshield" 7 "FloorAndWindshield" 8 "FloorAndVentAndWindshield" ;
VAL_TABLE_ HVACICR2_RecircSet 0 "NoAction" 1 "FreshAir" 2 "Recirc" ;
VAL_TABLE_ HVACICR2_AirDstLtChgPrev 0 "FALSE" 1 "TRUE" ;
VAL_TABLE_ HVACICR2_AirDstLtChgNext 0 "FALSE" 1 "TRUE" ;
VAL_TABLE_ HVACICR2_TempLtLvlActv 0 "FALSE" 1 "TRUE" ;
VAL_TABLE_ HVACICR2_AirDstRtChgNext 0 "FALSE" 1 "TRUE" ;
VAL_TABLE_ HVACICR2_TempRtLvlActv 0 "FALSE" 1 "TRUE" ;
VAL_TABLE_ HVACICR2_RecircSetChg 0 "FALSE" 1 "TRUE" ;
VAL_TABLE_ HVACICR2_AirDstRtChgPrev 0 "FALSE" 1 "TRUE" ;
VAL_TABLE_ ReqRrClmtApp 0 "FALSE" 1 "TRUE" ;
VAL_TABLE_ ReqFrtClmtApp 0 "FALSE" 1 "TRUE" ;
VAL_TABLE_ HVACFCRADR_LtChgNext 0 "FALSE" 1 "TRUE" ;
VAL_TABLE_ HVACFCRADR_RtSet 0 "NoAction" 1 "Auto" 2 "Floor" 3 "FloorAndVent" 4 "Vent" 5 "VentAndRoof" 6 "Roof" 7 "RoofAndFloor" 8 "FloorAndVentAndRoof" ;
VAL_TABLE_ HVACFCRADR_RtChgNext 0 "FALSE" 1 "TRUE" ;
VAL_TABLE_ HVACFCRRA_SetChg 0 "FALSE" 1 "TRUE" ;
VAL_TABLE_ HVACFCRADR_LtSet 0 "NoAction" 1 "Auto" 2 "Floor" 3 "FloorAndVent" 4 "Vent" 5 "VentAndRoof" 6 "Roof" 7 "RoofAndFloor" 8 "FloorAndVentAndRoof" ;
VAL_TABLE_ HVACFCRRD_SetChg 0 "FALSE" 1 "TRUE" ;
VAL_TABLE_ HVACFCRRP_SetChg 0 "FALSE" 1 "TRUE" ;
VAL_TABLE_ HVACFCRSA_SetChg 0 "FALSE" 1 "TRUE" ;
VAL_TABLE_ HtdStrgWhlSwActv_HVAC_FP_F 0 "FALSE" 1 "TRUE" ;
VAL_TABLE_ ManHtdStrgWhlReqd_HVAC_FP_F 0 "FALSE" 1 "TRUE" ;
VAL_TABLE_ ManHtdStrgWhlReqd_HVAC_FP_F_Inv 0 "FALSE" 1 "TRUE" ;
VAL_TABLE_ HtdStrgWhlStkSw_HVAC_FP_F 0 "FALSE" 1 "TRUE" ;
VAL_TABLE_ HtdStrgWhlStkSw_HVAC_FP_F_Inv 0 "FALSE" 1 "TRUE" ;
VAL_TABLE_ RHVSRR_HtdBckLvlChgUp 0 "FALSE" 1 "TRUE" ;
VAL_TABLE_ RHVSRR_HtdBckLvlChgDn 0 "FALSE" 1 "TRUE" ;
VAL_TABLE_ RHVSLR_VntLvlChgUp 0 "FALSE" 1 "TRUE" ;
VAL_TABLE_ RHVSLR_VntLvlChgDn 0 "FALSE" 1 "TRUE" ;
VAL_TABLE_ RHVSLR_HtdCushBckLvlChgUp 0 "FALSE" 1 "TRUE" ;
VAL_TABLE_ RHVSLR_HtdCushBckLvlChgDn 0 "FALSE" 1 "TRUE" ;
VAL_TABLE_ RHVSLR_HtdBckLvlChgUp 0 "FALSE" 1 "TRUE" ;
VAL_TABLE_ RHVSLR_HtdBckLvlChgDn 0 "FALSE" 1 "TRUE" ;
VAL_TABLE_ HtdStBckStckSwRR 0 "FALSE" 1 "TRUE" ;
VAL_TABLE_ HtdStBckStckSwLR 0 "FALSE" 1 "TRUE" ;
VAL_TABLE_ HtdStBckCushStckSwRR 0 "FALSE" 1 "TRUE" ;
VAL_TABLE_ HtdStBckCushStckSwLR 0 "FALSE" 1 "TRUE" ;
VAL_TABLE_ RHVSRR_VntLvlChgUp 0 "FALSE" 1 "TRUE" ;
VAL_TABLE_ RHVSRR_VntLvlChgDn 0 "FALSE" 1 "TRUE" ;
VAL_TABLE_ RHVSRR_HtdCushBckLvlChgUp 0 "FALSE" 1 "TRUE" ;
VAL_TABLE_ RHVSRR_HtdCushBckLvlChgDn 0 "FALSE" 1 "TRUE" ;
VAL_TABLE_ VntStStckSwRR 0 "FALSE" 1 "TRUE" ;
VAL_TABLE_ VntStStckSwLR 0 "FALSE" 1 "TRUE" ;
VAL_TABLE_ HtdVntStSwActvRR 0 "FALSE" 1 "TRUE" ;
VAL_TABLE_ HtdVntStSwActvLR 0 "FALSE" 1 "TRUE" ;
VAL_TABLE_ FCSS1_FrtCntrStckSldr1Prxmty 0 "NOPROXIMITY_NOTOUCH" 1 "PROXIMITY_DETECTED" 2 "TOUCH_DETECTED" 3 "RESERVED" ;
VAL_TABLE_ FCSS2_FrtCntrStckSldr2Prxmty 0 "NOPROXIMITY_NOTOUCH" 1 "PROXIMITY_DETECTED" 2 "TOUCH_DETECTED" 3 "RESERVED" ;
VAL_TABLE_ FCSS3_FrtCntrStckSldr3Prxmty 0 "NOPROXIMITY_NOTOUCH" 1 "PROXIMITY_DETECTED" 2 "TOUCH_DETECTED" 3 "RESERVED" ;
VAL_TABLE_ FCSTP34_FrtCntrStckTchFlg3 0 "FALSE" 1 "TRUE" ;
VAL_TABLE_ FCSTP34_FrtCntrStckTchFlg4 0 "FALSE" 1 "TRUE" ;
VAL_TABLE_ FCSTP12_FrtCntrStckTchFlg2 0 "FALSE" 1 "TRUE" ;
VAL_TABLE_ FCSTP12_FrtCntrStckTchFlg1 0 "FALSE" 1 "TRUE" ;
VAL_TABLE_ StrgeOpn 0 "FALSE" 1 "TRUE" ;
VAL_TABLE_ FrtCntrStckPriVidInLckd 0 "Not_Locked" 1 "Locked" ;
VAL_TABLE_ FrtCntrStckLVMVidInLckd 0 "Not_Locked" 1 "Locked" ;
VAL_TABLE_ PwrtrnExhPrtclFiltManRegnReq 0 "FALSE" 1 "TRUE" ;
VAL_TABLE_ VehFlRngCalc_Inv 0 "FALSE" 1 "TRUE" ;
VAL_TABLE_ FuelLvlLoIndOn 0 "FALSE" 1 "TRUE" ;
VAL_TABLE_ PTExPrtclFltrMnlRgnDispPrsnt 0 "FALSE" 1 "TRUE" ;
VAL_TABLE_ FllwgDstIndTmDstSel 0 "TIME" 1 "DISTANCE" ;
VAL_TABLE_ ChmMngrSoH 0 "UNKNOWN" 1 "INITIALIZED" 2 "RESERVED_2" 3 "RESERVED_3" 4 "RESERVED_4" 5 "RESERVED_5" 6 "RESERVED_6" 7 "RESERVED_7" ;
VAL_TABLE_ StrWhlCtlVolUpSw 0 "Released" 1 "Pressed" ;
VAL_TABLE_ StrWhlCtlVolDnSw 0 "Released" 1 "Pressed" ;
VAL_TABLE_ StrWhlCtlPshToTlkSw 0 "Released" 1 "Pressed" ;
VAL_TABLE_ StrWhlCtlFvrtUpSw 0 "Released" 1 "Pressed" ;
VAL_TABLE_ StrWhlCtlFvrtDnSw 0 "Released" 1 "Pressed" ;
VAL_TABLE_ StrWhlCtlEndSw 0 "Released" 1 "Pressed" ;
VAL_TABLE_ VehFlRngLwIO 0 "FALSE" 1 "TRUE" ;
VAL_TABLE_ TrnsOilLfRstRq 0 "No Request" 1 "Reset Request Active" ;
VAL_TABLE_ TPSnsrProgEvReq 0 "FALSE" 1 "TRUE" ;
VAL_TABLE_ FobProgEvntRqd 0 "FALSE" 1 "TRUE" ;
VAL_TABLE_ EngOilLifeRstReq 0 "FALSE" 1 "TRUE" ;
VAL_TABLE_ LnchCtlWhlSlReq 0 "No Action" 1 "Five Percent" 2 "Five And A Half Percent" 3 "Six Percent" 4 "Six And A Half Percent" 5 "Seven Percent" 6 "Seven And A Half Percent" 7 "Eight Percent" 8 "Eight And A Half Percent" 9 "Nine Percent" 10 "Nine And A Half Percent" 11 "Ten Percent" 12 "Ten And A Half Percent" 13 "Eleven Percent" 14 "Eleven And a Half Percent" 15 "Twelve Percent" 16 "Twelve And A Half Percent" 17 "Thirteen Percent" 18 "Thirteen And A Half Percent" 19 "Fourteen Percent" 20 "Fourteen And A Half Percent" 21 "Fifteen Percent" ;
VAL_TABLE_ LnchCtlEngRPMReq 0 "No Action" 1 "800" 2 "900" 3 "1000" 4 "1100" 5 "1200" 6 "1300" 7 "1400" 8 "1500" 9 "1600" 10 "1700" 11 "1800" 12 "1900" 13 "2000" 14 "2100" 15 "2200" 16 "2300" 17 "2400" 18 "2500" 19 "2600" 20 "2700" 21 "2800" 22 "2900" 23 "3000" 24 "3100" 25 "3200" 26 "3300" 27 "3400" 28 "3500" 29 "3600" 30 "3700" 31 "3800" 32 "3900" 33 "4000" 34 "FlexibleRPM 1" 35 "FlexibleRPM 2" 36 "FlexibleRPM 3" 37 "FlexibleRPM 4" 38 "FlexibleRPM 5" ;
VAL_TABLE_ AutoTransGrDispdVal 0 "None" 1 "P" 2 "R" 3 "N" 4 "D" 5 "D1" 6 "D2" 7 "D3" 8 "D4" 9 "D5" 10 "D6" 11 "D7" 12 "D8" 13 "D9" 14 "D10" 15 "First(1)" 16 "Second(2)" 17 "Third(3)" 18 "Fourth(4)" 19 "Fifth(5)" 20 "Sixth(6)" 21 "Seventh(7)" 22 "Eighth(8)" 23 "Ninth(9)" 24 "M" 25 "M1" 26 "M2" 27 "M3" 28 "M4" 29 "M5" 30 "M6" 31 "M7" 32 "M8" 33 "M9" 34 "M10" 35 "L" 36 "L1" 37 "L2" 38 "L3" 39 "L4" 40 "L5" 41 "L6" 42 "L7" 43 "L8" 44 "L9" 45 "L10" 46 "I" 47 "Park In Progress" 48 "Reverse In Progress" 49 "Neutral In Progress" 50 "Drive In Progress" 51 "Dbar1" 52 "Dbar2" 53 "Dbar3" 54 "Dbar4" 55 "Dbar5" 56 "Dbar6" 57 "Dbar7" 58 "Dbar8" 59 "Dbar9" 60 "Dbar10" 61 "Manual In Progress" ;
VAL_TABLE_ AutoTransGrDispdVal_Inv 0 "FALSE" 1 "TRUE" ;
VAL_TABLE_ LnchCtlRelLineLckReqd 0 "FALSE" 1 "TRUE" ;
VAL_TABLE_ LnchCtlModeReq 0 "No Action" 1 "Automatic" 2 "Custom" 3 "Line Lock" ;
VAL_TABLE_ Trip1Odo_Inv 0 "FALSE" 1 "TRUE" ;
VAL_TABLE_ Trip2Odo_Inv 0 "FALSE" 1 "TRUE" ;
VAL_TABLE_ RdHgtAtLocStorConf 0 "No Action" 1 "Store" 2 "Clear" 3 "All Clear" 4 "Undo Delete" ;
VAL_TABLE_ BrkPadLifeSysDrvrReq 0 "No Action" 1 "Disable" 2 "Enable" 3 "Reset Front" 4 "Reset Rear" ;
VAL_TABLE_ TransOilFiltLifeRstReq 0 "No Request" 1 "Reset Request Active" ;
VAL_TABLE_ TPMTrLdnRstReq 0 "UNKNOWN" 1 "LIGHT LOAD" 2 "BEST ECONOMY LOAD" 3 "MAX LOAD" ;
VAL_TABLE_ EngAirFiltMonDrvrReq 0 "No Action" 1 "Enable" 2 "Disable" 3 "Reset" ;
VAL_TABLE_ IPC_RunCrnkInpActv_Inv 0 "FALSE" 1 "TRUE" ;
VAL_TABLE_ HUD_RclCmpt 0 "No Recall Requested" 1 "Recall In Process" 2 "Recall Complete" ;
VAL_TABLE_ DispMeasSysExtnd 0 "US" 1 "IMPERIAL" 2 "Metric KM/L" 3 "Metric L/100KM" ;
VAL_TABLE_ ClstrAnmStat 0 "Uninitialized" 1 "Ready" 2 "WelcomePlay" 3 "StartPlay" 4 "ShutdownPlay" ;
VAL_TABLE_ DispMeasSys 0 "Metric" 1 "English" ;
VAL_TABLE_ ClstrHMI_Rdy 0 "FALSE" 1 "TRUE" ;
VAL_TABLE_ APARghtSftBtnStatIPC 0 "NOT_PRESSED" 1 "PRESSED" ;
VAL_TABLE_ APALftSftBtnStatIPC 0 "NOT_PRESSED" 1 "PRESSED" ;
VAL_TABLE_ APAFcStatIPC 0 "NO_FOCUS" 1 "FOCUS" ;
VAL_TABLE_ IPC_RunCrnkInpActv 0 "FALSE" 1 "TRUE" ;
VAL_TABLE_ PAMutDrvrReq 0 "No Action" 1 "Mute Requested" 2 "Unmute Requested" ;
VAL_TABLE_ HUD_CustSelActvStat_Inv 0 "FALSE" 1 "TRUE" ;
VAL_TABLE_ TSMWrngPopUpSts 0 "TSM Warning Off" 1 "TSM Warning On" ;
VAL_TABLE_ TSMSgnNtfnWrnDispd 0 "FALSE" 1 "TRUE" ;
VAL_TABLE_ TSMPageDispActv 0 "FALSE" 1 "TRUE" ;
VAL_TABLE_ TSMCustRstReq 0 "FALSE" 1 "TRUE" ;
VAL_TABLE_ StkHUD_CustSelStat 0 "FALSE" 1 "TRUE" ;
VAL_TABLE_ HUD_CustSelActvStat 0 "FALSE" 1 "TRUE" ;
VAL_TABLE_ StrgWhlCtlInCarVcCommCtlSw 0 "Released" 1 "Pressed" ;
VAL_TABLE_ NtVsnVidCntrstUserReq 0 "No Action" 1 "Increase" 2 "Decrease" 3 "Set to default" ;
VAL_TABLE_ NtVsnVidBrghtnsUserReq 0 "No Action" 1 "Increase" 2 "Decrease" 3 "Set to default" ;
VAL_TABLE_ FuelFiltLifeRstReqd 0 "FALSE" 1 "TRUE" ;
VAL_TABLE_ JmpStrtReqd 0 "FALSE" 1 "TRUE" ;
VAL_TABLE_ BklghtngCnfg 0 "Off" 1 "On" 2 "Local" ;
VAL_TABLE_ HVACICRADSR_LtSet 0 "NoAction" 1 "Auto" 2 "Floor" 3 "FloorAndVent" 4 "Vent" 5 "VentAndRoof" 6 "Roof" 7 "RoofAndFloor" 8 "FloorAndVentAndRoof" ;
VAL_TABLE_ HVACICRADSR_RtSet 0 "NoAction" 1 "Auto" 2 "Floor" 3 "FloorAndVent" 4 "Vent" 5 "VentAndRoof" 6 "Roof" 7 "RoofAndFloor" 8 "FloorAndVentAndRoof" ;
VAL_TABLE_ HVACICRBLR_LvlActv 0 "FALSE" 1 "TRUE" ;
VAL_TABLE_ HVACInfoCtlReqRrLckSetChg 0 "FALSE" 1 "TRUE" ;
VAL_TABLE_ HVACInfoCtlReqRrDfgSetChg 0 "FALSE" 1 "TRUE" ;
VAL_TABLE_ HVACInfoCtlReqRrAutoSetChg 0 "FALSE" 1 "TRUE" ;
VAL_TABLE_ HVACInfoCtlReqRrDfgSet 0 "NoAction" 1 "RearDefogOFF" 2 "RearDefogON" ;
VAL_TABLE_ HVACInfoCtlReqSyncSet 0 "NoAction" 1 "SYNC_all" 2 "UnSYNC_all" 3 "SYNC_Rear_to_Driver" 4 "UnSYNC_Rear_to_Driver" ;
VAL_TABLE_ HVACInfoCtlReqSyncRrSetChg 0 "FALSE" 1 "TRUE" ;
VAL_TABLE_ HVACInfoCtlReqSyncAllSetChg 0 "FALSE" 1 "TRUE" ;
VAL_TABLE_ HVACInfoCtlReqRrPwrSetChg 0 "FALSE" 1 "TRUE" ;
VAL_TABLE_ HVACICRTLR_LtLvlActv 0 "FALSE" 1 "TRUE" ;
VAL_TABLE_ HVACICRTLR_RtLvlActv 0 "FALSE" 1 "TRUE" ;
VAL_TABLE_ HVACInfoCtlReqBlwSpdRdct 0 "FALSE" 1 "TRUE" ;
VAL_TABLE_ CSI_ChmPrdcrSOH 0 "Unknown" 1 "Healthy" 2 "Faulted" ;
VAL_TABLE_ HVACICRADSCR_LtChgNext 0 "FALSE" 1 "TRUE" ;
VAL_TABLE_ HVACICRADSCR_RtChgNext 0 "FALSE" 1 "TRUE" ;
VAL_TABLE_ TeenDrvReq 0 "No Action" 1 "Verify Teen PIN" 2 "Update Teen PIN" 3 "Set Teen Key" 4 "Clear Teen Key" 5 "Check for Teen Key" 6 "Clear Teen Keys and PIN" 7 "Reset Report Card" 8 "Request Report Card Data" ;
VAL_TABLE_ Ftr6AlrmReq 0 "No Action" 1 "Set Request" 2 "Cancel Request" ;
VAL_TABLE_ LnChgAlrtCstChngSetReq 0 "NO_ACTION" 1 "OFF" 2 "ON" 3 "RESERVED_3" 4 "RESERVED_4" 5 "RESERVED_5" 6 "RESERVED_6" 7 "RESERVED_7" ;
VAL_TABLE_ TCP_LCMFileTrans 0 "No Action" 1 "Begin Transfer" 2 "Successful Block Transfer" 3 "Cancel Transfer" 4 "Retry Last Block" ;
VAL_TABLE_ TCP_LCMDataMsgStat 0 "No Action" 1 "Acknowledge" ;
VAL_TABLE_ IPC_LCMDataMsgStat 0 "No Action" 1 "Acknowledge" ;
VAL_TABLE_ CamVidICS_DispAct 0 "FALSE" 1 "TRUE" ;
VAL_TABLE_ ValetMdReq 0 "NoAction" 1 "SetPIN" 2 "ClearPIN" ;
VAL_TABLE_ LngSelExt 0 "NA English" 1 "German" 2 "Italian" 3 "Swedish" 4 "French" 5 "Spanish" 6 "Dutch" 7 "Portuguese" 8 "Norwegian" 9 "Finnish" 10 "Danish" 11 "Greek" 12 "Japanese" 13 "Arabic" 14 "Standard Chinese" 15 "Polish" 16 "Turkish" 17 "Korean" 18 "Traditional Chinese" 19 "UK English" 20 "Hungarian" 21 "Czech" 22 "Slovak" 23 "Russian" 24 "Brazilian Portuguese" 25 "Thai" 26 "Bulgarian" 27 "Romanian" 28 "Slovenian" 29 "Croatian" 30 "Ukrainian" 31 "NA French" 32 "NA Spanish" 33 "Cantonese" 34 "Uzbek" 35 "Serbian" 36 "Lithuanian" 37 "Estonian" 38 "Latvian" 39 "Macedonian" 40 "AU English" 41 "ZA English" ;
VAL_TABLE_ IPC_LCMFileTrans 0 "No Action" 1 "Begin Transfer" 2 "Successful Block Transfer" 3 "Cancel Transfer" 4 "Retry Last Block" ;
VAL_TABLE_ VehLctrLtsCstChgSetReq 0 "NO_ACTION" 1 "OFF" 2 "ON" 3 "RESERVED_3" 4 "RESERVED_4" 5 "RESERVED_5" 6 "RESERVED_6" 7 "RESERVED_7" ;
VAL_TABLE_ TrlrMirVidGdlnsCstChgSetReq 0 "No_Action" 1 "Off" 2 "On" ;
VAL_TABLE_ TrlrMirVidEnblCstChgSetReq 0 "No_Action" 1 "Off" 2 "On" ;
VAL_TABLE_ APARghtSftBtnStat 0 "NOT_PRESSED" 1 "PRESSED" ;
VAL_TABLE_ APAPrllPrkSftBtnStat 0 "NOT_PRESSED" 1 "PRESSED" ;
VAL_TABLE_ ElvtdIdlCstChgSetReq 0 "No Action" 1 "Off" 2 "On" ;
VAL_TABLE_ WlkAwyLckCstChgSetReq 0 "NO_ACTION" 1 "OFF" 2 "ON" 3 "ON_WITH_CHIRP" 4 "RESERVED_4" 5 "RESERVED_5" 6 "RESERVED_6" 7 "RESERVED_7" ;
VAL_TABLE_ StBltShfIntlkCstChgSetReq 0 "NO ACTION" 1 "OFF" 2 "ON" 3 "RESERVED 3" 4 "RESERVED 4" 5 "RESERVED 5" 6 "RESERVED 6" 7 "RESERVED 7" ;
VAL_TABLE_ TimeDispFormat 0 "12 Hour Mode" 1 "24 Hour Mode" ;
VAL_TABLE_ RstrCstDfltReq 0 "FALSE" 1 "TRUE" ;
VAL_TABLE_ RFStStsDispActv 0 "FALSE" 1 "TRUE" ;
VAL_TABLE_ LFStStsDispActv 0 "FALSE" 1 "TRUE" ;
VAL_TABLE_ APASrchSftBtnStat 0 "NOT_PRESSED" 1 "PRESSED" ;
VAL_TABLE_ TnDrvStBltShfIntlkCstChgSetReq 0 "NO_ACTION" 1 "OFF" 2 "ON" 3 "RESERVED_3" 4 "RESERVED_4" 5 "RESERVED_5" 6 "RESERVED_6" 7 "RESERVED_7" ;
VAL_TABLE_ RlkRtUlkDrCstChSetReq 0 "NO_ACTION" 1 "OFF" 2 "ON" 3 "RESERVED_3" 4 "RESERVED_4" 5 "RESERVED_5" 6 "RESERVED_6" 7 "RESERVED_7" ;
VAL_TABLE_ RevTltMrCstChgSetReq 0 "NO_ACTION" 1 "OFF" 2 "DRIVER" 3 "PASSENGER" 4 "DRIVER_AND_PASSENGER" 5 "RESERVED_5" 6 "RESERVED_6" 7 "RESERVED_7" ;
VAL_TABLE_ RemWndOpCstChgSetReq 0 "NO_ACTION" 1 "OFF" 2 "ON" 3 "RESERVED_3" 4 "RESERVED_4" 5 "RESERVED_5" 6 "RESERVED_6" 7 "RESERVED_7" ;
VAL_TABLE_ RnSnsCstChgSetReq 0 "NO_ACTION" 1 "OFF" 2 "ON" 3 "RESERVED_3" 4 "RESERVED_4" 5 "RESERVED_5" 6 "RESERVED_6" 7 "RESERVED_7" ;
VAL_TABLE_ RmtStrtHtdStCstChgSetReq 0 "NO_ACTION" 1 "OFF" 2 "ON" 3 "RESERVED_3" 4 "RESERVED_4" 5 "RESERVED_5" 6 "RESERVED_6" 7 "RESERVED_7" ;
VAL_TABLE_ RmtStrtCoolStCstChgSetReq 0 "NO_ACTION" 1 "OFF" 2 "ON" 3 "RESERVED_3" 4 "RESERVED_4" 5 "RESERVED_5" 6 "RESERVED_6" 7 "RESERVED_7" ;
VAL_TABLE_ RnngBrdManDplyCstChgSetReq 0 "NO_ACTION" 1 "OFF" 2 "EXTEND_DOOR" 3 "EXTEND_BED" 4 "RESERVED_4 RESERVED_5" 5 "RESERVED_6" 6 "RESERVED_7" ;
VAL_TABLE_ RnngBrdAutoDplyCstChgSetReq 0 "NO_ACTION" 1 "OFF" 2 "DOOR" 3 "DOOR_PARK" 4 "RESERVED_4 RESERVED_5" 5 "RESERVED_6" 6 "RESERVED_7" ;
VAL_TABLE_ RrPCMRspTypCstChgSetReq 0 "NO_ACTION" 1 "OFF" 2 "ALERT" 3 "ALERT_AND_BRAKE" 4 "ALERT_AND_BRAKE_AND_STEER" 5 "RESERVED_5" 6 "RESERVED_6" 7 "RESERVED_7" ;
VAL_TABLE_ RrDfgStUpCstChgSetReq 0 "NO_ACTION" 1 "MANUAL" 2 "AUTOMATIC" 3 "RESERVED_3" 4 "RESERVED_4" 5 "RESERVED_5" 6 "RESERVED_6" 7 "RESERVED_7" ;
VAL_TABLE_ RrCrsTrfcAlrtCstChngSetReq 0 "NO_ACTION" 1 "OFF" 2 "ALERT" 3 "ALERT AND BRAKE" 4 "RESERVED_4" 5 "RESERVED_5" 6 "RESERVED_6" 7 "RESERVED_7" ;
VAL_TABLE_ RtLkFdbkCstChgSetReq 0 "NO_ACTION" 1 "HORN_AND_LIGHTS_OFF" 2 "HORN_AND_LIGHTS_ON" 3 "FLASH_LIGHTS_ONLY" 4 "HORN_CHIRP_ONLY" 5 "RESERVED_5" 6 "RESERVED_6" 7 "RESERVED_7" ;
VAL_TABLE_ RrVwPrkAstSymCstChgSetReq 0 "NO_ACTION" 1 "OFF" 2 "ON" 3 "RESERVED_3" 4 "RESERVED_4" 5 "RESERVED_5" 6 "RESERVED_6" 7 "RESERVED_7" ;
VAL_TABLE_ RrStRmndrEnblDsblCstChgSetReq 0 "No_Action" 1 "Off" 2 "On" ;
VAL_TABLE_ SBZAlrtCstChngSetReq 0 "NO_ACTION" 1 "OFF" 2 "ON" 3 "RESERVED_3" 4 "RESERVED_4" 5 "RESERVED_5" 6 "RESERVED_6" 7 "RESERVED_7" ;
VAL_TABLE_ RtUlkLtFbCstChgSetReq 0 "NO_ACTION" 1 "OFF" 2 "FLASH_LIGHTS_ON" 3 "RESERVED_3" 4 "RESERVED_4" 5 "RESERVED_5" 6 "RESERVED_6" 7 "RESERVED_7" ;
VAL_TABLE_ StBltTghtngCstChgSetReq 0 "NO_ACTION" 1 "OFF" 2 "ON" 3 "RESERVED_3" 4 "RESERVED_4" 5 "RESERVED_5" 6 "RESERVED_6" 7 "RESERVED_7" ;
VAL_TABLE_ SrrndVwLghtCstChgSetReq 0 "SETTING_UNKNOWN" 1 "ON" 2 "OFF" 3 "RESERVED_3" 4 "RESERVED_4" 5 "RESERVED_5" 6 "RESERVED_6" 7 "RESERVED_7" ;
VAL_TABLE_ SelUlkCstChgSetReq 0 "NO_ACTION" 1 "DRIVER_DOOR_ONLY" 2 "ALL_DOORS" 3 "RESERVED_3" 4 "RESERVED_4" 5 "RESERVED_5" 6 "RESERVED_6" 7 "RESERVED_7" ;
VAL_TABLE_ APALftSftBtnStat 0 "NOT_PRESSED" 1 "PRESSED" ;
VAL_TABLE_ TrffcLgtAsstCstChgSetReq 0 "NO_ACTION" 1 "OFF" 2 "ALERT" 3 "RESERVED_3" 4 "RESERVED_4" 5 "RESERVED_5" 6 "RESERVED_6" 7 "RESERVED_7" ;
VAL_TABLE_ TnDrvSpdLmtCstChgStReq 0 "NO_ACTION" 1 "OFF" 2 "ON" 3 "RESERVED_3" 4 "RESERVED_4" 5 "RESERVED_5" 6 "RESERVED_6" 7 "RESERVED_7" ;
VAL_TABLE_ LvlgSysAlgnMdCstChgSetReq 0 "No Action" 1 "Off" 2 "On" ;
VAL_TABLE_ LtRtHnTrCstChgSetReq 0 "NO_ACTION" 1 "LEFT_HAND_DRIVE" 2 "RIGHT_HAND_DRIVE" 3 "AUTOMATIC_WITH_GPS" 4 "RESERVED_4" 5 "RESERVED_5" 6 "RESERVED_6" 7 "RESERVED_7" ;
VAL_TABLE_ LDCLCstChgSetReq 0 "NO_ACTION" 1 "OFF" 2 "ON" 3 "RESERVED_3" 4 "RESERVED_4" 5 "RESERVED_5" 6 "RESERVED_6" 7 "RESERVED_7" ;
VAL_TABLE_ OpDrAtLOCstChgSetReq 0 "NO_ACTION" 1 "OFF" 2 "ON" 3 "RESERVED_3" 4 "RESERVED_4" 5 "RESERVED_5" 6 "RESERVED_6" 7 "RESERVED_7" ;
VAL_TABLE_ LvlgSysServMdCstChgSetReq 0 "No Action" 1 "Off" 2 "On" ;
VAL_TABLE_ LvlgSysEntEgrsMdCstChgSetReq 0 "No Action" 1 "Off" 2 "On" ;
VAL_TABLE_ PlltnCtrlCstChgSetReq 0 "NO_ACTION" 1 "OFF" 2 "ON" 3 "RESERVED_3" 4 "RESERVED_4" 5 "RESERVED_5" 6 "RESERVED_6" 7 "RESERVED_7" ;
VAL_TABLE_ PhnLtInVehCstChgSetReq 0 "NO_ACTION" 1 "OFF" 2 "ON" 3 "RESERVED_3" 4 "RESERVED_4" 5 "RESERVED_5" 6 "RESERVED_6" 7 "RESERVED_7" ;
VAL_TABLE_ PrsnlMdActAeroCstChngSetReq 0 "NO_ACTION" 1 "PERSONAL_MODE_1" 2 "PERSONAL_MODE_2" 3 "PERSONAL_MODE_3" 4 "PERSONAL_MODE_4" 5 "PERSONAL_MODE_5" 6 "PERSONAL_MODE_6" 7 "PERSONAL_MODE_7" ;
VAL_TABLE_ PrkAsstTrHtchPsntCstChgSetReq 0 "NO_ACTION" 1 "OFF_NOT_ATTACHED" 2 "ON_ATTACHED" 3 "RESERVED_3" 4 "RESERVED_4" 5 "RESERVED_5" 6 "RESERVED_6" 7 "RESERVED_7" ;
VAL_TABLE_ PrkAsstOnOffCstChgSetReq 0 "No_Action" 1 "Off" 2 "Alert" 3 "Alert_Brake" ;
VAL_TABLE_ PrsnlMdRideHghtCstChngSetReq 0 "NO_ACTION" 1 "PERSONAL_MODE_1" 2 "PERSONAL_MODE_2" 3 "PERSONAL_MODE_3" 4 "PERSONAL_MODE_4" 5 "PERSONAL_MODE_5" 6 "PERSONAL_MODE_6" 7 "PERSONAL_MODE_7" ;
VAL_TABLE_ PrsnlMdDrvlCstChngSetReq 0 "NO_ACTION" 1 "PERSONAL_MODE_1" 2 "PERSONAL_MODE_2" 3 "PERSONAL_MODE_3" 4 "PERSONAL_MODE_4" 5 "PERSONAL_MODE_5" 6 "PERSONAL_MODE_6" 7 "PERSONAL_MODE_7" ;
VAL_TABLE_ PrsnlMdBrkPdlCstChngSetReq 0 "NO_ACTION" 1 "PERSONAL_MODE_1" 2 "PERSONAL_MODE_2" 3 "PERSONAL_MODE_3" 4 "PERSONAL_MODE_4" 5 "PERSONAL_MODE_5" 6 "PERSONAL_MODE_6" 7 "PERSONAL_MODE_7" ;
VAL_TABLE_ PrsnlMdSpnCstChngSetReq 0 "NO_ACTION" 1 "PERSONAL_MODE_1" 2 "PERSONAL_MODE_2" 3 "PERSONAL_MODE_3" 4 "PERSONAL_MODE_4" 5 "PERSONAL_MODE_5" 6 "PERSONAL_MODE_6" 7 "PERSONAL_MODE_7" ;
VAL_TABLE_ PrsnlMdSndCstChngSetReq 0 "NO_ACTION" 1 "PERSONAL_MODE_1" 2 "PERSONAL_MODE_2" 3 "PERSONAL_MODE_3" 4 "PERSONAL_MODE_4" 5 "PERSONAL_MODE_5" 6 "PERSONAL_MODE_6" 7 "PERSONAL_MODE_7" ;
VAL_TABLE_ PsvUnlckCstChgSetReq 0 "NO_ACTION" 1 "DRIVER_DOOR" 2 "ALL_DOORS" 3 "OFF" 4 "RESERVED_4" 5 "RESERVED_5" 6 "RESERVED_6" 7 "RESERVED_7" ;
VAL_TABLE_ PrsnlMdStrCstChngSetReq 0 "NO_ACTION" 1 "PERSONAL_MODE_1" 2 "PERSONAL_MODE_2" 3 "PERSONAL_MODE_3" 4 "PERSONAL_MODE_4" 5 "PERSONAL_MODE_5" 6 "PERSONAL_MODE_6" 7 "PERSONAL_MODE_7" ;
VAL_TABLE_ APAFcStatCSM 0 "NO_FOCUS" 1 "FOCUS" ;
VAL_TABLE_ RemLftVehRmCstChgSetReq 0 "NO_ACTION" 1 "OFF" 2 "ON" 3 "RESERVED_3" 4 "RESERVED_4" 5 "RESERVED_5" 6 "RESERVED_6" 7 "RESERVED_7" ;
VAL_TABLE_ RemInVehRmCstChgSetReq 0 "NO_ACTION" 1 "OFF" 2 "ON" 3 "RESERVED_3" 4 "RESERVED_4" 5 "RESERVED_5" 6 "RESERVED_6" 7 "RESERVED_7" ;
VAL_TABLE_ CustMdDrvlCstChngSetReq 0 "NO ACTION" 1 "CUSTOM_MODE_1" 2 "CUSTOM_MODE_2" 3 "CUSTOM_MODE_3" 4 "CUSTOM_MODE_4" 5 "CUSTOM_MODE_5" 6 "CUSTOM_MODE_6" 7 "CUSTOM_MODE_7" ;
VAL_TABLE_ CustMdSpnCstChngSetReq 0 "NO_ACTION" 1 "CUSTOM_MODE_1" 2 "CUSTOM_MODE_2" 3 "CUSTOM_MODE_3" 4 "CUSTOM_MODE_4" 5 "CUSTOM_MODE_5" 6 "CUSTOM_MODE_6" 7 "CUSTOM_MODE_7" ;
VAL_TABLE_ CustMdSndCstChngSetReq 0 "NO_ACTION" 1 "CUSTOM_MODE_1" 2 "CUSTOM_MODE_2" 3 "CUSTOM_MODE_3" 4 "CUSTOM_MODE_4" 5 "CUSTOM_MODE_5" 6 "CUSTOM_MODE_6" 7 "CUSTOM_MODE_7" ;
VAL_TABLE_ CustMdRideHghtCstChngSetReq 0 "NO_ACTION" 1 "CUSTOM_MODE_1" 2 "CUSTOM_MODE_2" 3 "CUSTOM_MODE_3" 4 "CUSTOM_MODE_4" 5 "CUSTOM_MODE_5" 6 "CUSTOM_MODE_6" 7 "CUSTOM_MODE_7" ;
VAL_TABLE_ CustMdStrCstChngSetReq 0 "NO_ACTION" 1 "CUSTOM_MODE_1" 2 "CUSTOM_MODE_2" 3 "CUSTOM_MODE_3" 4 "CUSTOM_MODE_4" 5 "CUSTOM_MODE_5" 6 "CUSTOM_MODE_6" 7 "CUSTOM_MODE_7" ;
VAL_TABLE_ EsyExtCstChgSetReq 0 "NO_ACTION" 1 "OFF" 2 "ON" 3 "RESERVED_3" 4 "RESERVED_4" 5 "RESERVED_5" 6 "RESERVED_6" 7 "RESERVED_7" ;
VAL_TABLE_ DrvrAlrtTypCstChgStReq 0 "SETTING_UNKNOWN" 1 "CHIME" 2 "SEAT" 3 "RESERVED_3" 4 "RESERVED_4" 5 "RESERVED_5" 6 "RESERVED_6" 7 "RESERVED_7" ;
VAL_TABLE_ DayTmTlLtsCstChgSetReq 0 "NO_ACTION" 1 "OFF" 2 "ON" 3 "RESERVED_3" 4 "RESERVED_4" 5 "RESERVED_5" 6 "RESERVED_6" 7 "RESERVED_7" ;
VAL_TABLE_ FrntPCMRspTypCstChgSetReq 0 "NO_ACTION" 1 "OFF" 2 "ALERT" 3 "ALERT_AND_BRAKE" 4 "ALERT_AND_BRAKE_AND_STEER" 5 "RESERVED_5" 6 "RESERVED_6" 7 "RESERVED_7" ;
VAL_TABLE_ ExitLghtngCstChgSetReq 0 "NO_ACTION" 1 "OFF" 2 "THIRTY_SECONDS_DEFAULT" 3 "ONE_MINUTE" 4 "TWO_MINUTES" 5 "RESERVED_5" 6 "RESERVED_6" 7 "RESERVED_7" ;
VAL_TABLE_ FrwdImpMtgnOpSlctCstChgSetReq 0 "NO_ACTION" 1 "OFF" 2 "ALERT" 3 "ALERT_BRAKE" 4 "ALERT_BRAKE_STEER" 5 "RESERVED_5" 6 "RESERVED_6" 7 "RESERVED_7" ;
VAL_TABLE_ FrtRdHgtGPSCstChngSetReq 0 "NO_ACTION" 1 "OFF" 2 "ON" 3 "RESERVED_3" 4 "RESERVED_4" 5 "RESERVED_5" 6 "RESERVED_6" 7 "RESERVED_7" ;
VAL_TABLE_ HFRCCstChgSetReq 0 "NO_ACTION" 1 "OFF" 2 "OPEN_AND_CLOSE" 3 "OPEN_ONLY" 4 "RESERVED_4" 5 "RESERVED_5" 6 "RESERVED_6" 7 "RESERVED_7" ;
VAL_TABLE_ GoNotfrCstChgSetReq 0 "NO_ACTION" 1 "OFF" 2 "ON" 3 "RESERVED_3" 4 "RESERVED_4" 5 "RESERVED_5" 6 "RESERVED_6" 7 "RESERVED_7" ;
VAL_TABLE_ GlrFrHgBmRspTypCstChgSetReq 0 "NO_ACTION" 1 "AUTOMATIC_HIGH_BEAM" 2 "GLARE_FREE_HIGH_BEAM" 3 "RESERVED_3" 4 "RESERVED_4" 5 "RESERVED_5" 6 "RESERVED_6" 7 "RESERVED_7" ;
VAL_TABLE_ APAExtPrkSftBtnStat 0 "NOT_PRESSED" 1 "PRESSED" ;
VAL_TABLE_ JckKnfDtnCstChgSetReq 0 "No_Action" 1 "Off" 2 "On" ;
VAL_TABLE_ IonzrCtrlCstChgSetReq 0 "NO_ACTION" 1 "OFF" 2 "ON" 3 "RESERVED_3" 4 "RESERVED_4" 5 "RESERVED_5" 6 "RESERVED_6" 7 "RESERVED_7" ;
VAL_TABLE_ TAC_AudConctOutcm 0 "NO_ACTION" 1 "REQUEST_GRANTED" 2 "REQUEST_DENIED" 3 "RESERVED_1" 4 "RESERVED_2" 5 "RESERVED_3" 6 "RESERVED_4" 7 "RESERVED_5" 8 "RESERVED_6" 9 "RESERVED_7" 10 "RESERVED_8" 11 "RESERVED_9" 12 "RESERVED_10" 13 "RESERVED_11" 14 "RESERVED_12" 15 "RESERVED_13" ;
VAL_TABLE_ TAC_AudChConctStat 0 "NO_ACTION" 1 "MIX_PROMPT" 2 "MUTEX_PROMPT" 3 "RING_TONE" 4 "PHONE" 5 "EMERGENCY_PHONE" 6 "RESERVED_1" 7 "RESERVED_2" 8 "RESERVED_3" 9 "RESERVED_4" 10 "RESERVED_5" 11 "RESERVED_6" 12 "RESERVED_7" 13 "RESERVED_8" 14 "RESERVED_9" 15 "RESERVED_10" ;
VAL_TABLE_ TDOSWCCSR_ChgSetReq 0 "NO_ACTION" 1 "OFF" 2 "ON" 3 "RESERVED_3" 4 "RESERVED_4" 5 "RESERVED_5" 6 "RESERVED_6" 7 "RESERVED_7" ;
VAL_TABLE_ TDOSWCCSR_DecSwAct 0 "FALSE" 1 "TRUE" ;
VAL_TABLE_ TDOSWCCSR_IncSwAct 0 "FALSE" 1 "TRUE" ;
VAL_TABLE_ InfoSysStat 0 "Sleep" 1 "AnimationInit" 2 "HMI_Init" 3 "HMI_Inactive" 4 "Start" 5 "Run" 6 "Propulsion" 7 "Accessory" 8 "LocalInfotainment" 9 "LocalPhone" 10 "LocalValet" 11 "LocalEject" 12 "ValetMode" 13 "TheftLocked" 14 "NoCalibration" 15 "NoVIN" 16 "RemoteReflashProgramming" 17 "OffMode" ;
VAL_TABLE_ AirQltySensCstChgSetReq 0 "NO_ACTION" 1 "OFF" 2 "LOW_SENSITIVITY" 3 "HI_SENSITIVITY" 4 "RESERVED_4" 5 "RESERVED_5" 6 "RESERVED_6" 7 "RESERVED_7" ;
VAL_TABLE_ AdpLghtRspTypCstChgSetReq 0 "NO_ACTION" 1 "OFF" 2 "CORNER_AND_CURVE_LIGHTING" 3 "INTELLIGENT_LIGHT_DISTRIBUTION" 4 "INTELLIGENT_LIGHT_DISTRIBUTION_GPS_ASSISTANCE" 5 "RESERVED_5" 6 "RESERVED_6" 7 "RESERVED_7" ;
VAL_TABLE_ AutoAirDstCstChgSetReq 0 "NO_ACTION" 1 "DIFFUSE_AIRFLOW" 2 "NORMAL" 3 "DIRECT_AIRFLOW" 4 "OSCILLATING_AIRFLOW" 5 "RESERVED_5" 6 "RESERVED_6" 7 "RESERVED_7" ;
VAL_TABLE_ AutUnlckCstChgSetReq 0 "NO_ACTION" 1 "OFF" 2 "ALL_DOORS" 3 "DRIVER_DOOR" 4 "RESERVED_4" 5 "RESERVED_5" 6 "RESERVED_6" 7 "RESERVED_7" ;
VAL_TABLE_ AutDrvLckCstChgSetReq 0 "NO_ACTION" 1 "OFF" 2 "ON" 3 "RESERVED_3" 4 "RESERVED_4" 5 "RESERVED_5" 6 "RESERVED_6" 7 "RESERVED_7" ;
VAL_TABLE_ AutoFanCstChgSetReq 0 "NO_ACTION" 1 "LOW" 2 "NORMAL" 3 "HIGH" 4 "RESERVED_4" 5 "RESERVED_5" 6 "RESERVED_6" 7 "RESERVED_7" ;
VAL_TABLE_ AutoDfgCstChgSetReq 0 "NO_ACTION" 1 "OFF" 2 "ON" 3 "RESERVED_3" 4 "RESERVED_4" 5 "RESERVED_5" 6 "RESERVED_6" 7 "RESERVED_7" ;
VAL_TABLE_ AutoCoolStCstChgSetReq 0 "NO_ACTION" 1 "OFF" 2 "ON" 3 "RESERVED_3" 4 "RESERVED_4" 5 "RESERVED_5" 6 "RESERVED_6" 7 "RESERVED_7" ;
VAL_TABLE_ AutoMemRclCstChgSetReq 0 "NO_ACTION" 1 "OFF" 2 "ON" 3 "AUTO_MEMORY_RECALL" 4 "EASY_EXIT" 5 "AUTO_MEMORY_AND_EASY_EXIT_RECALLS" 6 "RESERVED6" 7 "RESERVED7" ;
VAL_TABLE_ AutoHtdStCstChgSetReq 0 "NO_ACTION" 1 "OFF" 2 "ON" 3 "RESERVED_3" 4 "RESERVED_4" 5 "RESERVED_5" 6 "RESERVED_6" 7 "RESERVED_7" ;
VAL_TABLE_ ClstrDspAnmReq 0 "NoAction" 1 "Ready" 2 "WelcomePlay" 3 "StartPlay" 4 "ShutdownPlay" ;
VAL_TABLE_ AutoRrWpCstChgSetReq 0 "NO_ACTION" 1 "OFF" 2 "ON" 3 "RESERVED_3" 4 "RESERVED_4" 5 "RESERVED_5" 6 "RESERVED_6" 7 "RESERVED_7" ;
VAL_TABLE_ AutoMrFldCstChgSetReq 0 "NO_ACTION" 1 "OFF" 2 "ON" 3 "RESERVED_3" 4 "RESERVED_4" 5 "RESERVED_5" 6 "RESERVED_6" 7 "RESERVED_7" ;
VAL_TABLE_ APACrssBckInSftBtnStat 0 "NOT_PRESSED" 1 "PRESSED" ;
VAL_TABLE_ CrgBedVwAutoLgtCstChgSetReq 0 "No_Action" 1 "Off" 2 "On" ;
VAL_TABLE_ IntAmbBrghtnsCtrlSetReq 0 "No Action" 1 "BrightnessLevel 1" 2 "BrightnessLevel 2" 3 "BrightnessLevel 3" 4 "BrightnessLevel 4" 5 "ReservedLevel 5" 6 "ReservedLevel 6" 7 "ReservedLevel 7" ;
VAL_TABLE_ LclTmYrVal_Inv 0 "FALSE" 1 "TRUE" ;
VAL_TABLE_ LclTmMinVal_Inv 0 "FALSE" 1 "TRUE" ;
VAL_TABLE_ LclTmDayVal_Inv 0 "FALSE" 1 "TRUE" ;
VAL_TABLE_ LclTmSecVal_Inv 0 "FALSE" 1 "TRUE" ;
VAL_TABLE_ LclTmHrVal_Inv 0 "FALSE" 1 "TRUE" ;
VAL_TABLE_ LclTmMthVal 0 "Unknown" 1 "January" 2 "February" 3 "March" 4 "April" 5 "May" 6 "June" 7 "July" 8 "August" 9 "September" 10 "October" 11 "November" 12 "December" ;
VAL_TABLE_ LclTmMthVal_Inv 0 "FALSE" 1 "TRUE" ;
VAL_TABLE_ FrtCntrStckFvrtUpSw 0 "Released" 1 "Pressed" ;
VAL_TABLE_ FrtCntrStckFvrtDnSw 0 "Released" 1 "Pressed" ;
VAL_TABLE_ FrtCntrStckEjectSw 0 "Released" 1 "Pressed" ;
VAL_TABLE_ FrtCntrStckDiscAuxSw 0 "Released" 1 "Pressed" ;
VAL_TABLE_ FrtCntrStckBndSw 0 "Released" 1 "Pressed" ;
VAL_TABLE_ FrtCntrStckBnchBtnID_VirtSw 0 "Released" 1 "Pressed" ;
VAL_TABLE_ FrtCntrStckBackSw 0 "Released" 1 "Pressed" ;
VAL_TABLE_ FrtCntrStckAllRelSw 0 "Released" 1 "Pressed" ;
VAL_TABLE_ FrtCntrStckSw24 0 "Released" 1 "Pressed" ;
VAL_TABLE_ FrtCntrStckSw23 0 "Released" 1 "Pressed" ;
VAL_TABLE_ FrtCntrStckStrgeUnlckSw 0 "Released" 1 "Pressed" ;
VAL_TABLE_ FrtCntrStckPwrSw 0 "Released" 1 "Pressed" ;
VAL_TABLE_ FrtCntrStckPrevSw 0 "Released" 1 "Pressed" ;
VAL_TABLE_ FrtCntrStckNextSw 0 "Released" 1 "Pressed" ;
VAL_TABLE_ FrtCntrStckMenuSw 0 "Released" 1 "Pressed" ;
VAL_TABLE_ FrtCntrStckHomeSw 0 "Released" 1 "Pressed" ;
VAL_TABLE_ FrtCntrStckSw32 0 "Released" 1 "Pressed" ;
VAL_TABLE_ FrtCntrStckSw31 0 "Released" 1 "Pressed" ;
VAL_TABLE_ FrtCntrStckSw30 0 "Released" 1 "Pressed" ;
VAL_TABLE_ FrtCntrStckSw29 0 "Released" 1 "Pressed" ;
VAL_TABLE_ FrtCntrStckSw28 0 "Released" 1 "Pressed" ;
VAL_TABLE_ FrtCntrStckSw27 0 "Released" 1 "Pressed" ;
VAL_TABLE_ FrtCntrStckSw26 0 "Released" 1 "Pressed" ;
VAL_TABLE_ FrtCntrStckSw25 0 "Released" 1 "Pressed" ;
VAL_TABLE_ UTCYr_Inv 0 "FALSE" 1 "TRUE" ;
VAL_TABLE_ UTCMin_Inv 0 "FALSE" 1 "TRUE" ;
VAL_TABLE_ UTCDay_Inv 0 "FALSE" 1 "TRUE" ;
VAL_TABLE_ UTCSec_Inv 0 "FALSE" 1 "TRUE" ;
VAL_TABLE_ UTCHrs_Inv 0 "FALSE" 1 "TRUE" ;
VAL_TABLE_ UTCMth 0 "Unknown" 1 "January" 2 "February" 3 "March" 4 "April" 5 "May" 6 "June" 7 "July" 8 "August" 9 "September" 10 "October" 11 "November" 12 "December" ;
VAL_TABLE_ UTCMth_Inv 0 "FALSE" 1 "TRUE" ;
VAL_TABLE_ CellNWDateTimeAvl 0 "FALSE" 1 "TRUE" ;
VAL_TABLE_ CmpsOctHding 0 "N" 1 "NE" 2 "E" 3 "SE" 4 "S" 5 "SW" 6 "W" 7 "NW" ;
VAL_TABLE_ CmpsDecZone 0 "Unknown" 1 "Zone 1" 2 "Zone 2" 3 "Zone 3" 4 "Zone 4" 5 "Zone 5" 6 "Zone 6" 7 "Zone 7" 8 "Zone 8" 9 "Zone 9" 10 "zone 10" 11 "Zone 11" 12 "Zone 12" 13 "Zone 13" 14 "Zone 14" 15 "Zone 15" ;
VAL_TABLE_ EmrgRespSysServIndOn 0 "FALSE" 1 "TRUE" ;
VAL_TABLE_ CmpsZnNvrSet 0 "False" 1 "True" ;
VAL_TABLE_ CmpsSatrtd 0 "False" 1 "True" ;
VAL_TABLE_ CmpsOctHdingDataSrc 0 "Stored Value" 1 "Calculated Value" ;
VAL_TABLE_ CmpsModManCalInPrc 0 "False" 1 "True" ;
VAL_TABLE_ CmpsModFltPrs 0 "False" 1 "True" ;
VAL_TABLE_ CldrMth 0 "Unknown" 1 "January" 2 "February" 3 "March" 4 "April" 5 "May" 6 "June" 7 "July" 8 "August" 9 "September" 10 "October" 11 "November" 12 "December" ;
VAL_TABLE_ IntDimSelAnmTypSetReq 0 "No Action" 1 "Off" 2 "Animation Type 1" 3 "Animation Type 2" 4 "Animation Type 3" 5 "Animation Type 4" 6 "Animation Type 5" 7 "Animation Type 6" 8 "Animation Type 7" 9 "Animation Type 8" 10 "Animation Type 9" 11 "Animation Type 10" 12 "Animation Type 11" 13 "Animation Type 12" 14 "Animation Type 13" 15 "Animation Type 14" ;
VAL_TABLE_ IntDimSelColTypSetReq 0 "No Action" 1 "Off" 2 "Color Type 1" 3 "Color Type 2" 4 "Color Type 3" 5 "Color Type 4" 6 "Color Type 5" 7 "Color Type 6" 8 "Color Type 7" 9 "Color Type 8" 10 "Color Type 9" 11 "Color Type 10" 12 "Color Type 11" 13 "Color Type 12" 14 "Color Type 13" 15 "Color Type 14" 16 "Color Type 15" 17 "Color Type 16" 18 "Color Type 17" 19 "Color Type 18" 20 "Color Type 19" 21 "Color Type 20" 22 "Color Type 21" 23 "Color Type 22" 24 "Color Type 23" 25 "Color Type 24" 26 "Color Type 25" 27 "Color Type 26" 28 "Color Type 27" 29 "Color Type 28" 30 "Color Type 29" 31 "Color Type 30" ;
VAL_TABLE_ RrZnStUpCstChgSetReq 0 "NO_ACTION" 1 "REAR_OFF" 2 "REAR_MIMIC_FRONT" 3 "REAR_LAST_KNOWN" 4 "RESERVED_4" 5 "RESERVED_5" 6 "RESERVED_6" 7 "RESERVED_7" ;
VAL_TABLE_ RmtSnrfOpCstChgSetReq 0 "NO_ACTION" 1 "OFF" 2 "ON" 3 "RESERVED_3" 4 "RESERVED_4" 5 "RESERVED_5" 6 "RESERVED_6" 7 "RESERVED_7" ;
VAL_TABLE_ FrtCntrStckHptcFdbkStat 0 "FEEDBACK_OFF" 1 "TAP" 2 "LONG_PRESS" 3 "PRESS_&_HOLD_SCROLL" 4 "PRESS_&_HOLD_END" 5 "RESERVED_05" 6 "RESERVED_06" 7 "RESERVED_07" 8 "RESERVED_08" 9 "RESERVED_09" 10 "RESERVED_10" 11 "RESERVED_11" 12 "RESERVED_12" 13 "RESERVED_13" 14 "RESERVED_14" 15 "RESERVED_15" ;
VAL_TABLE_ FrtCntrStckTag2Sw 0 "Released" 1 "Pressed" ;
VAL_TABLE_ FrtCntrStckTag1Sw 0 "Released" 1 "Pressed" ;
VAL_TABLE_ FrtCntrStckPrxmtyStat 0 "FAR" 1 "NEAR" 2 "TOUCH" 3 "PRESS" 4 "PROX_STAT4" 5 "PROX_STAT5" 6 "PROX_STAT6" 7 "PROX_STAT7" ;
VAL_TABLE_ FrtCntrStckPrxmtyGstr 0 "NO_ACTION" 1 "PROX_GESTURE1" 2 "PROX_GESTURE2" 3 "PROX_GESTURE3" 4 "PROX_GESTURE4" 5 "PROX_GESTURE5" 6 "PROX_GESTURE6" 7 "PROX_GESTURE7" ;
VAL_TABLE_ FrtCntrStckVolUpSw 0 "Released" 1 "Pressed" ;
VAL_TABLE_ FrtCntrStckVolDnSw 0 "Released" 1 "Pressed" ;
VAL_TABLE_ FrtCntrStckToneSw 0 "Released" 1 "Pressed" ;
VAL_TABLE_ FrtCntrStckTag5Sw 0 "Released" 1 "Pressed" ;
VAL_TABLE_ FrtCntrStckTag4Sw 0 "Released" 1 "Pressed" ;
VAL_TABLE_ FrtCntrStckTag3Sw 0 "Released" 1 "Pressed" ;
VAL_TABLE_ LnFllwgFtrStat 0 "Off" 1 "Unavailable" 2 "Disabled" 3 "Enabled" 4 "Active" 5 "Cautionary" 6 "Override" 7 "Degraded" 8 "No Return" 9 "Ended" 10 "Non-Responsive Driver" ;
VAL_TABLE_ NodeStsAPA_CAN_2_LcFA 0 "FALSE" 1 "TRUE" ;
VAL_TABLE_ NodeStsAPA_CAN_1_LcFA 0 "FALSE" 1 "TRUE" ;
VAL_TABLE_ NodeStsAOS_LcFA 0 "FALSE" 1 "TRUE" ;
VAL_TABLE_ NodeStsAMP_LcFA 0 "FALSE" 1 "TRUE" ;
VAL_TABLE_ NodeStsALC_LcFA 0 "FALSE" 1 "TRUE" ;
VAL_TABLE_ NodeStsAHL_AFL_LcFA 0 "FALSE" 1 "TRUE" ;
VAL_TABLE_ NodeStsAGC_LcFA 0 "FALSE" 1 "TRUE" ;
VAL_TABLE_ NodeStsDMS_LcFA 0 "FALSE" 1 "TRUE" ;
VAL_TABLE_ NodeStsDEFC_LcFA 0 "FALSE" 1 "TRUE" ;
VAL_TABLE_ NodeStsDCM_LcFA 0 "FALSE" 1 "TRUE" ;
VAL_TABLE_ NodeStsCSM_LcFA 0 "FALSE" 1 "TRUE" ;
VAL_TABLE_ NodeStsBSM_CAN_3_LcFA 0 "FALSE" 1 "TRUE" ;
VAL_TABLE_ NodeStsBSM_CAN_2_LcFA 0 "FALSE" 1 "TRUE" ;
VAL_TABLE_ NodeStsBCM_LcFA 0 "FALSE" 1 "TRUE" ;
VAL_TABLE_ NodeStsARB_LcFA 0 "FALSE" 1 "TRUE" ;
VAL_TABLE_ NodeStsELM_LcFA 0 "FALSE" 1 "TRUE" ;
VAL_TABLE_ NodeStsECP_X1_CAN_3_LcFA 0 "FALSE" 1 "TRUE" ;
VAL_TABLE_ NodeStsECP_X1_CAN_2_LcFA 0 "FALSE" 1 "TRUE" ;
VAL_TABLE_ NodeStsECM_CAN_3_LcFA 0 "FALSE" 1 "TRUE" ;
VAL_TABLE_ NodeStsECM_CAN_2_LcFA 0 "FALSE" 1 "TRUE" ;
VAL_TABLE_ NodeStsEBCM_CAN_2_LcFA 0 "FALSE" 1 "TRUE" ;
VAL_TABLE_ NodeStsEBCM_CAN_1_LcFA 0 "FALSE" 1 "TRUE" ;
VAL_TABLE_ NodeStsEPS_LcFA 0 "FALSE" 1 "TRUE" ;
VAL_TABLE_ NodeStsEOCM_HCP2_LcFA 0 "FALSE" 1 "TRUE" ;
VAL_TABLE_ NodeStsEOCM_HCP1_CAN_8_LcFA 0 "FALSE" 1 "TRUE" ;
VAL_TABLE_ NodeStsEOCM_HCP1_CAN_2_LcFA 0 "FALSE" 1 "TRUE" ;
VAL_TABLE_ NodeStsEOCM_HCP1_CAN_1_LcFA 0 "FALSE" 1 "TRUE" ;
VAL_TABLE_ NodeStsEOCM_CAN_8_LcFA 0 "FALSE" 1 "TRUE" ;
VAL_TABLE_ NodeStsEOCM_CAN_2_LcFA 0 "FALSE" 1 "TRUE" ;
VAL_TABLE_ NodeStsEOCM_CAN_1_LcFA 0 "FALSE" 1 "TRUE" ;
VAL_TABLE_ NodeStsIPC_LcFA 0 "FALSE" 1 "TRUE" ;
VAL_TABLE_ NodeStsICS_Info_LcFA 0 "FALSE" 1 "TRUE" ;
VAL_TABLE_ NodeStsICCM_LcFA 0 "FALSE" 1 "TRUE" ;
VAL_TABLE_ NodeStsHVAC_FP_R_LcFA 0 "FALSE" 1 "TRUE" ;
VAL_TABLE_ NodeStsHVAC_FP_F_LcFA 0 "FALSE" 1 "TRUE" ;
VAL_TABLE_ NodeStsHUD_CAN_LcFA 0 "FALSE" 1 "TRUE" ;
VAL_TABLE_ NodeStsFCM_LcFA 0 "FALSE" 1 "TRUE" ;
VAL_TABLE_ NodeStsFCM_LC_LcFA 0 "FALSE" 1 "TRUE" ;
VAL_TABLE_ NodeStsMSM_D_LcFA 0 "FALSE" 1 "TRUE" ;
VAL_TABLE_ NodeStsMSB2_LcFA 0 "FALSE" 1 "TRUE" ;
VAL_TABLE_ NodeStsMSB1_LcFA 0 "FALSE" 1 "TRUE" ;
VAL_TABLE_ NodeStsMRCM_R_LcFA 0 "FALSE" 1 "TRUE" ;
VAL_TABLE_ NodeStsMRCM_L_LcFA 0 "FALSE" 1 "TRUE" ;
VAL_TABLE_ NodeStsMFC_LcFA 0 "FALSE" 1 "TRUE" ;
VAL_TABLE_ NodeStsLRR_LcFA 0 "FALSE" 1 "TRUE" ;
VAL_TABLE_ NodeStsLRR_HC_LcFA 0 "FALSE" 1 "TRUE" ;
VAL_TABLE_ NodeStsPDR_LcFA 0 "FALSE" 1 "TRUE" ;
VAL_TABLE_ NodeStsPA_LcFA 0 "FALSE" 1 "TRUE" ;
VAL_TABLE_ NodeStsNVM_LcFA 0 "FALSE" 1 "TRUE" ;
VAL_TABLE_ NodeStsMTCM_R_LcFA 0 "FALSE" 1 "TRUE" ;
VAL_TABLE_ NodeStsMTCM_L_LcFA 0 "FALSE" 1 "TRUE" ;
VAL_TABLE_ NodeStsMSM_RR_LcFA 0 "FALSE" 1 "TRUE" ;
VAL_TABLE_ NodeStsMSM_P_LcFA 0 "FALSE" 1 "TRUE" ;
VAL_TABLE_ NodeStsMSM_LR_LcFA 0 "FALSE" 1 "TRUE" ;
VAL_TABLE_ NodeStsSBZA_R_LcFA 0 "FALSE" 1 "TRUE" ;
VAL_TABLE_ NodeStsSBZA_L_LcFA 0 "FALSE" 1 "TRUE" ;
VAL_TABLE_ NodeStsSADS_LcFA 0 "FALSE" 1 "TRUE" ;
VAL_TABLE_ NodeStsAHS_LcFA 0 "FALSE" 1 "TRUE" ;
VAL_TABLE_ NodeStsRSC_LcFA 0 "FALSE" 1 "TRUE" ;
VAL_TABLE_ NodeStsRDCM_LcFA 0 "FALSE" 1 "TRUE" ;
VAL_TABLE_ NodeStsRadioLow_LcFA 0 "FALSE" 1 "TRUE" ;
VAL_TABLE_ NodeStsPTM_LcFA 0 "FALSE" 1 "TRUE" ;
VAL_TABLE_ NodeStsSRR_SLR_LcFA 0 "FALSE" 1 "TRUE" ;
VAL_TABLE_ NodeStsSRR_RR_LcFA 0 "FALSE" 1 "TRUE" ;
VAL_TABLE_ NodeStsSRR_RF_LcFA 0 "FALSE" 1 "TRUE" ;
VAL_TABLE_ NodeStsSRR_LR_CR_LcFA 0 "FALSE" 1 "TRUE" ;
VAL_TABLE_ NodeStsSRR_LF_LcFA 0 "FALSE" 1 "TRUE" ;
VAL_TABLE_ NodeStsSIB_LcFA 0 "FALSE" 1 "TRUE" ;
VAL_TABLE_ NodeStsSDM_LcFA 0 "FALSE" 1 "TRUE" ;
VAL_TABLE_ NodeStsSCL_LcFA 0 "FALSE" 1 "TRUE" ;
VAL_TABLE_ NodeStsTIM_LcFA 0 "FALSE" 1 "TRUE" ;
VAL_TABLE_ NodeStsTCP_LcFA 0 "FALSE" 1 "TRUE" ;
VAL_TABLE_ NodeStsTCM_LcFA 0 "FALSE" 1 "TRUE" ;
VAL_TABLE_ NodeStsTCCM3_LcFA 0 "FALSE" 1 "TRUE" ;
VAL_TABLE_ NodeStsTCCM_LcFA 0 "FALSE" 1 "TRUE" ;
VAL_TABLE_ NodeStsSTC_LcFA 0 "FALSE" 1 "TRUE" ;
VAL_TABLE_ NodeStsSRR_SRR_LcFA 0 "FALSE" 1 "TRUE" ;
VAL_TABLE_ NodeStsECP_E_CAN_9_LcFA 0 "FALSE" 1 "TRUE" ;
VAL_TABLE_ NodeStsCMMb_CAN_2_LcFA 0 "FALSE" 1 "TRUE" ;
VAL_TABLE_ NodeStsCMMa_CAN_2_LcFA 0 "FALSE" 1 "TRUE" ;
VAL_TABLE_ NodeStsARS_LcFA 0 "FALSE" 1 "TRUE" ;
VAL_TABLE_ NodeStsVLM_LcFA 0 "FALSE" 1 "TRUE" ;
VAL_TABLE_ NodeStsWCM_LcFA 0 "FALSE" 1 "TRUE" ;
VAL_TABLE_ NodeStsVPM_LcFA 0 "FALSE" 1 "TRUE" ;
VAL_TABLE_ NodeStsVKM_LcFA 0 "FALSE" 1 "TRUE" ;
VAL_TABLE_ NodeStsECP_E_CAN_2_LcFA 0 "FALSE" 1 "TRUE" ;
VAL_TABLE_ NodeStsECP_MC_LcFA 0 "FALSE" 1 "TRUE" ;
VAL_TABLE_ NodeStsCMMb_CAN_9_LcFA 0 "FALSE" 1 "TRUE" ;
VAL_TABLE_ NodeStsCMMa_CAN_9_LcFA 0 "FALSE" 1 "TRUE" ;
VAL_TABLE_ NodeStsBSM_MH_LcFA 0 "FALSE" 1 "TRUE" ;
VAL_TABLE_ NodeStsSBM_CAN_9_LcFA 0 "FALSE" 1 "TRUE" ;
VAL_TABLE_ NodeStsSBM_CAN_10_LcFA 0 "FALSE" 1 "TRUE" ;
VAL_TABLE_ NodeStsLIB1_LcFA 0 "FALSE" 1 "TRUE" ;
VAL_TABLE_ NodeStsHDLM_LcFA 0 "FALSE" 1 "TRUE" ;
VAL_TABLE_ LVMAVR_StreoAudReq 0 "NO_ACTION" 1 "STEREO_REQUEST" ;
VAL_TABLE_ LVMAVR_SpchRcgnActv 0 "NO_ACTION" 1 "LVM_SPEECH_REC_READY" 2 "LVM_SPEECH_REC_ACTIVE" ;
VAL_TABLE_ LVMAVR_PrmtAudReq 0 "NO_ACTION" 1 "PROMPT_REQUEST" ;
VAL_TABLE_ LVMAVR_DispReq 0 "NO_ACTION" 1 "LVM_NAV" 2 "LVM_DMB" 3 "LVM_PDR" ;
VAL_TABLE_ IconRcrdReqActv 0 "FALSE" 1 "TRUE" ;
VAL_TABLE_ LVMAVR_ApplStat 0 "NO_ACTION" 1 "LVM_NAV" 2 "LVM_DMB" 3 "LVM_PERFORMANCE_COMPUTER" 4 "LVM_COMPLEX_MODE" ;
VAL_TABLE_ PSP_VehTheftImbChlgRespStsAuth 0 "Undetermined" 1 "Pass" 2 "Fail" ;
VAL_TABLE_ PSP_RmtVehStrtEngRnngAuth 0 "FALSE" 1 "TRUE" ;
VAL_TABLE_ PSP_PwrtrnCrnkAbrtdAuth 0 "FALSE" 1 "TRUE" ;
VAL_TABLE_ PSP_PrplSysStlActvAuth 0 "FALSE" 1 "TRUE" ;
VAL_TABLE_ PSP_PrplSysActvAuth 0 "FALSE" 1 "TRUE" ;
VAL_TABLE_ PSP_EngRnngAuth 0 "FALSE" 1 "TRUE" ;
VAL_TABLE_ PSP_ClchBtmTrvlAchvdAuth_Inv 0 "FALSE" 1 "TRUE" ;
VAL_TABLE_ PSP_ClchBtmTrvlAchvdAuth 0 "FALSE" 1 "TRUE" ;
VAL_TABLE_ PSP_PrkNeutSwStatAuth_Inv 0 "FALSE" 1 "TRUE" ;
VAL_TABLE_ PSP_PrkNeutSwStatAuth 0 "Park/Neutral" 1 "Not Park/Neutral" ;
VAL_TABLE_ PCIP_MemStRclDsblReqdAuth 0 "FALSE" 1 "TRUE" ;
VAL_TABLE_ PCIP_IntrLgtOnReqdAuth 0 "FALSE" 1 "TRUE" ;
VAL_TABLE_ PCIP_HzrdLgtsOnReqdAuth 0 "FALSE" 1 "TRUE" ;
VAL_TABLE_ PCIP_HybVehHiVltgDsblReqdAuth 0 "FALSE" 1 "TRUE" ;
VAL_TABLE_ PCIP_HVACBlwDsblReqdAuth 0 "FALSE" 1 "TRUE" ;
VAL_TABLE_ PCIP_FuelCutOffReqdAuth 0 "FALSE" 1 "TRUE" ;
VAL_TABLE_ PCIP_DrUnlckReqdAuth 0 "FALSE" 1 "TRUE" ;
VAL_TABLE_ PCIP_BrkActReqdAuth 0 "FALSE" 1 "TRUE" ;
VAL_TABLE_ PCIP_NftnFrtImpPrtnsrSevAchAuth 0 "FALSE" 1 "TRUE" ;
VAL_TABLE_ PCIP_NtfnRlOvrSevAchvdAuth 0 "FALSE" 1 "TRUE" ;
VAL_TABLE_ PCIP_NtfnPedtrnPrtctnSevAchAuth 0 "FALSE" 1 "TRUE" ;
VAL_TABLE_ PCIP_NtfnLtSdSevAchvdAuth 0 "FALSE" 1 "TRUE" ;
VAL_TABLE_ PCIP_NtfnFrtImpStg2SevAchvdAuth 0 "FALSE" 1 "TRUE" ;
VAL_TABLE_ PCIP_NtfnFrtImpStg1SevAchvdAuth 0 "FALSE" 1 "TRUE" ;
VAL_TABLE_ PCIP_NtfnEvntStsAuth 0 "No Event" 1 "Near Deploy Event" 2 "Deployment Event" ;
VAL_TABLE_ PCIP_HVCrshImpSnsSysDsbldAuth 0 "FALSE" 1 "TRUE" ;
VAL_TABLE_ PCIP_CruzCtlDsblReqdAuth 0 "FALSE" 1 "TRUE" ;
VAL_TABLE_ PCIP_eCallReqdAuth 0 "FALSE" 1 "TRUE" ;
VAL_TABLE_ PCIP_NtfnRtSdSevAchvdAuth 0 "FALSE" 1 "TRUE" ;
VAL_TABLE_ PCIP_NtfnRrImpSevAchvdAuth 0 "FALSE" 1 "TRUE" ;
VAL_TABLE_ PSIP_StrgAsstRdcdLvl3IndOnAuth 0 "FALSE" 1 "TRUE" ;
VAL_TABLE_ PSIP_StrgAsstRdcdLvl2IndOnAuth 0 "FALSE" 1 "TRUE" ;
VAL_TABLE_ PSIP_StrgAsstRdcdIndOnAuth 0 "FALSE" 1 "TRUE" ;
VAL_TABLE_ PSIP_PwrStrgIndOnAuth 0 "FALSE" 1 "TRUE" ;
VAL_TABLE_ RPPSDBG2P_CldrYrAuth_Inv 0 "FALSE" 1 "TRUE" ;
VAL_TABLE_ RPPSDBG2P_ElvtnAuth_Inv 0 "FALSE" 1 "TRUE" ;
VAL_TABLE_ RPPSDBG2P_LngAuth_Inv 0 "FALSE" 1 "TRUE" ;
VAL_TABLE_ RPPSDBG3P_LocUsblAuth_Inv 0 "FALSE" 1 "TRUE" ;
VAL_TABLE_ RPPSDBG3P_LocUsblAuth 0 "FALSE" 1 "TRUE" ;
VAL_TABLE_ RPPSDBG3P_LatAuth_Inv 0 "FALSE" 1 "TRUE" ;
VAL_TABLE_ RPPSDBG3P_TmOfDyAuth_Inv 0 "FALSE" 1 "TRUE" ;
VAL_TABLE_ RPPSDBG4P_2DAbsPsErrEstAuth_Inv 0 "FALSE" 1 "TRUE" ;
VAL_TABLE_ RPPSDBG4P_AbsHdgErrEstAuth_Inv 0 "FALSE" 1 "TRUE" ;
VAL_TABLE_ RPPSDBG4P_CldrDyAuth_Inv 0 "FALSE" 1 "TRUE" ;
VAL_TABLE_ RPPSDBG4P_SigAcqTmAuth_Inv 0 "FALSE" 1 "TRUE" ;
VAL_TABLE_ RPPSDBG1P_HdgAuth_Inv 0 "FALSE" 1 "TRUE" ;
VAL_TABLE_ RPPSDBG5P_GPSModeAuth_Inv 0 "FALSE" 1 "TRUE" ;
VAL_TABLE_ RPPSDBG5P_GPSModeAuth 0 "GNSS Standalone" 1 "GNSS and SBAS" 2 "GNSS and RTX" 3 "GNSS and DR" 4 "GNSS and SBAS and DR" 5 "GNSS and RTX and DR" 6 "DR ONLY" 7 "GNSS and RTX and DR and MM" ;
VAL_TABLE_ RPPSDBG5P_LwrGblTmStmAuth_Inv 0 "FALSE" 1 "TRUE" ;
VAL_TABLE_ RrSeatCtrlrPrsnt 0 "RSC_NotPresent" 1 "RSC_Present" ;
VAL_TABLE_ RrSeatCtrlrBttns 0 "RSC_VOLUME_UP" 1 "RSC_VOLUME_DOWN" 2 "RSC_POWER" 3 "RSC_SOURCE_SELECT" 4 "RSC_PRESET" 5 "RSC_SEEK_UP" 6 "RSC_SEEK_DOWN" 7 "RSC_OK" 8 "RSC_BUTTON8" 9 "RSC_BUTTON9" 10 "RSC_BUTTON10" 11 "RSC_BUTTON11" 12 "RSC_BUTTON12" 13 "RSC_BUTTON13" 14 "RSC_BUTTON14" 15 "RSC_NONE" ;
VAL_TABLE_ RIP_RmtIgnBlkImbCustClrCmdAuth 0 "FALSE" 1 "TRUE" ;
VAL_TABLE_ RIP_PreRelAllwdAuth 0 "FALSE" 1 "TRUE" ;
VAL_TABLE_ RIP_NewFobXmtrLrndNtfnAuth 0 "FALSE" 1 "TRUE" ;
VAL_TABLE_ RIP_FrtCmptRelEnblReqAuth 0 "No_Action" 1 "Ajar" 2 "Open" ;
VAL_TABLE_ RIP_ElecStrgColUnlckAllwdAuth 0 "FALSE" 1 "TRUE" ;
VAL_TABLE_ RIP_StrtStopIgnSwPrssdAuth 0 "FALSE" 1 "TRUE" ;
VAL_TABLE_ RrCrsTrfcBrkgAutoBrkgRelIndOn 0 "FALSE" 1 "TRUE" ;
VAL_TABLE_ SWIP_StrgWhlAngAuth_DuD 0 "FALSE" 1 "TRUE" ;
VAL_TABLE_ SWIP_StrgWhlAngCalStsAuth 0 "Unknown" 1 "Estimated" 2 "Calibrated" ;
VAL_TABLE_ SWIP_StrgWhlAngAuth_Inv 0 "FALSE" 1 "TRUE" ;
VAL_TABLE_ SSVI_PrssClchPrssStrtAgnIO 0 "FALSE" 1 "TRUE" ;
VAL_TABLE_ SSVI_NoRmtDtdIO 0 "FALSE" 1 "TRUE" ;
VAL_TABLE_ SSVI_AutoShtdnDsbldIO 0 "FALSE" 1 "TRUE" ;
VAL_TABLE_ SSVI_ShfToNeutPrssStrtAgnIO 0 "FALSE" 1 "TRUE" ;
VAL_TABLE_ SSVI_AutoShtdnIO 0 "FALSE" 1 "TRUE" ;
VAL_TABLE_ SSVI_AppPrkBrkIO 0 "FALSE" 1 "TRUE" ;
VAL_TABLE_ SSVI_AppBrkPedIO 0 "FALSE" 1 "TRUE" ;
VAL_TABLE_ SSVI_PrssStrtAgnIO 0 "FALSE" 1 "TRUE" ;
VAL_TABLE_ SSVI_ShfToPrkIO 0 "FALSE" 1 "TRUE" ;
VAL_TABLE_ SSVI_AppClchPedIO 0 "FALSE" 1 "TRUE" ;
VAL_TABLE_ SSVI_NoRmtDtdPrssBrkToRestrtIO 0 "FALSE" 1 "TRUE" ;
VAL_TABLE_ SSVI_PrssBtnAgnToTrnEngOffIO 0 "FALSE" 1 "TRUE" ;
VAL_TABLE_ ShfToNeutRestrtVehIndOn 0 "FALSE" 1 "TRUE" ;
VAL_TABLE_ RestrtVehIndOn 0 "FALSE" 1 "TRUE" ;
VAL_TABLE_ SSVI_KeyMvmtRqrdIndOn 0 "FALSE" 1 "TRUE" ;
VAL_TABLE_ SSVI_PrssClchBrkForStrtIO 0 "FALSE" 1 "TRUE" ;
VAL_TABLE_ SSVI_ClsEngCmptToStrtVehIO 0 "FALSE" 1 "TRUE" ;
VAL_TABLE_ SSVI_KylsStrtUseXmtrPcktIO 0 "FALSE" 1 "TRUE" ;
VAL_TABLE_ SSVI_NoRmtDtdPrssClchToRestrtIO 0 "FALSE" 1 "TRUE" ;
VAL_TABLE_ VehInNeutShfToDrvIndOn 0 "FALSE" 1 "TRUE" ;
VAL_TABLE_ SPMP_SysPwrModeAuth_Inv 0 "FALSE" 1 "TRUE" ;
VAL_TABLE_ SPMP_SysPwrModeAuth 0 "Off" 1 "Accessory" 2 "Run" 3 "Start Request" 4 "Propulsion" ;
VAL_TABLE_ SPMP_PriRunCrnkCmdActvAuth_Inv 0 "FALSE" 1 "TRUE" ;
VAL_TABLE_ SPMP_PriRunCrnkCmdActvAuth 0 "FALSE" 1 "TRUE" ;
VAL_TABLE_ EmrgRespSysTyp 0 "Unknown" 1 "none" 2 "Onstar" 3 "eCall" 4 "ChevyStar" 5 "ERA" 6 "Generic" ;
VAL_TABLE_ ASVSC_ReqEnbld 0 "FALSE" 1 "TRUE" ;
VAL_TABLE_ TBTTrnChmEvntStat 0 "NO_ACTION" 1 "ACTIVE" 2 "CANCEL_CHIME" ;
VAL_TABLE_ AudSeltdSrcReq 0 "No Action" 1 "AM" 2 "FM" 3 "XM" 4 "DAB" 5 "MediaPlayer" 6 "IPOD" 7 "Bluetooth" 8 "AUX" 9 "Audio Disk Player" 10 "LVM Stereo Audio" 11 "Internet App Audio" 12 "RSI_1" 13 "RSI_2" 14 "RadioSourceReserve14" 15 "RadioSourceReserve15" 16 "RadioSourceReserve16" 17 "RadioSourceReserve17" 18 "RadioSourceReserve18" 19 "RadioSourceReserve19" 20 "RadioSourceReserve20" 21 "RadioSourceReserve21" 22 "RadioSourceReserve22" 23 "RadioSourceReserve23" 24 "RadioSourceReserve24" 25 "RadioSourceReserve25" 26 "RadioSourceReserve26" 27 "RadioSourceReserve27" 28 "RadioSourceReserve29" 29 "RadioSourceReserve30" 30 "RadioSourceReserve31" ;
VAL_TABLE_ SuprCruzSbscrptnActv 0 "FALSE" 1 "TRUE" ;
VAL_TABLE_ InfoActivtnReq 0 "FALSE" 1 "TRUE" ;
VAL_TABLE_ TnrFreqBndReq 0 "No Action" 1 "Off" 2 "AM" 3 "FM" 4 "DAB" 5 "XM" 6 "RadioBandReserve6" 7 "RadioBandReserve7" 8 "RadioBandReserve8" 9 "RadioBandReserve9" 10 "RadioBandReserve10" 11 "RadioBandReserve11" 12 "RadioBandReserve12" 13 "RadioBandReserve13" 14 "RadioBandReserve14" 15 "RadioBandReserve15" ;
VAL_TABLE_ TAR_AudSrcStat 0 "NO_ACTION" 1 "AUDIO_READY" 2 "AUDIO_PLAYING" 3 "AUDIO_REQUEST" 4 "AUDIO_DISCONNECT RESERVED_1" 5 "RESERVED_2" 6 "RESERVED_3" 7 "RESERVED_4" 8 "RESERVED_5" 9 "RESERVED_6" 10 "RESERVED_7" 11 "RESERVED_8" 12 "RESERVED_9" 13 "RESERVED_10" 14 "RESERVED_11" ;
VAL_TABLE_ TAR_AudConctReq 0 "NO ACTION" 1 "MIX_PROMPT" 2 "MUTEX_PROMPT" 3 "RING_TONE" 4 "PHONE" 5 "EMERGENCY_PHONE" 6 "RESERVED_1" 7 "RESERVED_2" 8 "RESERVED_3" 9 "RESERVED_4" 10 "RESERVED_5" 11 "RESERVED_6" 12 "RESERVED_7" 13 "RESERVED_8" 14 "RESERVED_9" 15 "RESERVED_10" ;
VAL_TABLE_ RmtRflshUpdAvlbl 0 "FALSE" 1 "TRUE" ;
VAL_TABLE_ TGPSDSP_DateSrcAuth_Inv 0 "FALSE" 1 "TRUE" ;
VAL_TABLE_ TGPSDSP_DateSrcAuth 0 "Signal_Unavailable" 1 "GPP_Used_GNSS_RTC_Unavailable" 2 "Adjusted_RTC_Used_GPP_Unavailable" 3 "Adjusted_RTC_Used_GPP_Available" 4 "GNSS_GPP_Unavailable" 5 "GNSS_GPP_Time_synchronized" ;
VAL_TABLE_ TGPSDSP_UTCMonthAuth_Inv 0 "FALSE" 1 "TRUE" ;
VAL_TABLE_ TGPSDSP_UTCMonthAuth 0 "Unknown" 1 "January" 2 "February" 3 "March" 4 "April" 5 "May" 6 "June" 7 "July" 8 "August" 9 "September" 10 "October" 11 "November" 12 "December" ;
VAL_TABLE_ TGPSDSP_UTCDyAuth_Inv 0 "FALSE" 1 "TRUE" ;
VAL_TABLE_ TGPSDSP_UTCYrAuth_Inv 0 "FALSE" 1 "TRUE" ;
VAL_TABLE_ TGPSTSP_TmSrcAuth_Inv 0 "FALSE" 1 "TRUE" ;
VAL_TABLE_ TGPSTSP_TmSrcAuth 0 "Signal_Unavailable" 1 "GPP_Used_GNSS_RTC_Unavailable" 2 "Adjusted_RTC_Used_GPP_Unavailable" 3 "Adjusted_RTC_Used_GPP_Available" 4 "GNSS_GPP_Unavailable" 5 "GNSS_GPP_Time_synchronized" ;
VAL_TABLE_ TGPSTSP_UTCHrsAuth_Inv 0 "FALSE" 1 "TRUE" ;
VAL_TABLE_ TGPSTSP_UTCSecsAuth_Inv 0 "FALSE" 1 "TRUE" ;
VAL_TABLE_ TGPSTSP_UTCMinsAuth_Inv 0 "FALSE" 1 "TRUE" ;
VAL_TABLE_ TGI1P_NewFobXmtrLrndRstAuth 0 "FALSE" 1 "TRUE" ;
VAL_TABLE_ TGI1P_EnhdServsLckReqAuth 0 "Lock All" 1 "Unlock All" 2 "No Action" ;
VAL_TABLE_ TGI1P_TlmRmtIgnBlkImbCmdAuth 0 "FALSE" 1 "TRUE" ;
VAL_TABLE_ TGI1P_EnhdServsRmtStrtReqAuth 0 "No Activation" 1 "Engine Requested Off" 2 "Engine Requested On" ;
VAL_TABLE_ TSGI1P_EnhdServsSnrfRqAuth 0 "No Request" 1 "Fully Open" 2 "Open Vent" 3 "Fully Closed" ;
VAL_TABLE_ TSGI1P_EnhdServsRrClsrLckRqAuth 0 "No Request" 1 "Unlock" 2 "Lock" ;
VAL_TABLE_ TSGI1P_EnhdServsAllWndRqAuth 0 "No Request" 1 "Fully Open" 2 "Open Vent" 3 "Fully Closed" ;
VAL_TABLE_ TVKRP_FobAvlReqAuth 0 "No Action" 1 "Disable" 2 "Enable" 3 "Return Results" ;
VAL_TABLE_ TVKRP_VirtKeyRsrvtnRvkReqAuth 0 "No Action" 1 "Revoke Certificate" 2 "Revoke All Certificates" ;
VAL_TABLE_ HtchVwAutoElecPrkBrkAppReqd 0 "FALSE" 1 "TRUE" ;
VAL_TABLE_ TrlrVidVwPhs1ChmEvntStat 0 "No Action" 1 "Active" 2 "Cancel Chime" ;
VAL_TABLE_ VidTrlrTowPhs2ChmEvntStat 0 "NO_ACTION" 1 "ACTIVE" 2 "CANCEL_CHIME" ;
VAL_TABLE_ VidTrlrTowPhs1ChmEvntStat 0 "NO_ACTION" 1 "ACTIVE" 2 "CANCEL_CHIME" ;
VAL_TABLE_ TrnsOilTmp_Inv 0 "FALSE" 1 "TRUE" ;
VAL_TABLE_ TrnsThrmlMngmntSt 0 "Normal" 1 "Countermeasures Active" 2 "Driver Intervention Requested" ;
VAL_TABLE_ TBIP_TrlrBrkgGainSetIndOnAuth 0 "FALSE" 1 "TRUE" ;
VAL_TABLE_ TBIP_TrlrWrgFltIndOnAuth 0 "FALSE" 1 "TRUE" ;
VAL_TABLE_ TBIP_ServTrlrBrkgSysIndOnAuth 0 "FALSE" 1 "TRUE" ;
VAL_TABLE_ TBIP_TrlrBrkDsbldIndOnAuth 0 "FALSE" 1 "TRUE" ;
VAL_TABLE_ TBIP_CkTrlrIndOnAuth 0 "FALSE" 1 "TRUE" ;
VAL_TABLE_ TGI2P_TrnsOutShftAngVelAuth_Inv 0 "FALSE" 1 "TRUE" ;
VAL_TABLE_ VMMP_VehMtnMvmtStatAuth 0 "Parked" 1 "Neutral" 2 "Forward" 3 "Reverse" 4 "Invalid" ;
VAL_TABLE_ VODVP_VehOdoDispValAuth_Inv 0 "FALSE" 1 "TRUE" ;
VAL_TABLE_ VOSDVP_VehOdoStrdDspValAuth_Inv 0 "FALSE" 1 "TRUE" ;
VAL_TABLE_ VSADP_VehSpdAvgDrvnAuth_Inv 0 "FALSE" 1 "TRUE" ;
VAL_TABLE_ VSADP_FuelModeStsAuth 0 "Unknown" 1 "Gasoline Mode" 2 "Natural Gas Mode" 3 "Liquified Petroleum Gas Mode" 4 "Alternative Fuel Cut-off Active" ;
VAL_TABLE_ VSADP_RdcdPwrIndOnAuth 0 "FALSE" 1 "TRUE" ;
VAL_TABLE_ VSADP_VehSpdAvgDrvnSrcAuth 0 "Transmission Output Speed" 1 "Wheel Speed" ;
VAL_TABLE_ VSANDP_VehSpdAvgNDrvnAuth_Inv 0 "FALSE" 1 "TRUE" ;
VAL_TABLE_ VKI2P_FobAvlStsAuth 0 "No Action" 1 "Disabled" 2 "Enabled" 3 "Fail" ;
VAL_TABLE_ VKI3P_PncHrnReqAuth 0 "No Action" 1 "Active" 2 "Cancel Horn" ;
VAL_TABLE_ VKI3P_MirUnfldReqdAuth 0 "FALSE" 1 "TRUE" ;
VAL_TABLE_ VKI3P_MirFoldReqdAuth 0 "FALSE" 1 "TRUE" ;
VAL_TABLE_ VKI3P_FobAvlReqAuth 0 "No Action" 1 "Enable" 2 "Disable" 3 "Return Status" ;
VAL_TABLE_ VKI3P_ChrgOnReqdAuth 0 "FALSE" 1 "TRUE" ;
VAL_TABLE_ VKI3P_ChrgOffReqdAuth 0 "FALSE" 1 "TRUE" ;
VAL_TABLE_ VKI3P_RmtLctrHrnReqAuth 0 "No_Action" 1 "Active_Low" 2 "Active_Med" 3 "Active_High" 4 "Cancel_Horn" ;
VAL_TABLE_ VKI3P_RmtFlOprtdHtrOnReqdAuth 0 "FALSE" 1 "TRUE" ;
VAL_TABLE_ VKI3P_RmtFlOprtdHtrOffReqdAuth 0 "FALSE" 1 "TRUE" ;
VAL_TABLE_ VKI3P_PwrToPCtlReqAuth 0 "No Action" 1 "Open" 2 "Close" 3 "Stop" 4 "Pause" ;
VAL_TABLE_ VKI3P_PncLgtReqAuth 0 "No Action" 1 "Active" 2 "Cancel Light" ;
VAL_TABLE_ VKI3P_VehStrtReqdAuth 0 "FALSE" 1 "TRUE" ;
VAL_TABLE_ VKI3P_VehStopReqdAuth 0 "FALSE" 1 "TRUE" ;
VAL_TABLE_ VKI3P_RsrvtnRvkStsAuth 0 "No Action" 1 "Write Failure" 2 "Revoke Certificate Successful" 3 "Certificate Not Found" 4 "No Certificates Stored" ;
VAL_TABLE_ VKI3P_RmtLctrLgtReqAuth 0 "No_Action" 1 "Active" ;
VAL_TABLE_ VKI3P_WndOpnReqdAuth 0 "FALSE" 1 "TRUE" ;
VAL_TABLE_ VKI3P_WndClsReqdAuth 0 "FALSE" 1 "TRUE" ;
VAL_TABLE_ VKIP_ExtLtStsAuth 0 "Idle" 1 "Auth in Process" 2 "Auth in Process - Single Authenticated" 3 "Auth Complete - Not Authenticated" 4 "Auth Complete - Authenticated" 5 "Auth Complete - Undetermined" ;
VAL_TABLE_ VKIP_ExtFrtStsAuth 0 "Idle" 1 "Auth in Process" 2 "Auth in Process - Single Authenticated" 3 "Auth Complete - Not Authenticated" 4 "Auth Complete - Authenticated" 5 "Auth Complete - Undetermined" ;
VAL_TABLE_ VKIP_DrvrDrUnlckReqdAuth 0 "FALSE" 1 "TRUE" ;
VAL_TABLE_ VKIP_DrLckReqdAuth 0 "FALSE" 1 "TRUE" ;
VAL_TABLE_ VKIP_AllDrUnlckReqdAuth 0 "FALSE" 1 "TRUE" ;
VAL_TABLE_ VKIP_FrtCmptRelReqdAuth 0 "FALSE" 1 "TRUE" ;
VAL_TABLE_ VKIP_ExtRtStsAuth 0 "Idle" 1 "Auth in Process" 2 "Auth in Process - Single Authenticated" 3 "Auth Complete - Not Authenticated" 4 "Auth Complete - Authenticated" 5 "Auth Complete - Undetermined" ;
VAL_TABLE_ VKIP_ExtRrStsAuth 0 "Idle" 1 "Auth in Process" 2 "Auth in Process - Single Authenticated" 3 "Auth Complete - Not Authenticated" 4 "Auth Complete - Authenticated" 5 "Auth Complete - Undetermined" ;
VAL_TABLE_ VKIP_PwrRrClsrCtlReqAuth 0 "No Action" 1 "Stop" 2 "Start" ;
VAL_TABLE_ VKIP_FrtRtEntZnDevPrsntAuth 0 "FALSE" 1 "TRUE" ;
VAL_TABLE_ VKIP_RrLtEntZnDevPrsntAuth 0 "FALSE" 1 "TRUE" ;
VAL_TABLE_ VKIP_FrtLtEntZnDevPrsntAuth 0 "FALSE" 1 "TRUE" ;
VAL_TABLE_ VKIP_WlcmZnDevPrsntAuth 0 "FALSE" 1 "TRUE" ;
VAL_TABLE_ VKIP_RrRtEntZnDevPrsntAuth 0 "FALSE" 1 "TRUE" ;
VAL_TABLE_ VKIP_RrExtZnDevPrsntAuth 0 "FALSE" 1 "TRUE" ;
VAL_TABLE_ VKIP_RrClsrRelReqdAuth 0 "FALSE" 1 "TRUE" ;
VAL_TABLE_ VKIP_RrClsrOnAprchReqdAuth 0 "FALSE" 1 "TRUE" ;
VAL_TABLE_ PhnLtInVehCstAvlFlg7 0 "FALSE" 1 "TRUE" ;
VAL_TABLE_ PhnLtInVehCstAvlFlg6 0 "FALSE" 1 "TRUE" ;
VAL_TABLE_ PhnLtInVehCstAvlFlg5 0 "FALSE" 1 "TRUE" ;
VAL_TABLE_ PhnLtInVehCstAvlFlg4 0 "FALSE" 1 "TRUE" ;
VAL_TABLE_ PhnLtInVehCstAvlFlg3 0 "FALSE" 1 "TRUE" ;
VAL_TABLE_ PhnLtInVehCstAvlFlg2 0 "FALSE" 1 "TRUE" ;
VAL_TABLE_ PhnLtInVehCstAvlFlg1 0 "FALSE" 1 "TRUE" ;
VAL_TABLE_ PhnLtInVehIndOn 0 "FALSE" 1 "TRUE" ;
VAL_TABLE_ WrlsChrgSysChrgStat 0 "WCS Not Present" 1 "Charging Inactive" 2 "Charging Active" 3 "Charging Complete" 4 "Foreign Object Detected" 5 "WCS Overtemp Shutdown" 6 "Reserved 1" 7 "Reserved 2" ;
VAL_TABLE_ PhnLtInVehCstSetAval 0 "FALSE" 1 "TRUE" ;
VAL_TABLE_ PhnLtInVehCstCurrSetVal 0 "Setting_Unknown" 1 "Off" 2 "On" 3 "Reserved_3" 4 "Reserved_4" 5 "Reserved_5" 6 "Reserved_6" 7 "Reserved_7" ;

BO_ 1110 AMP_CAN5_PDU01: 8 AMP
 SG_ ASS_PhLckdLpLckd : 0|1@0+ (1,0) [0|1] "" CSM
 SG_ ASS_DSPMd7Prsnt : 1|1@0+ (1,0) [0|1] "" CSM
 SG_ ASS_DSPMd0Prsnt : 2|1@0+ (1,0) [0|1] "" CSM
 SG_ ASS_DSPMd5Prsnt : 3|1@0+ (1,0) [0|1] "" CSM
 SG_ ASS_VehNoisCmpnAvail : 4|1@0+ (1,0) [0|1] "" CSM
 SG_ ASS_DSPAvail : 5|1@0+ (1,0) [0|1] "" CSM
 SG_ ASS_DSPMd1Prsnt : 6|1@0+ (1,0) [0|1] "" CSM
 SG_ ASS_SurndAvail : 7|1@0+ (1,0) [0|1] "" CSM
 SG_ CrtclChmPrdcrStat : 10|12@0+ (1,0) [0|4095] "msec" CSM,IPC,RadioLow
 SG_ ASS_DSPMd4Prsnt : 11|1@0+ (1,0) [0|1] "" CSM
 SG_ ASS_DSPMd2Prsnt : 12|1@0+ (1,0) [0|1] "" CSM
 SG_ ASS_MtxSnkMutStat : 13|1@0+ (1,0) [0|1] "" CSM
 SG_ ASS_DSPMd6Prsnt : 14|1@0+ (1,0) [0|1] "" CSM
 SG_ ASS_DSPMd3Prsnt : 15|1@0+ (1,0) [0|1] "" CSM
 SG_ FrtPsngrMtxSnkMutSts : 24|1@0+ (1,0) [0|1] "" CSM
 SG_ CCSI_PV : 26|2@0+ (1,0) [0|3] "" IPC
 SG_ CCSI_ARC : 28|2@0+ (1,0) [0|3] "" IPC
 SG_ CCSI_CrtclChmPrdcrSOH : 30|2@0+ (1,0) [0|2] "" IPC
 SG_ RRMtxSnkMutSts : 38|1@0+ (1,0) [0|1] "" CSM
 SG_ LRMtxSnkMutSts : 39|1@0+ (1,0) [0|1] "" CSM

BO_ 1380 AMP_CAN5_PDU02: 6 AMP
 SG_ DirAudPrmtRndrngActv : 4|1@0+ (1,0) [0|1] "" CSM
 SG_ HMIInCarVcCommSts : 7|3@0+ (1,0) [0|7] "" CSM

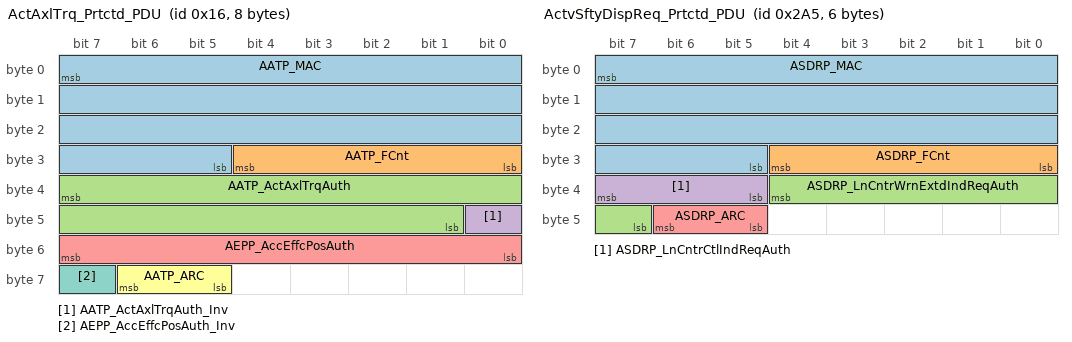
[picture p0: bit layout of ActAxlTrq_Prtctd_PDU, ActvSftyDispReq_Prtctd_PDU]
BO_ 22 ActAxlTrq_Prtctd_PDU: 8 CGM
 SG_ AATP_MAC : 7|27@0+ (1,0) [0|1.34218e+008] "" Vector__XXX
 SG_ AATP_FCnt : 28|5@0+ (1,0) [0|31] "" Vector__XXX
 SG_ AATP_ActAxlTrqAuth : 39|15@0+ (2,-22534) [-22534|43000] "Nm" AMP,CSM
 SG_ AATP_ActAxlTrqAuth_Inv : 40|1@0+ (1,0) [0|1] "" AMP,CSM
 SG_ AEPP_AccEffcPosAuth : 55|8@0+ (0.392157,0) [0|100] "%" Vector__XXX
 SG_ AATP_ARC : 62|2@0+ (1,0) [0|3] "" Vector__XXX
 SG_ AEPP_AccEffcPosAuth_Inv : 63|1@0+ (1,0) [0|1] "" Vector__XXX

BO_ 1384 ActvSftyDispReq_PCSM_PDU: 8 CGM
 SG_ ActvSftyDispReq_PCSM : 0|64@1+ (1,0) [0|1.84467e+019] "" IPC

BO_ 677 ActvSftyDispReq_Prtctd_PDU: 6 CGM
 SG_ ASDRP_MAC : 7|27@0+ (1,0) [0|1.34218e+008] "" IPC
 SG_ ASDRP_FCnt : 28|5@0+ (1,0) [0|31] "" IPC
 SG_ ASDRP_LnCntrWrnExtdIndReqAuth : 36|6@0+ (1,0) [0|43] "" IPC,TCP
 SG_ ASDRP_LnCntrCtlIndReqAuth : 39|3@0+ (1,0) [0|5] "" IPC
 SG_ ASDRP_ARC : 46|2@0+ (1,0) [0|3] "" IPC

BO_ 1355 ActvSftyOprtrCrtclNtfns_PCSM_PDU: 8 CGM
 SG_ ActvSftyOprtrCrtclNtfns_PCSM : 0|64@1+ (1,0) [0|1.84467e+019] "" IPC

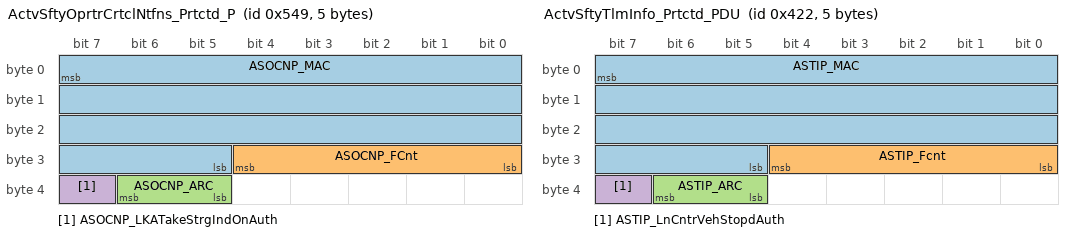
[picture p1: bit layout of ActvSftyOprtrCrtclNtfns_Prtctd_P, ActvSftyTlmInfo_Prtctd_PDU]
BO_ 1353 ActvSftyOprtrCrtclNtfns_Prtctd_P: 5 CGM
 SG_ ASOCNP_MAC : 7|27@0+ (1,0) [0|1.34218e+008] "" IPC
 SG_ ASOCNP_FCnt : 28|5@0+ (1,0) [0|31] "" IPC
 SG_ ASOCNP_ARC : 38|2@0+ (1,0) [0|3] "" IPC
 SG_ ASOCNP_LKATakeStrgIndOnAuth : 39|1@0+ (1,0) [0|1] "" IPC

BO_ 1062 ActvSftyTlmInfo_PCSM_PDU: 8 CGM
 SG_ ActvSftyTlmInfo_PCSM : 0|64@1+ (1,0) [0|1.84467e+019] "" TCP

BO_ 1058 ActvSftyTlmInfo_Prtctd_PDU: 5 CGM
 SG_ ASTIP_MAC : 7|27@0+ (1,0) [0|1.34218e+008] "" TCP
 SG_ ASTIP_Fcnt : 28|5@0+ (1,0) [0|31] "" TCP
 SG_ ASTIP_ARC : 38|2@0+ (1,0) [0|3] "" TCP
 SG_ ASTIP_LnCntrVehStopdAuth : 39|1@0+ (1,0) [0|1] "" TCP

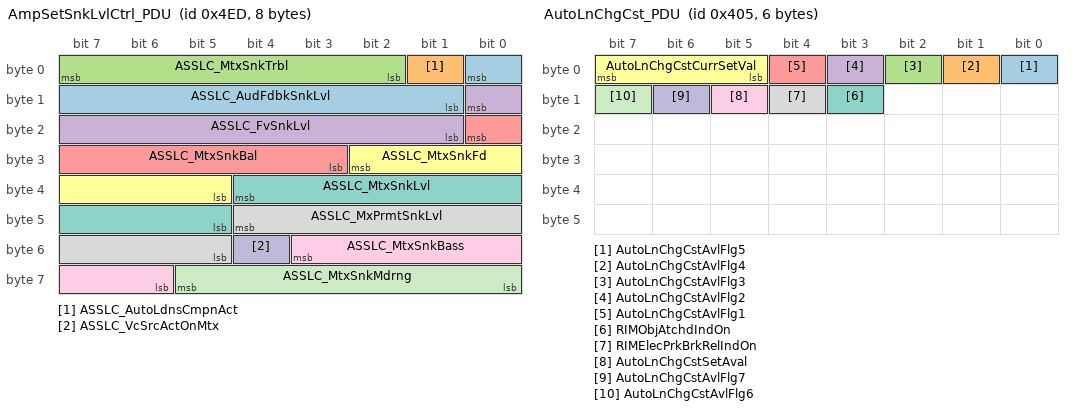
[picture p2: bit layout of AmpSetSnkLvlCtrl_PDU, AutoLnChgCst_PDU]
BO_ 1261 AmpSetSnkLvlCtrl_PDU: 8 CSM
 SG_ ASSLC_AudFdbkSnkLvl : 0|8@0+ (0.5,-127.5) [-127.5|0] "dB" AMP
 SG_ ASSLC_AutoLdnsCmpnAct : 1|1@0+ (1,0) [0|1] "" AMP
 SG_ ASSLC_MtxSnkTrbl : 7|6@0- (1,0) [-32|31] "" AMP
 SG_ ASSLC_FvSnkLvl : 8|8@0+ (0.5,-127.5) [-127.5|0] "dB" AMP
 SG_ ASSLC_MtxSnkBal : 16|6@0- (1,0) [-32|31] "" AMP
 SG_ ASSLC_MtxSnkFd : 26|6@0- (1,0) [-32|31] "" AMP
 SG_ ASSLC_MtxSnkLvl : 36|8@0+ (0.5,-127.5) [-127.5|0] "dB" AMP
 SG_ ASSLC_MxPrmtSnkLvl : 44|8@0+ (0.5,-127.5) [-127.5|0] "dB" AMP
 SG_ ASSLC_MtxSnkBass : 51|6@0- (1,0) [-32|31] "" AMP
 SG_ ASSLC_VcSrcActOnMtx : 52|1@0+ (1,0) [0|1] "" AMP
 SG_ ASSLC_MtxSnkMdrng : 61|6@0- (1,0) [-32|31] "" AMP

BO_ 1029 AutoLnChgCst_PDU: 6 CGM
 SG_ AutoLnChgCstAvlFlg5 : 0|1@0+ (1,0) [0|1] "" CSM
 SG_ AutoLnChgCstAvlFlg4 : 1|1@0+ (1,0) [0|1] "" CSM
 SG_ AutoLnChgCstAvlFlg3 : 2|1@0+ (1,0) [0|1] "" CSM
 SG_ AutoLnChgCstAvlFlg2 : 3|1@0+ (1,0) [0|1] "" CSM
 SG_ AutoLnChgCstAvlFlg1 : 4|1@0+ (1,0) [0|1] "" CSM
 SG_ AutoLnChgCstCurrSetVal : 7|3@0+ (1,0) [0|4] "" CSM
 SG_ RIMObjAtchdIndOn : 11|1@0+ (1,0) [0|1] "" IPC
 SG_ RIMElecPrkBrkRelIndOn : 12|1@0+ (1,0) [0|1] "" IPC
 SG_ AutoLnChgCstSetAval : 13|1@0+ (1,0) [0|1] "" CSM
 SG_ AutoLnChgCstAvlFlg7 : 14|1@0+ (1,0) [0|1] "" CSM
 SG_ AutoLnChgCstAvlFlg6 : 15|1@0+ (1,0) [0|1] "" CSM

BO_ 1038 BdyGenInfo1_PCSM_PDU: 8 CGM
 SG_ BdyGenInfo1_PCSM : 0|64@1+ (1,0) [0|1.84467e+019] "" IPC

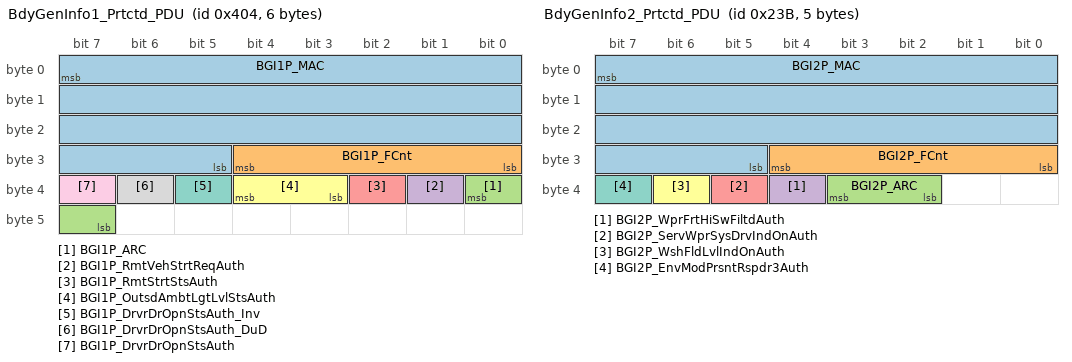
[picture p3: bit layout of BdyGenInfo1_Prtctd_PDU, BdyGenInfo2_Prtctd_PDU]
BO_ 1028 BdyGenInfo1_Prtctd_PDU: 6 CGM
 SG_ BGI1P_MAC : 7|27@0+ (1,0) [0|1.34218e+008] "" IPC
 SG_ BGI1P_FCnt : 28|5@0+ (1,0) [0|31] "" IPC
 SG_ BGI1P_ARC : 32|2@0+ (1,0) [0|3] "" IPC
 SG_ BGI1P_RmtVehStrtReqAuth : 33|1@0+ (1,0) [0|1] "" CSM,IPC
 SG_ BGI1P_RmtStrtStsAuth : 34|1@0+ (1,0) [0|1] "" CSM,IPC,RadioLow,TCP,VKM
 SG_ BGI1P_OutsdAmbtLgtLvlStsAuth : 36|2@0+ (1,0) [0|2] "" CSM,IPC
 SG_ BGI1P_DrvrDrOpnStsAuth_Inv : 37|1@0+ (1,0) [0|1] "" CSM,IPC,TCP
 SG_ BGI1P_DrvrDrOpnStsAuth_DuD : 38|1@0+ (1,0) [0|1] "" CSM,IPC
 SG_ BGI1P_DrvrDrOpnStsAuth : 39|1@0+ (1,0) [0|1] "" CSM,IPC,TCP

BO_ 572 BdyGenInfo2_PCSM_PDU: 8 CGM
 SG_ BdyGenInfo2_PCSM : 0|64@1+ (1,0) [0|1.84467e+019] "" IPC

BO_ 571 BdyGenInfo2_Prtctd_PDU: 5 CGM
 SG_ BGI2P_MAC : 7|27@0+ (1,0) [0|1.34218e+008] "" IPC
 SG_ BGI2P_FCnt : 28|5@0+ (1,0) [0|31] "" IPC
 SG_ BGI2P_ARC : 35|2@0+ (1,0) [0|3] "" IPC
 SG_ BGI2P_WprFrtHiSwFiltdAuth : 36|1@0+ (1,0) [0|1] "" IPC
 SG_ BGI2P_ServWprSysDrvIndOnAuth : 37|1@0+ (1,0) [0|1] "" IPC
 SG_ BGI2P_WshFldLvlIndOnAuth : 38|1@0+ (1,0) [0|1] "" CSM,IPC,TCP
 SG_ BGI2P_EnvModPrsntRspdr3Auth : 39|1@0+ (1,0) [0|1] "" IPC

BO_ 526 BkupSysPwrMode_PCSM_PDU: 8 CGM
 SG_ BkupSysPwrMode_PCSM : 0|64@1+ (1,0) [0|1.84467e+019] "" IPC,RSC,TCP,VKM

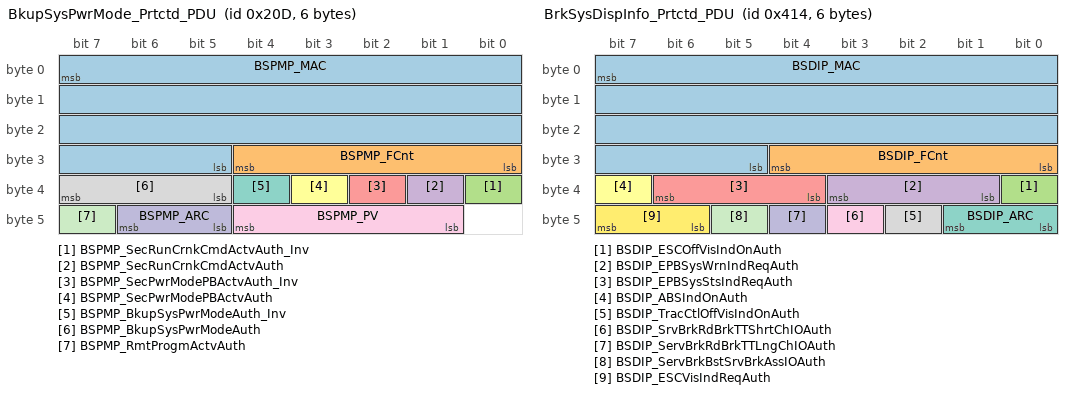
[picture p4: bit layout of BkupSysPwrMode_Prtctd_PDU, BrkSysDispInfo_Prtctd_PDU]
BO_ 525 BkupSysPwrMode_Prtctd_PDU: 6 CGM
 SG_ BSPMP_MAC : 7|27@0+ (1,0) [0|1.34218e+008] "" IPC,RSC,TCP,VKM
 SG_ BSPMP_FCnt : 28|5@0+ (1,0) [0|31] "" IPC,RSC,TCP,VKM
 SG_ BSPMP_SecRunCrnkCmdActvAuth_Inv : 32|1@0+ (1,0) [0|1] "" IPC,RSC,TCP,VKM
 SG_ BSPMP_SecRunCrnkCmdActvAuth : 33|1@0+ (1,0) [0|1] "" IPC,RSC,TCP,VKM
 SG_ BSPMP_SecPwrModePBActvAuth_Inv : 34|1@0+ (1,0) [0|1] "" IPC,RSC,TCP,VKM
 SG_ BSPMP_SecPwrModePBActvAuth : 35|1@0+ (1,0) [0|1] "" IPC,RSC,TCP,VKM
 SG_ BSPMP_BkupSysPwrModeAuth_Inv : 36|1@0+ (1,0) [0|1] "" AGC,AMP,CSM,HUD_CAN,HVAC_FP_F,HVAC_FP_R,ICS_Info,IPC,PDR,MFC,RSC,RadioLow,TCP,VKM,WCM
 SG_ BSPMP_BkupSysPwrModeAuth : 39|3@0+ (1,0) [0|4] "" AGC,AMP,CSM,HUD_CAN,HVAC_FP_F,HVAC_FP_R,ICS_Info,IPC,PDR,MFC,RSC,RadioLow,TCP,VKM,WCM
 SG_ BSPMP_PV : 44|4@0+ (1,0) [0|15] "" AGC,HUD_CAN,HVAC_FP_R,IPC,RSC,TCP,VKM
 SG_ BSPMP_ARC : 46|2@0+ (1,0) [0|3] "" AGC,HUD_CAN,HVAC_FP_R,IPC,RSC,TCP,VKM
 SG_ BSPMP_RmtProgmActvAuth : 47|1@0+ (1,0) [0|1] "" AGC,AMP,CSM,HUD_CAN,HVAC_FP_F,HVAC_FP_R,ICS_Info,IPC,PDR,MFC,RSC,RadioLow,TCP,VKM,WCM

BO_ 1800 BrkSysDispInfo_PCSM_PDU: 8 CGM
 SG_ BrkSysDispInfo_PCSM : 0|64@1+ (1,0) [0|1.84467e+019] "" IPC

BO_ 1044 BrkSysDispInfo_Prtctd_PDU: 6 CGM
 SG_ BSDIP_MAC : 7|27@0+ (1,0) [0|1.34218e+008] "" IPC
 SG_ BSDIP_FCnt : 28|5@0+ (1,0) [0|31] "" IPC
 SG_ BSDIP_ESCOffVisIndOnAuth : 32|1@0+ (1,0) [0|1] "" IPC
 SG_ BSDIP_EPBSysWrnIndReqAuth : 35|3@0+ (1,0) [0|5] "" CSM,IPC
 SG_ BSDIP_EPBSysStsIndReqAuth : 38|3@0+ (1,0) [0|5] "" CSM,IPC
 SG_ BSDIP_ABSIndOnAuth : 39|1@0+ (1,0) [0|1] "" CSM,IPC,TCP
 SG_ BSDIP_ARC : 41|2@0+ (1,0) [0|3] "" IPC
 SG_ BSDIP_TracCtlOffVisIndOnAuth : 42|1@0+ (1,0) [0|1] "" IPC,TCP
 SG_ BSDIP_SrvBrkRdBrkTTShrtChIOAuth : 43|1@0+ (1,0) [0|1] "" IPC,TCP
 SG_ BSDIP_ServBrkRdBrkTTLngChIOAuth : 44|1@0+ (1,0) [0|1] "" IPC,TCP
 SG_ BSDIP_ServBrkBstSrvBrkAssIOAuth : 45|1@0+ (1,0) [0|1] "" IPC,TCP
 SG_ BSDIP_ESCVisIndReqAuth : 47|2@0+ (1,0) [0|2] "" IPC,TCP

BO_ 179 CGM_CAN5_PDU03: 6 CGM
 SG_ ClsnEvntDatRcrdgTrgrd : 7|1@0+ (1,0) [0|1] "" TCP

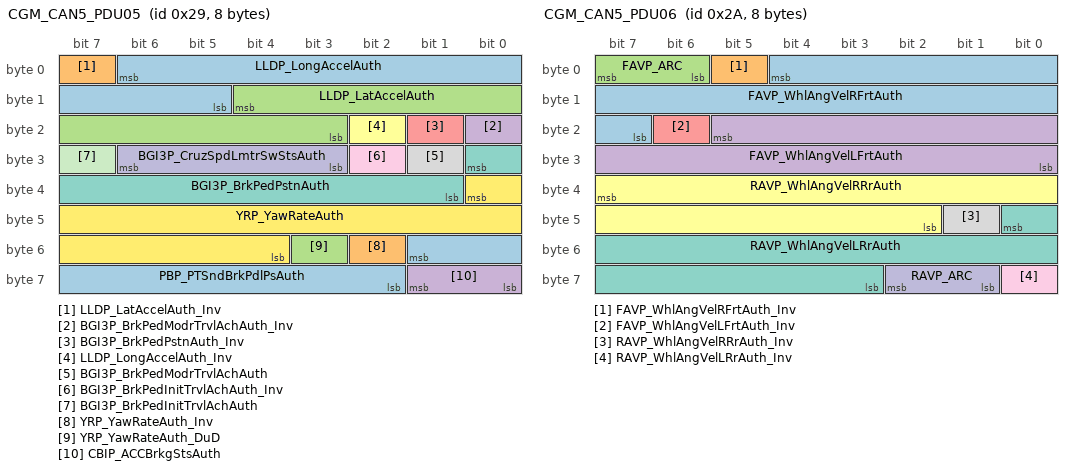
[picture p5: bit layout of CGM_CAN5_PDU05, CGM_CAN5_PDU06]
BO_ 41 CGM_CAN5_PDU05: 8 CGM
 SG_ LLDP_LongAccelAuth : 6|10@0- (0.0625,0) [-32|31.9375] "m/s^2" CSM,IPC,PDR,TCP
 SG_ LLDP_LatAccelAuth_Inv : 7|1@0+ (1,0) [0|1] "" CSM,IPC,PDR
 SG_ LLDP_LatAccelAuth : 12|10@0- (0.0625,0) [-32|31.9375] "m/s^2" CSM,IPC,PDR,TCP
 SG_ BGI3P_BrkPedModrTrvlAchAuth_Inv : 16|1@0+ (1,0) [0|1] "" CSM
 SG_ BGI3P_BrkPedPstnAuth_Inv : 17|1@0+ (1,0) [0|1] "" CSM,PDR
 SG_ LLDP_LongAccelAuth_Inv : 18|1@0+ (1,0) [0|1] "" CSM,IPC,PDR
 SG_ BGI3P_BrkPedPstnAuth : 24|8@0+ (0.392157,0) [0|100] "%" CSM,PDR
 SG_ BGI3P_BrkPedModrTrvlAchAuth : 25|1@0+ (1,0) [0|1] "" CSM
 SG_ BGI3P_BrkPedInitTrvlAchAuth_Inv : 26|1@0+ (1,0) [0|1] "" CSM
 SG_ BGI3P_CruzSpdLmtrSwStsAuth : 30|4@0+ (1,0) [0|9] "" CSM
 SG_ BGI3P_BrkPedInitTrvlAchAuth : 31|1@0+ (1,0) [0|1] "" CSM
 SG_ YRP_YawRateAuth : 32|13@0- (0.024,0) [-98.304|98.28] "Deg/Sec" CSM,IPC,PDR,TCP
 SG_ PBP_PTSndBrkPdlPsAuth : 49|8@0+ (0.392157,0) [0|100] "%" TCP
 SG_ YRP_YawRateAuth_Inv : 50|1@0+ (1,0) [0|1] "" CSM,IPC,PDR,TCP
 SG_ YRP_YawRateAuth_DuD : 51|1@0+ (1,0) [0|1] "" CSM,TCP
 SG_ CBIP_ACCBrkgStsAuth : 57|2@0+ (1,0) [0|2] "" TCP

BO_ 42 CGM_CAN5_PDU06: 8 CGM
 SG_ FAVP_WhlAngVelRFrtAuth : 4|14@0+ (0.004,0) [0|65.532] "Revolutions Per Second" CSM,PDR,TCP
 SG_ FAVP_WhlAngVelRFrtAuth_Inv : 5|1@0+ (1,0) [0|1] "" CSM,PDR,TCP
 SG_ FAVP_ARC : 7|2@0+ (1,0) [0|3] "" CSM,TCP
 SG_ FAVP_WhlAngVelLFrtAuth : 21|14@0+ (0.004,0) [0|65.532] "Revolutions Per Second" CSM,PDR,TCP
 SG_ FAVP_WhlAngVelLFrtAuth_Inv : 22|1@0+ (1,0) [0|1] "" CSM,PDR,TCP
 SG_ RAVP_WhlAngVelRRrAuth : 39|14@0+ (0.004,0) [0|65.532] "Revolutions Per Second" CSM,PDR,TCP
 SG_ RAVP_WhlAngVelLRrAuth : 40|14@0+ (0.004,0) [0|65.532] "Revolutions Per Second" CSM,PDR,TCP
 SG_ RAVP_WhlAngVelRRrAuth_Inv : 41|1@0+ (1,0) [0|1] "" CSM,PDR,TCP
 SG_ RAVP_WhlAngVelLRrAuth_Inv : 56|1@0+ (1,0) [0|1] "" CSM,PDR,TCP
 SG_ RAVP_ARC : 58|2@0+ (1,0) [0|3] "" CSM,TCP

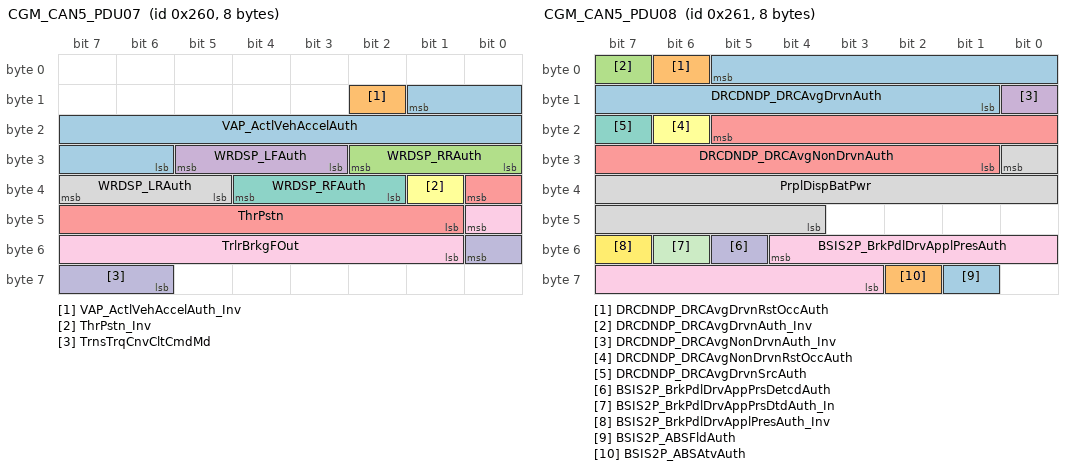
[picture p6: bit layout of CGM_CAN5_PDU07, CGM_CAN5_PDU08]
BO_ 608 CGM_CAN5_PDU07: 8 CGM
 SG_ VAP_ActlVehAccelAuth : 9|12@0- (0.01,0) [-20.48|20.47] "m/s^2" IPC,TCP
 SG_ VAP_ActlVehAccelAuth_Inv : 10|1@0+ (1,0) [0|1] "" IPC,TCP
 SG_ WRDSP_RRAuth : 26|3@0+ (1,0) [0|4] "" CSM,PDR,TCP
 SG_ WRDSP_LFAuth : 29|3@0+ (1,0) [0|4] "" CSM,PDR,TCP
 SG_ ThrPstn : 32|8@0+ (0.392157,0) [0|100] "%" CSM,TCP
 SG_ ThrPstn_Inv : 33|1@0+ (1,0) [0|1] "" CSM
 SG_ WRDSP_RFAuth : 36|3@0+ (1,0) [0|4] "" CSM,PDR,TCP
 SG_ WRDSP_LRAuth : 39|3@0+ (1,0) [0|4] "" CSM,PDR,TCP
 SG_ TrlrBrkgFOut : 40|8@0+ (0.392157,0) [0|100] "%" CSM,IPC
 SG_ TrnsTrqCnvCltCmdMd : 48|3@0+ (1,0) [0|4] "" AMP

BO_ 609 CGM_CAN5_PDU08: 8 CGM
 SG_ DRCDNDP_DRCAvgDrvnAuth : 5|13@0+ (0.125,0) [0|1023.88] "m" CSM,IPC,TCP
 SG_ DRCDNDP_DRCAvgDrvnRstOccAuth : 6|1@0+ (1,0) [0|1] "" CSM,IPC,TCP
 SG_ DRCDNDP_DRCAvgDrvnAuth_Inv : 7|1@0+ (1,0) [0|1] "" CSM,IPC,TCP
 SG_ DRCDNDP_DRCAvgNonDrvnAuth_Inv : 8|1@0+ (1,0) [0|1] "" CSM,IPC,TCP
 SG_ DRCDNDP_DRCAvgNonDrvnAuth : 21|13@0+ (0.125,0) [0|1023.88] "m" CSM,IPC,TCP
 SG_ DRCDNDP_DRCAvgNonDrvnRstOccAuth : 22|1@0+ (1,0) [0|1] "" CSM,IPC,TCP
 SG_ DRCDNDP_DRCAvgDrvnSrcAuth : 23|1@0+ (1,0) [0|1] "" CSM,TCP
 SG_ PrplDispBatPwr : 24|13@0+ (0.5,-325) [-325|3770.5] "" CSM,PDR
 SG_ BSIS2P_BrkPdlDrvApplPresAuth : 52|10@0+ (20,0) [0|20460] "kPa" CSM,PDR
 SG_ BSIS2P_BrkPdlDrvAppPrsDetcdAuth : 53|1@0+ (1,0) [0|1] "" CSM,TCP
 SG_ BSIS2P_BrkPdlDrvAppPrsDtdAuth_In : 54|1@0+ (1,0) [0|1] "" CSM
 SG_ BSIS2P_BrkPdlDrvApplPresAuth_Inv : 55|1@0+ (1,0) [0|1] "" CSM,PDR
 SG_ BSIS2P_ABSFldAuth : 57|1@0+ (1,0) [0|1] "" CSM
 SG_ BSIS2P_ABSAtvAuth : 58|1@0+ (1,0) [0|1] "" CSM,PDR,RadioLow

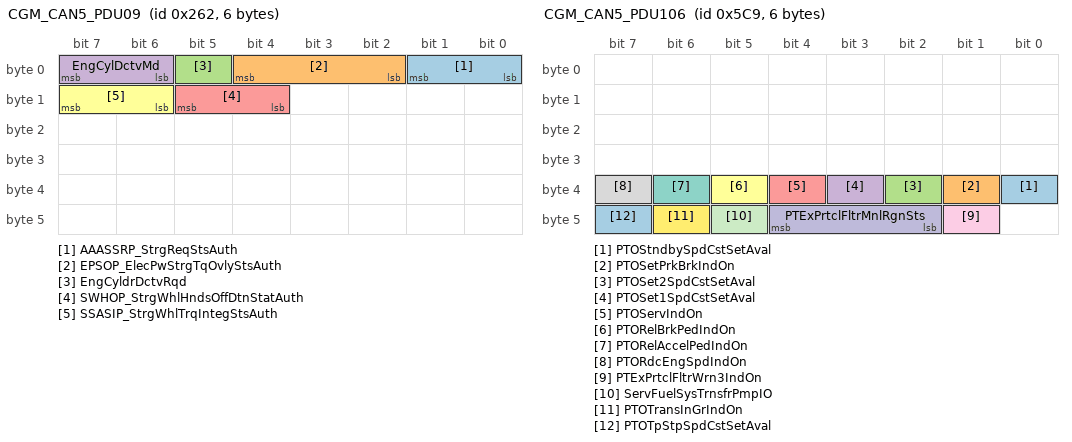
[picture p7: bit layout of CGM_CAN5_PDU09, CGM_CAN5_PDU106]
BO_ 610 CGM_CAN5_PDU09: 6 CGM
 SG_ AAASSRP_StrgReqStsAuth : 1|2@0+ (1,0) [0|2] "" TCP
 SG_ EPSOP_ElecPwStrgTqOvlyStsAuth : 4|3@0+ (1,0) [0|5] "" TCP
 SG_ EngCyldrDctvRqd : 5|1@0+ (1,0) [0|1] "" AMP,RadioLow
 SG_ EngCylDctvMd : 7|2@0+ (1,0) [0|3] "" AMP,CSM,IPC,RadioLow
 SG_ SWHOP_StrgWhlHndsOffDtnStatAuth : 13|2@0+ (1,0) [0|2] "" TCP
 SG_ SSASIP_StrgWhlTrqIntegStsAuth : 15|2@0+ (1,0) [0|3] "" TCP

BO_ 1475 CGM_CAN5_PDU103: 8 CGM
 SG_ PTOAccelUpnBrkRelIndOn : 56|1@0+ (1,0) [0|1] "" IPC
 SG_ PTOEngRunTmrCstCurrSetVal : 60|4@0+ (1,0) [0|15] "" CSM,RadioLow

BO_ 1481 CGM_CAN5_PDU106: 6 CGM
 SG_ PTOStndbySpdCstSetAval : 32|1@0+ (1,0) [0|1] "" CSM,RadioLow
 SG_ PTOSetPrkBrkIndOn : 33|1@0+ (1,0) [0|1] "" IPC
 SG_ PTOSet2SpdCstSetAval : 34|1@0+ (1,0) [0|1] "" CSM,RadioLow
 SG_ PTOSet1SpdCstSetAval : 35|1@0+ (1,0) [0|1] "" CSM,RadioLow
 SG_ PTOServIndOn : 36|1@0+ (1,0) [0|1] "" IPC
 SG_ PTORelBrkPedIndOn : 37|1@0+ (1,0) [0|1] "" IPC
 SG_ PTORelAccelPedIndOn : 38|1@0+ (1,0) [0|1] "" IPC
 SG_ PTORdcEngSpdIndOn : 39|1@0+ (1,0) [0|1] "" IPC
 SG_ PTExPrtclFltrWrn3IndOn : 41|1@0+ (1,0) [0|1] "" IPC
 SG_ PTExPrtclFltrMnlRgnSts : 44|3@0+ (1,0) [0|7] "" IPC
 SG_ ServFuelSysTrnsfrPmpIO : 45|1@0+ (1,0) [0|1] "" IPC
 SG_ PTOTransInGrIndOn : 46|1@0+ (1,0) [0|1] "" IPC
 SG_ PTOTpStpSpdCstSetAval : 47|1@0+ (1,0) [0|1] "" CSM,RadioLow

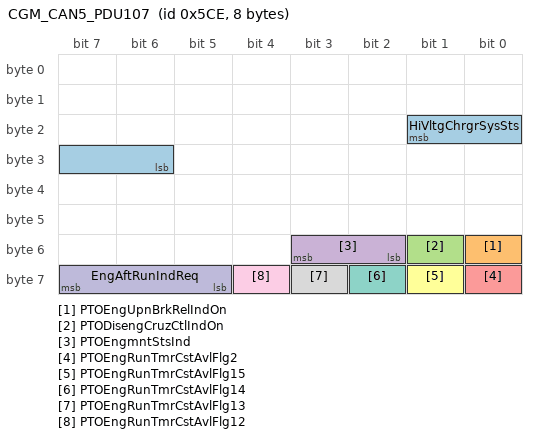
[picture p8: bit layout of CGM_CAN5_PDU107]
BO_ 1486 CGM_CAN5_PDU107: 8 CGM
 SG_ HiVltgChrgrSysSts : 17|4@0+ (1,0) [0|10] "" IPC
 SG_ PTOEngUpnBrkRelIndOn : 48|1@0+ (1,0) [0|1] "" IPC
 SG_ PTODisengCruzCtlIndOn : 49|1@0+ (1,0) [0|1] "" IPC
 SG_ PTOEngmntStsInd : 51|2@0+ (1,0) [0|3] "" IPC
 SG_ PTOEngRunTmrCstAvlFlg2 : 56|1@0+ (1,0) [0|1] "" CSM,RadioLow
 SG_ PTOEngRunTmrCstAvlFlg15 : 57|1@0+ (1,0) [0|1] "" CSM,RadioLow
 SG_ PTOEngRunTmrCstAvlFlg14 : 58|1@0+ (1,0) [0|1] "" CSM,RadioLow
 SG_ PTOEngRunTmrCstAvlFlg13 : 59|1@0+ (1,0) [0|1] "" CSM,RadioLow
 SG_ PTOEngRunTmrCstAvlFlg12 : 60|1@0+ (1,0) [0|1] "" CSM,RadioLow
 SG_ EngAftRunIndReq : 63|3@0+ (1,0) [0|4] "" IPC

BA_DEF_ SG_  "SignalType" STRING ;
BA_DEF_ SG_  "SignalLongName" STRING ;
BA_DEF_ BO_  "GenMsgCycleTime" INT 0 10000;
BA_DEF_ BO_  "GenMsgSendType" ENUM "cyclicX","spontanX","cyclicIfActiveX","spontanWithDelay","cyclicAndSpontanX","cyclicAndSpontanWithDelay","spontanWithRepetition","cyclicIfActiveAndSpontanWD";
BA_DEF_DEF_  "SignalType" "";
BA_DEF_DEF_  "SignalLongName" "";
BA_DEF_DEF_  "GenMsgCycleTime" 0;
BA_DEF_DEF_  "GenMsgSendType" "cyclicX";
BA_ "GenMsgCycleTime" BO_ 1110 1000;
BA_ "GenMsgCycleTime" BO_ 1380 1000;
BA_ "GenMsgCycleTime" BO_ 22 12.5;
BA_ "GenMsgCycleTime" BO_ 677 250;
BA_ "GenMsgCycleTime" BO_ 1355 3500;
BA_ "GenMsgCycleTime" BO_ 1353 1000;
BA_ "GenMsgCycleTime" BO_ 1062 3500;
BA_ "GenMsgCycleTime" BO_ 1058 1000;
BA_ "GenMsgCycleTime" BO_ 1261 1000;
BA_ "GenMsgCycleTime" BO_ 1029 1000;
BA_ "GenMsgCycleTime" BO_ 1028 100;
BA_ "GenMsgCycleTime" BO_ 571 100;
BA_ "GenMsgCycleTime" BO_ 525 250;
BA_ "GenMsgCycleTime" BO_ 1800 3500;
BA_ "GenMsgCycleTime" BO_ 1044 1000;
BA_ "GenMsgCycleTime" BO_ 41 10;
BA_ "GenMsgCycleTime" BO_ 42 10;
BA_ "GenMsgCycleTime" BO_ 608 100;
BA_ "GenMsgCycleTime" BO_ 609 100;
BA_ "GenMsgCycleTime" BO_ 610 100;
BA_ "GenMsgCycleTime" BO_ 1475 1000;
BA_ "GenMsgCycleTime" BO_ 1481 1000;
BA_ "GenMsgCycleTime" BO_ 1486 1000;
BA_ "SignalType" SG_ 1110 ASS_PhLckdLpLckd "ENM";
BA_ "SignalLongName" SG_ 1110 ASS_PhLckdLpLckd "Amplifier Sink State : Phase Locked Loop Locked";
BA_ "SignalType" SG_ 1110 ASS_DSPMd7Prsnt "ENM";
BA_ "SignalLongName" SG_ 1110 ASS_DSPMd7Prsnt "Amplifier Sink State : DSP Mode 7 Present";
BA_ "SignalType" SG_ 1110 ASS_DSPMd0Prsnt "ENM";
BA_ "SignalLongName" SG_ 1110 ASS_DSPMd0Prsnt "Amplifier Sink State : DSP Mode 0 Present";
BA_ "SignalType" SG_ 1110 ASS_DSPMd5Prsnt "ENM";
BA_ "SignalLongName" SG_ 1110 ASS_DSPMd5Prsnt "Amplifier Sink State : DSP Mode 5 Present";
BA_ "SignalType" SG_ 1110 ASS_VehNoisCmpnAvail "ENM";
BA_ "SignalLongName" SG_ 1110 ASS_VehNoisCmpnAvail "Amplifier Sink State : Vehicle Noise Compensation Available";
BA_ "SignalType" SG_ 1110 ASS_DSPAvail "ENM";
BA_ "SignalLongName" SG_ 1110 ASS_DSPAvail "Amplifier Sink State : DSP Available";
BA_ "SignalType" SG_ 1110 ASS_DSPMd1Prsnt "ENM";
BA_ "SignalLongName" SG_ 1110 ASS_DSPMd1Prsnt "Amplifier Sink State : DSP Mode 1 Present";
BA_ "SignalType" SG_ 1110 ASS_SurndAvail "ENM";
BA_ "SignalLongName" SG_ 1110 ASS_SurndAvail "Amplifier Sink State : Suround Available";
BA_ "SignalLongName" SG_ 1110 CrtclChmPrdcrStat "Critical Chime Producer Status";
BA_ "SignalType" SG_ 1110 ASS_DSPMd4Prsnt "ENM";
BA_ "SignalLongName" SG_ 1110 ASS_DSPMd4Prsnt "Amplifier Sink State : DSP Mode 4 Present";
BA_ "SignalType" SG_ 1110 ASS_DSPMd2Prsnt "ENM";
BA_ "SignalLongName" SG_ 1110 ASS_DSPMd2Prsnt "Amplifier Sink State : DSP Mode 2 Present";
BA_ "SignalType" SG_ 1110 ASS_MtxSnkMutStat "ENM";
BA_ "SignalLongName" SG_ 1110 ASS_MtxSnkMutStat "Amplifier Sink State : Mutex Sink Mute State";
BA_ "SignalType" SG_ 1110 ASS_DSPMd6Prsnt "ENM";
BA_ "SignalLongName" SG_ 1110 ASS_DSPMd6Prsnt "Amplifier Sink State : DSP Mode 6 Present";
BA_ "SignalType" SG_ 1110 ASS_DSPMd3Prsnt "ENM";
BA_ "SignalLongName" SG_ 1110 ASS_DSPMd3Prsnt "Amplifier Sink State : DSP Mode 3 Present";
BA_ "SignalType" SG_ 1110 FrtPsngrMtxSnkMutSts "ENM";
BA_ "SignalLongName" SG_ 1110 FrtPsngrMtxSnkMutSts "Front Passenger Mutex Sink Mute Status";
BA_ "SignalLongName" SG_ 1110 CCSI_PV "Critical Chime Status Information : Protection Value";
BA_ "SignalLongName" SG_ 1110 CCSI_ARC "Critical Chime Status Information : Alive Rolling Count";
BA_ "SignalType" SG_ 1110 CCSI_CrtclChmPrdcrSOH "ENM";
BA_ "SignalLongName" SG_ 1110 CCSI_CrtclChmPrdcrSOH "Critical Chime Status Information : Critical Chime Producer State of Health";
BA_ "SignalType" SG_ 1110 RRMtxSnkMutSts "ENM";
BA_ "SignalLongName" SG_ 1110 RRMtxSnkMutSts "Right Rear Mutex Sink Mute Status";
BA_ "SignalType" SG_ 1110 LRMtxSnkMutSts "ENM";
BA_ "SignalLongName" SG_ 1110 LRMtxSnkMutSts "Left Rear Mutex Sink Mute Status";
BA_ "SignalType" SG_ 1380 DirAudPrmtRndrngActv "ENM";
BA_ "SignalLongName" SG_ 1380 DirAudPrmtRndrngActv "Directional Audio Prompt Rendering Active";
BA_ "SignalType" SG_ 1380 HMIInCarVcCommSts "ENM";
BA_ "SignalLongName" SG_ 1380 HMIInCarVcCommSts "HMI In Car Voice Communication Status";
BA_ "SignalLongName" SG_ 22 AATP_MAC "Actual Axle Torque Protected : MAC";
BA_ "SignalLongName" SG_ 22 AATP_FCnt "Actual Axle Torque Protected : Freshness Counter";
BA_ "SignalLongName" SG_ 22 AATP_ActAxlTrqAuth "Actual Axle Torque Protected : Actual Axle Torque Authenticated";
BA_ "SignalType" SG_ 22 AATP_ActAxlTrqAuth_Inv "ENM";
BA_ "SignalLongName" SG_ 22 AATP_ActAxlTrqAuth_Inv "Actual Axle Torque Protected : Actual Axle Torque Authenticated Invalid";
BA_ "SignalLongName" SG_ 22 AEPP_AccEffcPosAuth "Actual Axle Torque Protected : Accelerator Effective Position Authenticated";
BA_ "SignalLongName" SG_ 22 AATP_ARC "Actual Axle Torque Protected : Alive Rolling Count";
BA_ "SignalType" SG_ 22 AEPP_AccEffcPosAuth_Inv "ENM";
BA_ "SignalLongName" SG_ 22 AEPP_AccEffcPosAuth_Inv "Actual Axle Torque Protected : Accelerator Effective Position Authenticated Invalid";
BA_ "SignalLongName" SG_ 1384 ActvSftyDispReq_PCSM "Active Safety Display Request Protected Counter Sync Message";
BA_ "SignalLongName" SG_ 677 ASDRP_MAC "Active Safety Display Request Protected : MAC";
BA_ "SignalLongName" SG_ 677 ASDRP_FCnt "Active Safety Display Request Protected : Freshness Counter";
BA_ "SignalType" SG_ 677 ASDRP_LnCntrWrnExtdIndReqAuth "ENM";
BA_ "SignalLongName" SG_ 677 ASDRP_LnCntrWrnExtdIndReqAuth "Active Safety Display Request Protected : Lane Centering Warning Extended Indication Request Authenticated";
BA_ "SignalType" SG_ 677 ASDRP_LnCntrCtlIndReqAuth "ENM";
BA_ "SignalLongName" SG_ 677 ASDRP_LnCntrCtlIndReqAuth "Active Safety Display Request Protected : Lane Centering Control Indication Request Authenticated";
BA_ "SignalLongName" SG_ 677 ASDRP_ARC "Active Safety Display Request Protected : Alive Rolling Count";
BA_ "SignalLongName" SG_ 1355 ActvSftyOprtrCrtclNtfns_PCSM "Active Safety Operator Critical Notifications Protected Counter Sync Message";
BA_ "SignalLongName" SG_ 1353 ASOCNP_MAC "Active Safety Operator Critical Notifications Protected : MAC";
BA_ "SignalLongName" SG_ 1353 ASOCNP_FCnt "Active Safety Operator Critical Notifications Protected : Freshness Counter";
BA_ "SignalLongName" SG_ 1353 ASOCNP_ARC "Active Safety Operator Critical Notifications Protected : Alive Rolling Count";
BA_ "SignalType" SG_ 1353 ASOCNP_LKATakeStrgIndOnAuth "ENM";
BA_ "SignalLongName" SG_ 1353 ASOCNP_LKATakeStrgIndOnAuth "Active Safety Operator Critical Notifications Protected : Lane Keep Assist Take Steering Indication On Authenticated";
BA_ "SignalLongName" SG_ 1062 ActvSftyTlmInfo_PCSM "Active Safety Telematics Information Protected Counter Sync Message";
BA_ "SignalLongName" SG_ 1058 ASTIP_MAC "Active Safety Telematics Information Protected : MAC";
BA_ "SignalLongName" SG_ 1058 ASTIP_Fcnt "Active Safety Telematics Information Protected : Freshness Counter";
BA_ "SignalLongName" SG_ 1058 ASTIP_ARC "Active Safety Telematics Information Protected : Alive Rolling Count";
BA_ "SignalType" SG_ 1058 ASTIP_LnCntrVehStopdAuth "ENM";
BA_ "SignalLongName" SG_ 1058 ASTIP_LnCntrVehStopdAuth "Active Safety Telematics Information Protected : Lane Centering Vehicle Stopped Authenticated";
BA_ "SignalLongName" SG_ 1261 ASSLC_AudFdbkSnkLvl "Amplifier Settings Sink Level Control : Audible Feedback Sink Level";
BA_ "SignalType" SG_ 1261 ASSLC_AutoLdnsCmpnAct "ENM";
BA_ "SignalLongName" SG_ 1261 ASSLC_AutoLdnsCmpnAct "Amplifier Settings Sink Level Control : Automatic Loudness Compensation Active";
BA_ "SignalLongName" SG_ 1261 ASSLC_MtxSnkTrbl "Amplifier Settings Sink Level Control : Mutex Sink Treble";
BA_ "SignalLongName" SG_ 1261 ASSLC_FvSnkLvl "Amplifier Settings Sink Level Control : Five Sink Level";
BA_ "SignalLongName" SG_ 1261 ASSLC_MtxSnkBal "Amplifier Settings Sink Level Control : Mutex Sink Balance";
BA_ "SignalLongName" SG_ 1261 ASSLC_MtxSnkFd "Amplifier Settings Sink Level Control : Mutex Sink Fade";
BA_ "SignalLongName" SG_ 1261 ASSLC_MtxSnkLvl "Amplifier Settings Sink Level Control : Mutex Sink Level";
BA_ "SignalLongName" SG_ 1261 ASSLC_MxPrmtSnkLvl "Amplifier Settings Sink Level Control : Mix Prompt Sink Level";
BA_ "SignalLongName" SG_ 1261 ASSLC_MtxSnkBass "Amplifier Settings Sink Level Control : Mutex Sink Bass";
BA_ "SignalType" SG_ 1261 ASSLC_VcSrcActOnMtx "ENM";
BA_ "SignalLongName" SG_ 1261 ASSLC_VcSrcActOnMtx "Amplifier Settings Sink Level Control : Voice Source Active On Mutex";
BA_ "SignalLongName" SG_ 1261 ASSLC_MtxSnkMdrng "Amplifier Settings Sink Level Control : Mutex Sink Midrange";
BA_ "SignalType" SG_ 1029 AutoLnChgCstAvlFlg5 "ENM";
BA_ "SignalLongName" SG_ 1029 AutoLnChgCstAvlFlg5 "Automatic Lane Change Customization Availability Flag 5";
BA_ "SignalType" SG_ 1029 AutoLnChgCstAvlFlg4 "ENM";
BA_ "SignalLongName" SG_ 1029 AutoLnChgCstAvlFlg4 "Automatic Lane Change Customization Availability Flag 4";
BA_ "SignalType" SG_ 1029 AutoLnChgCstAvlFlg3 "ENM";
BA_ "SignalLongName" SG_ 1029 AutoLnChgCstAvlFlg3 "Automatic Lane Change Customization Availability Flag 3";
BA_ "SignalType" SG_ 1029 AutoLnChgCstAvlFlg2 "ENM";
BA_ "SignalLongName" SG_ 1029 AutoLnChgCstAvlFlg2 "Automatic Lane Change Customization Availability Flag 2";
BA_ "SignalType" SG_ 1029 AutoLnChgCstAvlFlg1 "ENM";
BA_ "SignalLongName" SG_ 1029 AutoLnChgCstAvlFlg1 "Automatic Lane Change Customization Availability Flag 1";
BA_ "SignalType" SG_ 1029 AutoLnChgCstCurrSetVal "ENM";
BA_ "SignalLongName" SG_ 1029 AutoLnChgCstCurrSetVal "Automatic Lane Change Customization Current Setting Value";
BA_ "SignalType" SG_ 1029 RIMObjAtchdIndOn "ENM";
BA_ "SignalLongName" SG_ 1029 RIMObjAtchdIndOn "Rearward Impact Mitigation Object Attached Indication On";
BA_ "SignalType" SG_ 1029 RIMElecPrkBrkRelIndOn "ENM";
BA_ "SignalLongName" SG_ 1029 RIMElecPrkBrkRelIndOn "Rearward Impact Mitigation Electric Park Brake Release Indication On";
BA_ "SignalType" SG_ 1029 AutoLnChgCstSetAval "ENM";
BA_ "SignalLongName" SG_ 1029 AutoLnChgCstSetAval "Automatic Lane Change Customization Setting Available";
BA_ "SignalType" SG_ 1029 AutoLnChgCstAvlFlg7 "ENM";
BA_ "SignalLongName" SG_ 1029 AutoLnChgCstAvlFlg7 "Automatic Lane Change Customization Availability Flag 7";
BA_ "SignalType" SG_ 1029 AutoLnChgCstAvlFlg6 "ENM";
BA_ "SignalLongName" SG_ 1029 AutoLnChgCstAvlFlg6 "Automatic Lane Change Customization Availability Flag 6";
BA_ "SignalLongName" SG_ 1038 BdyGenInfo1_PCSM "Body General Information 1 Protected Counter Sync Message";
BA_ "SignalLongName" SG_ 1028 BGI1P_MAC "Body General Information 1 Protected : MAC";
BA_ "SignalLongName" SG_ 1028 BGI1P_FCnt "Body General Information 1 Protected : Freshness Counter";
BA_ "SignalLongName" SG_ 1028 BGI1P_ARC "Body General Information 1 Protected : Alive Rolling Count";
BA_ "SignalType" SG_ 1028 BGI1P_RmtVehStrtReqAuth "ENM";
BA_ "SignalLongName" SG_ 1028 BGI1P_RmtVehStrtReqAuth "Body General Information 1 Protected : Remote Vehicle Start Request Authenticated";
BA_ "SignalType" SG_ 1028 BGI1P_RmtStrtStsAuth "ENM";
BA_ "SignalLongName" SG_ 1028 BGI1P_RmtStrtStsAuth "Body General Information 1 Protected : Remote Start Status Authenticated";
BA_ "SignalType" SG_ 1028 BGI1P_OutsdAmbtLgtLvlStsAuth "ENM";
BA_ "SignalLongName" SG_ 1028 BGI1P_OutsdAmbtLgtLvlStsAuth "Body General Information 1 Protected : Outside Ambient Light Level Status Authenticated";
BA_ "SignalType" SG_ 1028 BGI1P_DrvrDrOpnStsAuth_Inv "ENM";
BA_ "SignalLongName" SG_ 1028 BGI1P_DrvrDrOpnStsAuth_Inv "Body General Information 1 Protected : Driver Door Open Status Authenticated Invalid";
BA_ "SignalType" SG_ 1028 BGI1P_DrvrDrOpnStsAuth_DuD "ENM";
BA_ "SignalLongName" SG_ 1028 BGI1P_DrvrDrOpnStsAuth_DuD "Body General Information 1 Protected : Driver Door Open Status Authenticated Don't Use Data";
BA_ "SignalType" SG_ 1028 BGI1P_DrvrDrOpnStsAuth "ENM";
BA_ "SignalLongName" SG_ 1028 BGI1P_DrvrDrOpnStsAuth "Body General Information 1 Protected : Driver Door Open Status Authenticated";
BA_ "SignalLongName" SG_ 572 BdyGenInfo2_PCSM "Body General Information 2 Protected Counter Sync Message";
BA_ "SignalLongName" SG_ 571 BGI2P_MAC "Body General Information 2 Protected : MAC";
BA_ "SignalLongName" SG_ 571 BGI2P_FCnt "Body General Information 2 Protected : Freshness Counter";
BA_ "SignalLongName" SG_ 571 BGI2P_ARC "Body General Information 2 Protected : Alive Rolling Count";
BA_ "SignalType" SG_ 571 BGI2P_WprFrtHiSwFiltdAuth "ENM";
BA_ "SignalLongName" SG_ 571 BGI2P_WprFrtHiSwFiltdAuth "Body General Information 2 Protected : Wiper Front High Switch Filtered Authenticated";
BA_ "SignalType" SG_ 571 BGI2P_ServWprSysDrvIndOnAuth "ENM";
BA_ "SignalLongName" SG_ 571 BGI2P_ServWprSysDrvIndOnAuth "Body General Information 2 Protected : Service Wiper System Drive Indication On Authenticated";
BA_ "SignalType" SG_ 571 BGI2P_WshFldLvlIndOnAuth "ENM";
BA_ "SignalLongName" SG_ 571 BGI2P_WshFldLvlIndOnAuth "Body General Information 2 Protected : Wash Fluid Level Indication On Authenticated";
BA_ "SignalType" SG_ 571 BGI2P_EnvModPrsntRspdr3Auth "ENM";
BA_ "SignalLongName" SG_ 571 BGI2P_EnvModPrsntRspdr3Auth "Body General Information 2 Protected : Environment Module Present - Responder #3 Authenticated";
BA_ "SignalLongName" SG_ 526 BkupSysPwrMode_PCSM "Backup System Power Mode Protected Counter Sync Message";
BA_ "SignalLongName" SG_ 525 BSPMP_MAC "Backup System Power Mode Protected : MAC";
BA_ "SignalLongName" SG_ 525 BSPMP_FCnt "Backup System Power Mode Protected : Freshness Counter";
BA_ "SignalType" SG_ 525 BSPMP_SecRunCrnkCmdActvAuth_Inv "ENM";
BA_ "SignalLongName" SG_ 525 BSPMP_SecRunCrnkCmdActvAuth_Inv "Backup System Power Mode Protected : Secondary Run Crank Command Active Invalid Authenticated";
BA_ "SignalType" SG_ 525 BSPMP_SecRunCrnkCmdActvAuth "ENM";
BA_ "SignalLongName" SG_ 525 BSPMP_SecRunCrnkCmdActvAuth "Backup System Power Mode Protected : Secondary Run Crank Command Active Authenticated";
BA_ "SignalType" SG_ 525 BSPMP_SecPwrModePBActvAuth_Inv "ENM";
BA_ "SignalLongName" SG_ 525 BSPMP_SecPwrModePBActvAuth_Inv "Backup System Power Mode Protected : Secondary Power Mode Pushbutton Active Authenticated Invalid";
BA_ "SignalType" SG_ 525 BSPMP_SecPwrModePBActvAuth "ENM";
BA_ "SignalLongName" SG_ 525 BSPMP_SecPwrModePBActvAuth "Backup System Power Mode Protected : Secondary Power Mode Pushbutton Active Authenticated";
BA_ "SignalType" SG_ 525 BSPMP_BkupSysPwrModeAuth_Inv "ENM";
BA_ "SignalLongName" SG_ 525 BSPMP_BkupSysPwrModeAuth_Inv "Backup System Power Mode Protected : Backup System Power Mode Authenticated Invalid";
BA_ "SignalType" SG_ 525 BSPMP_BkupSysPwrModeAuth "ENM";
BA_ "SignalLongName" SG_ 525 BSPMP_BkupSysPwrModeAuth "Backup System Power Mode Protected : Backup System Power Mode Authenticated";
BA_ "SignalLongName" SG_ 525 BSPMP_PV "Backup System Power Mode Protected : Protection Value";
BA_ "SignalLongName" SG_ 525 BSPMP_ARC "Backup System Power Mode Protected : Alive Rolling Count";
BA_ "SignalType" SG_ 525 BSPMP_RmtProgmActvAuth "ENM";
BA_ "SignalLongName" SG_ 525 BSPMP_RmtProgmActvAuth "Backup System Power Mode Protected : Remote Programming Active Authenticated";
BA_ "SignalLongName" SG_ 1800 BrkSysDispInfo_PCSM "Brake System Display Information Protected Counter Sync Message";
BA_ "SignalLongName" SG_ 1044 BSDIP_MAC "Brake System Display Information Protected : MAC";
BA_ "SignalLongName" SG_ 1044 BSDIP_FCnt "Brake System Display Information Protected : Freshness Counter";
BA_ "SignalType" SG_ 1044 BSDIP_ESCOffVisIndOnAuth "ENM";
BA_ "SignalLongName" SG_ 1044 BSDIP_ESCOffVisIndOnAuth "Brake System Display Information Protected : Electronic Stability Control Off Visual Indication On Authenticated";
BA_ "SignalType" SG_ 1044 BSDIP_EPBSysWrnIndReqAuth "ENM";
BA_ "SignalLongName" SG_ 1044 BSDIP_EPBSysWrnIndReqAuth "Brake System Display Information Protected : Electric Park Brake System Warning Indication Request Authenticated";
BA_ "SignalType" SG_ 1044 BSDIP_EPBSysStsIndReqAuth "ENM";
BA_ "SignalLongName" SG_ 1044 BSDIP_EPBSysStsIndReqAuth "Brake System Display Information Protected : Electric Park Brake System Status Indication Request Authenticated";
BA_ "SignalType" SG_ 1044 BSDIP_ABSIndOnAuth "ENM";
BA_ "SignalLongName" SG_ 1044 BSDIP_ABSIndOnAuth "Brake System Display Information Protected : Antilock Brake System Indication On Authenticated";
BA_ "SignalLongName" SG_ 1044 BSDIP_ARC "Brake System Display Information Protected : Alive Rolling Count";
BA_ "SignalType" SG_ 1044 BSDIP_TracCtlOffVisIndOnAuth "ENM";
BA_ "SignalLongName" SG_ 1044 BSDIP_TracCtlOffVisIndOnAuth "Brake System Display Information Protected : Traction Control Off Visual Indicator On Authenticated";
BA_ "SignalType" SG_ 1044 BSDIP_SrvBrkRdBrkTTShrtChIOAuth "ENM";
BA_ "SignalLongName" SG_ 1044 BSDIP_SrvBrkRdBrkTTShrtChIOAuth "Brake System Display Information Protected : Service Brakes Red Brake Telltale Short Chime Indication On Authenticated";
BA_ "SignalType" SG_ 1044 BSDIP_ServBrkRdBrkTTLngChIOAuth "ENM";
BA_ "SignalLongName" SG_ 1044 BSDIP_ServBrkRdBrkTTLngChIOAuth "Brake System Display Information Protected : Service Brakes Red Brake Telltale Long Chime Indication On Authenticated";
BA_ "SignalType" SG_ 1044 BSDIP_ServBrkBstSrvBrkAssIOAuth "ENM";
BA_ "SignalLongName" SG_ 1044 BSDIP_ServBrkBstSrvBrkAssIOAuth "Brake System Display Information Protected : Service Brake Boost Service Brake Assist Indication On Authenticated";
BA_ "SignalType" SG_ 1044 BSDIP_ESCVisIndReqAuth "ENM";
BA_ "SignalLongName" SG_ 1044 BSDIP_ESCVisIndReqAuth "Brake System Display Information Protected : Electronic Stability Control Visual Indication Request Authenticated";
BA_ "SignalType" SG_ 179 ClsnEvntDatRcrdgTrgrd "ENM";
BA_ "SignalLongName" SG_ 179 ClsnEvntDatRcrdgTrgrd "Collision Event Data Recording Triggered";
BA_ "SignalLongName" SG_ 41 LLDP_LongAccelAuth "Longitudinal Lateral Data Protected : Longitudinal Acceleration Authenticated";
BA_ "SignalType" SG_ 41 LLDP_LatAccelAuth_Inv "ENM";
BA_ "SignalLongName" SG_ 41 LLDP_LatAccelAuth_Inv "Longitudinal Lateral Data Protected : Lateral Acceleration Authenticated Invalid";
BA_ "SignalLongName" SG_ 41 LLDP_LatAccelAuth "Longitudinal Lateral Data Protected : Lateral Acceleration Authenticated";
BA_ "SignalType" SG_ 41 BGI3P_BrkPedModrTrvlAchAuth_Inv "ENM";
BA_ "SignalLongName" SG_ 41 BGI3P_BrkPedModrTrvlAchAuth_Inv "Body General Information 3 Protected : Brake Pedal Moderate Travel Achieved Authenticated Invalid";
BA_ "SignalType" SG_ 41 BGI3P_BrkPedPstnAuth_Inv "ENM";
BA_ "SignalLongName" SG_ 41 BGI3P_BrkPedPstnAuth_Inv "Body General Information 3 Protected : Brake Pedal Position Authenticated Invalid";
BA_ "SignalType" SG_ 41 LLDP_LongAccelAuth_Inv "ENM";
BA_ "SignalLongName" SG_ 41 LLDP_LongAccelAuth_Inv "Longitudinal Lateral Data Protected : Longitudinal Acceleration Authenticated Invalid";
BA_ "SignalLongName" SG_ 41 BGI3P_BrkPedPstnAuth "Body General Information 3 Protected : Brake Pedal Position Authenticated";
BA_ "SignalType" SG_ 41 BGI3P_BrkPedModrTrvlAchAuth "ENM";
BA_ "SignalLongName" SG_ 41 BGI3P_BrkPedModrTrvlAchAuth "Body General Information 3 Protected : Brake Pedal Moderate Travel Achieved Authenticated";
BA_ "SignalType" SG_ 41 BGI3P_BrkPedInitTrvlAchAuth_Inv "ENM";
BA_ "SignalLongName" SG_ 41 BGI3P_BrkPedInitTrvlAchAuth_Inv "Body General Information 3 Protected : Brake Pedal Initial Travel Achieved Authenticated Invalid";
BA_ "SignalType" SG_ 41 BGI3P_CruzSpdLmtrSwStsAuth "ENM";
BA_ "SignalLongName" SG_ 41 BGI3P_CruzSpdLmtrSwStsAuth "Body General Information 3 Protected : Cruise and Speed Limiter Switch Status Authenticated";
BA_ "SignalType" SG_ 41 BGI3P_BrkPedInitTrvlAchAuth "ENM";
BA_ "SignalLongName" SG_ 41 BGI3P_BrkPedInitTrvlAchAuth "Body General Information 3 Protected : Brake Pedal Initial Travel Achieved Authenticated";
BA_ "SignalLongName" SG_ 41 YRP_YawRateAuth "Yaw Rate Protected : Yaw Rate Authenticated";
BA_ "SignalLongName" SG_ 41 PBP_PTSndBrkPdlPsAuth "ECM General Information 2 Protected : Powertrain Sensed Brake Pedal Position Authenticated";
BA_ "SignalType" SG_ 41 YRP_YawRateAuth_Inv "ENM";
BA_ "SignalLongName" SG_ 41 YRP_YawRateAuth_Inv "Yaw Rate Protected : Yaw Rate Authenticated Invalid";
BA_ "SignalType" SG_ 41 YRP_YawRateAuth_DuD "ENM";
BA_ "SignalLongName" SG_ 41 YRP_YawRateAuth_DuD "Yaw Rate Protected : Yaw Rate Authenticated Don't Use Data";
BA_ "SignalType" SG_ 41 CBIP_ACCBrkgStsAuth "ENM";
BA_ "SignalLongName" SG_ 41 CBIP_ACCBrkgStsAuth "EBCM General Information 1 Protected : Adaptive Cruise Control Braking Status Authenticated";
BA_ "SignalLongName" SG_ 42 FAVP_WhlAngVelRFrtAuth "Front Angular Velocity Protected : Wheel Angular Velocity Right Front Authenticated";
BA_ "SignalType" SG_ 42 FAVP_WhlAngVelRFrtAuth_Inv "ENM";
BA_ "SignalLongName" SG_ 42 FAVP_WhlAngVelRFrtAuth_Inv "Front Angular Velocity Protected : Wheel Angular Velocity Right Front Authenticated Invalid";
BA_ "SignalLongName" SG_ 42 FAVP_ARC "Front Angular Velocity Protected : Alive Rolling Count";
BA_ "SignalLongName" SG_ 42 FAVP_WhlAngVelLFrtAuth "Front Angular Velocity Protected : Wheel Angular Velocity Left Front Authenticated";
BA_ "SignalType" SG_ 42 FAVP_WhlAngVelLFrtAuth_Inv "ENM";
BA_ "SignalLongName" SG_ 42 FAVP_WhlAngVelLFrtAuth_Inv "Front Angular Velocity Protected : Wheel Angular Velocity Left Front Authenticated Invalid";
BA_ "SignalLongName" SG_ 42 RAVP_WhlAngVelRRrAuth "Rear Angular Velocity Protected : Wheel Angular Velocity Right Rear Authenticated";
BA_ "SignalLongName" SG_ 42 RAVP_WhlAngVelLRrAuth "Rear Angular Velocity Protected : Wheel Angular Velocity Left Rear Authenticated";
BA_ "SignalType" SG_ 42 RAVP_WhlAngVelRRrAuth_Inv "ENM";
BA_ "SignalLongName" SG_ 42 RAVP_WhlAngVelRRrAuth_Inv "Rear Angular Velocity Protected : Wheel Angular Velocity Right Rear Authenticated Invalid";
BA_ "SignalType" SG_ 42 RAVP_WhlAngVelLRrAuth_Inv "ENM";
BA_ "SignalLongName" SG_ 42 RAVP_WhlAngVelLRrAuth_Inv "Rear Angular Velocity Protected : Wheel Angular Velocity Left Rear Authenticated Invalid";
BA_ "SignalLongName" SG_ 42 RAVP_ARC "Rear Angular Velocity Protected : Alive Rolling Count";
BA_ "SignalLongName" SG_ 608 VAP_ActlVehAccelAuth "EBCM General Information 2 Protected : Actual Vehicle Acceleration Authenticated";
BA_ "SignalType" SG_ 608 VAP_ActlVehAccelAuth_Inv "ENM";
BA_ "SignalLongName" SG_ 608 VAP_ActlVehAccelAuth_Inv "EBCM General Information 2 Protected : Actual Vehicle Acceleration Authenticated Invalid";
BA_ "SignalType" SG_ 608 WRDSP_RRAuth "ENM";
BA_ "SignalLongName" SG_ 608 WRDSP_RRAuth "EBCM General Information 2 Protected : Wheel Rotational Directional Status Right Rear Authenticated";
BA_ "SignalType" SG_ 608 WRDSP_LFAuth "ENM";
BA_ "SignalLongName" SG_ 608 WRDSP_LFAuth "EBCM General Information 2 Protected : Wheel Rotational Directional Status Left Front Authenticated";
BA_ "SignalLongName" SG_ 608 ThrPstn "Throttle Position";
BA_ "SignalType" SG_ 608 ThrPstn_Inv "ENM";
BA_ "SignalLongName" SG_ 608 ThrPstn_Inv "Throttle Position Invalid";
BA_ "SignalType" SG_ 608 WRDSP_RFAuth "ENM";
BA_ "SignalLongName" SG_ 608 WRDSP_RFAuth "EBCM General Information 2 Protected : Wheel Rotational Directional Status Right Front Authenticated";
BA_ "SignalType" SG_ 608 WRDSP_LRAuth "ENM";
BA_ "SignalLongName" SG_ 608 WRDSP_LRAuth "EBCM General Information 2 Protected : Wheel Rotational Directional Status Left Rear Authenticated";
BA_ "SignalLongName" SG_ 608 TrlrBrkgFOut "Trailer Braking Force Output";
BA_ "SignalType" SG_ 608 TrnsTrqCnvCltCmdMd "ENM";
BA_ "SignalLongName" SG_ 608 TrnsTrqCnvCltCmdMd "Transmission Torque Converter Clutch Commanded Mode";
BA_ "SignalLongName" SG_ 609 DRCDNDP_DRCAvgDrvnAuth "ECM General Information 1 Protected : Distance Rolling Count Average Driven Authenticated";
BA_ "SignalType" SG_ 609 DRCDNDP_DRCAvgDrvnRstOccAuth "ENM";
BA_ "SignalLongName" SG_ 609 DRCDNDP_DRCAvgDrvnRstOccAuth "ECM General Information 1 Protected : Distance Rolling Count Average Driven Reset Occurred Authenticated";
BA_ "SignalType" SG_ 609 DRCDNDP_DRCAvgDrvnAuth_Inv "ENM";
BA_ "SignalLongName" SG_ 609 DRCDNDP_DRCAvgDrvnAuth_Inv "ECM General Information 1 Protected : Distance Rolling Count Average Driven Authenticated Invalid";
BA_ "SignalType" SG_ 609 DRCDNDP_DRCAvgNonDrvnAuth_Inv "ENM";
BA_ "SignalLongName" SG_ 609 DRCDNDP_DRCAvgNonDrvnAuth_Inv "ECM General Information 1 Protected : Distance Rolling Count Average Non Driven Authenticated Invalid";
BA_ "SignalLongName" SG_ 609 DRCDNDP_DRCAvgNonDrvnAuth "ECM General Information 1 Protected : Distance Rolling Count Average Non Driven Authenticated";
BA_ "SignalType" SG_ 609 DRCDNDP_DRCAvgNonDrvnRstOccAuth "ENM";
BA_ "SignalLongName" SG_ 609 DRCDNDP_DRCAvgNonDrvnRstOccAuth "ECM General Information 1 Protected : Distance Rolling Count Average Non Driven Reset Occurred Authenticated";
BA_ "SignalType" SG_ 609 DRCDNDP_DRCAvgDrvnSrcAuth "ENM";
BA_ "SignalLongName" SG_ 609 DRCDNDP_DRCAvgDrvnSrcAuth "ECM General Information 1 Protected : Distance Rolling Count Average Driven Source Authenticated";
BA_ "SignalLongName" SG_ 609 PrplDispBatPwr "Propulsion Display Battery Power";
BA_ "SignalLongName" SG_ 609 BSIS2P_BrkPdlDrvApplPresAuth "Brake System Information Status 2 Protected : Brake Pedal Driver Applied Pressure Authenticated";
BA_ "SignalType" SG_ 609 BSIS2P_BrkPdlDrvAppPrsDetcdAuth "ENM";
BA_ "SignalLongName" SG_ 609 BSIS2P_BrkPdlDrvAppPrsDetcdAuth "Brake System Information Status 2 Protected : Brake Pedal Driver Applied Pressure Detected Authenticated";
BA_ "SignalType" SG_ 609 BSIS2P_BrkPdlDrvAppPrsDtdAuth_In "ENM";
BA_ "SignalLongName" SG_ 609 BSIS2P_BrkPdlDrvAppPrsDtdAuth_In "Brake System Information Status 2 Protected : Brake Pedal Driver Applied Pressure Detected Authenticated Invalid";
BA_ "SignalType" SG_ 609 BSIS2P_BrkPdlDrvApplPresAuth_Inv "ENM";
BA_ "SignalLongName" SG_ 609 BSIS2P_BrkPdlDrvApplPresAuth_Inv "Brake System Information Status 2 Protected : Brake Pedal Driver Applied Pressure Authenticated Invalid";
BA_ "SignalType" SG_ 609 BSIS2P_ABSFldAuth "ENM";
BA_ "SignalLongName" SG_ 609 BSIS2P_ABSFldAuth "Brake System Information Status 2 Protected : Antilock Brake System Failed Authenticated";
BA_ "SignalType" SG_ 609 BSIS2P_ABSAtvAuth "ENM";
BA_ "SignalLongName" SG_ 609 BSIS2P_ABSAtvAuth "Brake System Information Status 2 Protected : Antilock Brake System Active Authenticated";
BA_ "SignalType" SG_ 610 AAASSRP_StrgReqStsAuth "ENM";
BA_ "SignalLongName" SG_ 610 AAASSRP_StrgReqStsAuth "Arbitrated ASIL Active Safety Steering Request Protected : Steering Request Status Authenticated";
BA_ "SignalType" SG_ 610 EPSOP_ElecPwStrgTqOvlyStsAuth "ENM";
BA_ "SignalLongName" SG_ 610 EPSOP_ElecPwStrgTqOvlyStsAuth "Electronic Power Steering Overlay Protected : Electronic Power Steering Torque Overlay Status Authenticated";
BA_ "SignalType" SG_ 610 EngCyldrDctvRqd "ENM";
BA_ "SignalLongName" SG_ 610 EngCyldrDctvRqd "Engine Cylinder Deactivation Requested";
BA_ "SignalType" SG_ 610 EngCylDctvMd "ENM";
BA_ "SignalLongName" SG_ 610 EngCylDctvMd "Engine Cylinder Deactivation Mode";
BA_ "SignalType" SG_ 610 SWHOP_StrgWhlHndsOffDtnStatAuth "ENM";
BA_ "SignalLongName" SG_ 610 SWHOP_StrgWhlHndsOffDtnStatAuth "Steering Wheel Hands Off Protected : Steering Wheel Hands Off Detection State Authenticated";
BA_ "SignalType" SG_ 610 SSASIP_StrgWhlTrqIntegStsAuth "ENM";
BA_ "SignalLongName" SG_ 610 SSASIP_StrgWhlTrqIntegStsAuth "Steering System to Active Safety Information Protected : Steering Wheel Torque Integrity Status Authenticated";
BA_ "SignalType" SG_ 1475 PTOAccelUpnBrkRelIndOn "ENM";
BA_ "SignalLongName" SG_ 1475 PTOAccelUpnBrkRelIndOn "Power Take Off Acceleration Upon Brake Release Indication On";
BA_ "SignalType" SG_ 1475 PTOEngRunTmrCstCurrSetVal "ENM";
BA_ "SignalLongName" SG_ 1475 PTOEngRunTmrCstCurrSetVal "Power Take Off Engine Run Timer Customization Current Setting Value";
BA_ "SignalType" SG_ 1481 PTOStndbySpdCstSetAval "ENM";
BA_ "SignalLongName" SG_ 1481 PTOStndbySpdCstSetAval "Power Take Off Standby Speed Customization Setting Available";
BA_ "SignalType" SG_ 1481 PTOSetPrkBrkIndOn "ENM";
BA_ "SignalLongName" SG_ 1481 PTOSetPrkBrkIndOn "Power Take Off Set Park Brake Indication On";
BA_ "SignalType" SG_ 1481 PTOSet2SpdCstSetAval "ENM";
BA_ "SignalLongName" SG_ 1481 PTOSet2SpdCstSetAval "Power Take Off Set 2 Speed Customization Setting Available";
BA_ "SignalType" SG_ 1481 PTOSet1SpdCstSetAval "ENM";
BA_ "SignalLongName" SG_ 1481 PTOSet1SpdCstSetAval "Power Take Off Set 1 Speed Customization Setting Available";
BA_ "SignalType" SG_ 1481 PTOServIndOn "ENM";
BA_ "SignalLongName" SG_ 1481 PTOServIndOn "Power Take Off Service Indication On";
BA_ "SignalType" SG_ 1481 PTORelBrkPedIndOn "ENM";
BA_ "SignalLongName" SG_ 1481 PTORelBrkPedIndOn "Power Take Off Release Brake Pedal Indication On";
BA_ "SignalType" SG_ 1481 PTORelAccelPedIndOn "ENM";
BA_ "SignalLongName" SG_ 1481 PTORelAccelPedIndOn "Power Take Off Release Accelerator Pedal Indication On";
BA_ "SignalType" SG_ 1481 PTORdcEngSpdIndOn "ENM";
BA_ "SignalLongName" SG_ 1481 PTORdcEngSpdIndOn "Power Take Off Reduce Engine Speed Indication On";
BA_ "SignalType" SG_ 1481 PTExPrtclFltrWrn3IndOn "ENM";
BA_ "SignalLongName" SG_ 1481 PTExPrtclFltrWrn3IndOn "Powertrain Exhaust Particle Filter Warning 3 Indication On";
BA_ "SignalType" SG_ 1481 PTExPrtclFltrMnlRgnSts "ENM";
BA_ "SignalLongName" SG_ 1481 PTExPrtclFltrMnlRgnSts "Powertrain Exhaust Particle Filter Manual Regeneration Status";
BA_ "SignalType" SG_ 1481 ServFuelSysTrnsfrPmpIO "ENM";
BA_ "SignalLongName" SG_ 1481 ServFuelSysTrnsfrPmpIO "Service Fuel System Transfer Pump Indication On";
BA_ "SignalType" SG_ 1481 PTOTransInGrIndOn "ENM";
BA_ "SignalLongName" SG_ 1481 PTOTransInGrIndOn "Power Take Off Transmission In Gear Indication On";
BA_ "SignalType" SG_ 1481 PTOTpStpSpdCstSetAval "ENM";
BA_ "SignalLongName" SG_ 1481 PTOTpStpSpdCstSetAval "Power Take Off Tap Step Speed Customization Setting Available";
BA_ "SignalType" SG_ 1486 HiVltgChrgrSysSts "ENM";
BA_ "SignalLongName" SG_ 1486 HiVltgChrgrSysSts "High Voltage Charger System Status";
BA_ "SignalType" SG_ 1486 PTOEngUpnBrkRelIndOn "ENM";
BA_ "SignalLongName" SG_ 1486 PTOEngUpnBrkRelIndOn "Power Take Off Engage Upon Brake Release Indication On";
BA_ "SignalType" SG_ 1486 PTODisengCruzCtlIndOn "ENM";
BA_ "SignalLongName" SG_ 1486 PTODisengCruzCtlIndOn "Power Take Off Disengage Cruise Control Indication On";
BA_ "SignalType" SG_ 1486 PTOEngmntStsInd "ENM";
BA_ "SignalLongName" SG_ 1486 PTOEngmntStsInd "Power Take Off Engagement Status Indication";
BA_ "SignalType" SG_ 1486 PTOEngRunTmrCstAvlFlg2 "ENM";
BA_ "SignalLongName" SG_ 1486 PTOEngRunTmrCstAvlFlg2 "Power Take Off Engine Run Timer Customization Availability Flag 2";
BA_ "SignalType" SG_ 1486 PTOEngRunTmrCstAvlFlg15 "ENM";
BA_ "SignalLongName" SG_ 1486 PTOEngRunTmrCstAvlFlg15 "Power Take Off Engine Run Timer Customization Availability Flag 15";
BA_ "SignalType" SG_ 1486 PTOEngRunTmrCstAvlFlg14 "ENM";
BA_ "SignalLongName" SG_ 1486 PTOEngRunTmrCstAvlFlg14 "Power Take Off Engine Run Timer Customization Availability Flag 14";
BA_ "SignalType" SG_ 1486 PTOEngRunTmrCstAvlFlg13 "ENM";
BA_ "SignalLongName" SG_ 1486 PTOEngRunTmrCstAvlFlg13 "Power Take Off Engine Run Timer Customization Availability Flag 13";
BA_ "SignalType" SG_ 1486 PTOEngRunTmrCstAvlFlg12 "ENM";
BA_ "SignalLongName" SG_ 1486 PTOEngRunTmrCstAvlFlg12 "Power Take Off Engine Run Timer Customization Availability Flag 12";
BA_ "SignalType" SG_ 1486 EngAftRunIndReq "ENM";
BA_ "SignalLongName" SG_ 1486 EngAftRunIndReq "Engine After Run Indication Request";
VAL_ 1110 ASS_PhLckdLpLckd 0 "FALSE" 1 "TRUE" ;
VAL_ 1110 ASS_DSPMd7Prsnt 0 "FALSE" 1 "TRUE" ;
VAL_ 1110 ASS_DSPMd0Prsnt 0 "FALSE" 1 "TRUE" ;
VAL_ 1110 ASS_DSPMd5Prsnt 0 "FALSE" 1 "TRUE" ;
VAL_ 1110 ASS_VehNoisCmpnAvail 0 "FALSE" 1 "TRUE" ;
VAL_ 1110 ASS_DSPAvail 0 "FALSE" 1 "TRUE" ;
VAL_ 1110 ASS_DSPMd1Prsnt 0 "FALSE" 1 "TRUE" ;
VAL_ 1110 ASS_SurndAvail 0 "FALSE" 1 "TRUE" ;
VAL_ 1110 ASS_DSPMd4Prsnt 0 "FALSE" 1 "TRUE" ;
VAL_ 1110 ASS_DSPMd2Prsnt 0 "FALSE" 1 "TRUE" ;
VAL_ 1110 ASS_MtxSnkMutStat 0 "FALSE" 1 "TRUE" ;
VAL_ 1110 ASS_DSPMd6Prsnt 0 "FALSE" 1 "TRUE" ;
VAL_ 1110 ASS_DSPMd3Prsnt 0 "FALSE" 1 "TRUE" ;
VAL_ 1110 FrtPsngrMtxSnkMutSts 0 "FALSE" 1 "TRUE" ;
VAL_ 1110 CCSI_CrtclChmPrdcrSOH 0 "Unknown" 1 "Healthy" 2 "Faulted" ;
VAL_ 1110 RRMtxSnkMutSts 0 "FALSE" 1 "TRUE" ;
VAL_ 1110 LRMtxSnkMutSts 0 "FALSE" 1 "TRUE" ;
VAL_ 1380 DirAudPrmtRndrngActv 0 "FALSE" 1 "TRUE" ;
VAL_ 1380 HMIInCarVcCommSts 0 "ICC_Off" 1 "ICC_Idle" 2 "Front_High_Rear_High" 3 "Front_High_Rear_Normal" 4 "Front_High_Rear_Off" 5 "Front_Normal_Rear_High" 6 "Front_Normal_Rear_Normal" 7 "Front_Normal_Rear_Off" ;
VAL_ 22 AATP_ActAxlTrqAuth_Inv 0 "FALSE" 1 "TRUE" ;
VAL_ 22 AEPP_AccEffcPosAuth_Inv 0 "FALSE" 1 "TRUE" ;
VAL_ 677 ASDRP_LnCntrWrnExtdIndReqAuth 0 "No Indication" 1 "Can Not See Lanes" 2 "Tight Curve" 3 "Freeway Ends" 4 "Construction" 5 "Excessive Speed" 6 "Vehicles Proximity" 7 "Unavailable" 8 "Attention Unknown" 9 "Due to Weather" 10 "Take Steering" 11 "Take Vehicle Control" 12 "Service Driver Assist System" 13 "Lane Following Locked Out" 14 "Reserved 1" 15 "Lane Ending" 16 "Exit Lane" 17 "GM Authority" 18 "Vehicle Setting" 19 "Adaptive Cruise" 20 "Controlled Access" 21 "Driver Attention Off Road" 22 "GPS Unavailable" 23 "Driver Action" 24 "Vehicle Center" 25 "Sensor Impaired" 26 "Opening Left" 27 "Opening Right" 28 "Changing Left" 29 "Changing Right" 30 "Complete Left" 31 "Complete Right" 32 "Unable Left" 33 "Unable Right" 34 "Cancelled Left" 35 "Cancelled Right" 36 "Timed Out Left" 37 "Timed Out Right" 38 "Trailer Narrow Lane" 39 "Trailer Dimensions" 40 "Trailer Braking" 41 "Trailer Overloaded" 42 "Trailer Stability" 43 "Subscription Required" ;
VAL_ 677 ASDRP_LnCntrCtlIndReqAuth 0 "Indication Off" 1 "White Indicator" 2 "Green Indicator" 3 "Yellow Indicator" 4 "Red Indicator" 5 "Blue Indicator" ;
VAL_ 1353 ASOCNP_LKATakeStrgIndOnAuth 0 "FALSE" 1 "TRUE" ;
VAL_ 1058 ASTIP_LnCntrVehStopdAuth 0 "FALSE" 1 "TRUE" ;
VAL_ 1261 ASSLC_AutoLdnsCmpnAct 0 "FALSE" 1 "TRUE" ;
VAL_ 1261 ASSLC_VcSrcActOnMtx 0 "FALSE" 1 "TRUE" ;
VAL_ 1029 AutoLnChgCstAvlFlg5 0 "FALSE" 1 "TRUE" ;
VAL_ 1029 AutoLnChgCstAvlFlg4 0 "FALSE" 1 "TRUE" ;
VAL_ 1029 AutoLnChgCstAvlFlg3 0 "FALSE" 1 "TRUE" ;
VAL_ 1029 AutoLnChgCstAvlFlg2 0 "FALSE" 1 "TRUE" ;
VAL_ 1029 AutoLnChgCstAvlFlg1 0 "FALSE" 1 "TRUE" ;
VAL_ 1029 AutoLnChgCstCurrSetVal 0 "Setting Unkown" 1 "Off" 2 "On" 3 "LCOD" 4 "LCOD and ALC" ;
VAL_ 1029 RIMObjAtchdIndOn 0 "FALSE" 1 "TRUE" ;
VAL_ 1029 RIMElecPrkBrkRelIndOn 0 "FALSE" 1 "TRUE" ;
VAL_ 1029 AutoLnChgCstSetAval 0 "FALSE" 1 "TRUE" ;
VAL_ 1029 AutoLnChgCstAvlFlg7 0 "FALSE" 1 "TRUE" ;
VAL_ 1029 AutoLnChgCstAvlFlg6 0 "FALSE" 1 "TRUE" ;
VAL_ 1028 BGI1P_RmtVehStrtReqAuth 0 "FALSE" 1 "TRUE" ;
VAL_ 1028 BGI1P_RmtStrtStsAuth 0 "Inactive" 1 "Active" ;
VAL_ 1028 BGI1P_OutsdAmbtLgtLvlStsAuth 0 "Unknown" 1 "Day" 2 "Night" ;
VAL_ 1028 BGI1P_DrvrDrOpnStsAuth_Inv 0 "FALSE" 1 "TRUE" ;
VAL_ 1028 BGI1P_DrvrDrOpnStsAuth_DuD 0 "FALSE" 1 "TRUE" ;
VAL_ 1028 BGI1P_DrvrDrOpnStsAuth 0 "FALSE" 1 "TRUE" ;
VAL_ 571 BGI2P_WprFrtHiSwFiltdAuth 0 "FALSE" 1 "TRUE" ;
VAL_ 571 BGI2P_ServWprSysDrvIndOnAuth 0 "FALSE" 1 "TRUE" ;
VAL_ 571 BGI2P_WshFldLvlIndOnAuth 0 "FALSE" 1 "TRUE" ;
VAL_ 571 BGI2P_EnvModPrsntRspdr3Auth 0 "FALSE" 1 "TRUE" ;
VAL_ 525 BSPMP_SecRunCrnkCmdActvAuth_Inv 0 "FALSE" 1 "TRUE" ;
VAL_ 525 BSPMP_SecRunCrnkCmdActvAuth 0 "FALSE" 1 "TRUE" ;
VAL_ 525 BSPMP_SecPwrModePBActvAuth_Inv 0 "FALSE" 1 "TRUE" ;
VAL_ 525 BSPMP_SecPwrModePBActvAuth 0 "FALSE" 1 "TRUE" ;
VAL_ 525 BSPMP_BkupSysPwrModeAuth_Inv 0 "FALSE" 1 "TRUE" ;
VAL_ 525 BSPMP_BkupSysPwrModeAuth 0 "Off" 1 "Accessory" 2 "Run" 3 "Start Request" 4 "Propulsion" ;
VAL_ 525 BSPMP_RmtProgmActvAuth 0 "FALSE" 1 "TRUE" ;
VAL_ 1044 BSDIP_ESCOffVisIndOnAuth 0 "FALSE" 1 "TRUE" ;
VAL_ 1044 BSDIP_EPBSysWrnIndReqAuth 0 "Off" 1 "On" 2 "0.5_Hz" 3 "1_Hz" 4 "2_Hz" 5 "4_Hz" ;
VAL_ 1044 BSDIP_EPBSysStsIndReqAuth 0 "Off" 1 "On" 2 "0.5_Hz" 3 "1_Hz" 4 "2_Hz" 5 "4_Hz" ;
VAL_ 1044 BSDIP_ABSIndOnAuth 0 "FALSE" 1 "TRUE" ;
VAL_ 1044 BSDIP_TracCtlOffVisIndOnAuth 0 "FALSE" 1 "TRUE" ;
VAL_ 1044 BSDIP_SrvBrkRdBrkTTShrtChIOAuth 0 "FALSE" 1 "TRUE" ;
VAL_ 1044 BSDIP_ServBrkRdBrkTTLngChIOAuth 0 "FALSE" 1 "TRUE" ;
VAL_ 1044 BSDIP_ServBrkBstSrvBrkAssIOAuth 0 "FALSE" 1 "TRUE" ;
VAL_ 1044 BSDIP_ESCVisIndReqAuth 0 "OFF" 1 "ON" 2 "2_Hz" ;
VAL_ 179 ClsnEvntDatRcrdgTrgrd 0 "FALSE" 1 "TRUE" ;
VAL_ 41 LLDP_LatAccelAuth_Inv 0 "FALSE" 1 "TRUE" ;
VAL_ 41 BGI3P_BrkPedModrTrvlAchAuth_Inv 0 "FALSE" 1 "TRUE" ;
VAL_ 41 BGI3P_BrkPedPstnAuth_Inv 0 "FALSE" 1 "TRUE" ;
VAL_ 41 LLDP_LongAccelAuth_Inv 0 "FALSE" 1 "TRUE" ;
VAL_ 41 BGI3P_BrkPedModrTrvlAchAuth 0 "FALSE" 1 "TRUE" ;
VAL_ 41 BGI3P_BrkPedInitTrvlAchAuth_Inv 0 "FALSE" 1 "TRUE" ;
VAL_ 41 BGI3P_CruzSpdLmtrSwStsAuth 0 "Indeterminate" 1 "No_Activation" 2 "Resume" 3 "Set" 4 "SL/SW On/Off" 5 "Cruise On/Off" 6 "Cancel" 7 "Short to Ground" 8 "Open/Short to Power" 9 "Between_Ranges" ;
VAL_ 41 BGI3P_BrkPedInitTrvlAchAuth 0 "FALSE" 1 "TRUE" ;
VAL_ 41 YRP_YawRateAuth_Inv 0 "FALSE" 1 "TRUE" ;
VAL_ 41 YRP_YawRateAuth_DuD 0 "FALSE" 1 "TRUE" ;
VAL_ 41 CBIP_ACCBrkgStsAuth 0 "Not Active" 1 "Active" 2 "Failed" ;
VAL_ 42 FAVP_WhlAngVelRFrtAuth_Inv 0 "FALSE" 1 "TRUE" ;
VAL_ 42 FAVP_WhlAngVelLFrtAuth_Inv 0 "FALSE" 1 "TRUE" ;
VAL_ 42 RAVP_WhlAngVelRRrAuth_Inv 0 "FALSE" 1 "TRUE" ;
VAL_ 42 RAVP_WhlAngVelLRrAuth_Inv 0 "FALSE" 1 "TRUE" ;
VAL_ 608 VAP_ActlVehAccelAuth_Inv 0 "FALSE" 1 "TRUE" ;
VAL_ 608 WRDSP_RRAuth 0 "Unknown" 1 "Not Supported" 2 "Invalid" 3 "Forward" 4 "Reverse" ;
VAL_ 608 WRDSP_LFAuth 0 "Unknown" 1 "Not Supported" 2 "Invalid" 3 "Forward" 4 "Reverse" ;
VAL_ 608 ThrPstn_Inv 0 "FALSE" 1 "TRUE" ;
VAL_ 608 WRDSP_RFAuth 0 "Unknown" 1 "Not Supported" 2 "Invalid" 3 "Forward" 4 "Reverse" ;
VAL_ 608 WRDSP_LRAuth 0 "Unknown" 1 "Not Supported" 2 "Invalid" 3 "Forward" 4 "Reverse" ;
VAL_ 608 TrnsTrqCnvCltCmdMd 0 "Unlocked" 1 "Transitioning" 2 "Controlled Slip" 3 "Locked" 4 "Not Supported" ;
VAL_ 609 DRCDNDP_DRCAvgDrvnRstOccAuth 0 "FALSE" 1 "TRUE" ;
VAL_ 609 DRCDNDP_DRCAvgDrvnAuth_Inv 0 "FALSE" 1 "TRUE" ;
VAL_ 609 DRCDNDP_DRCAvgNonDrvnAuth_Inv 0 "FALSE" 1 "TRUE" ;
VAL_ 609 DRCDNDP_DRCAvgNonDrvnRstOccAuth 0 "FALSE" 1 "TRUE" ;
VAL_ 609 DRCDNDP_DRCAvgDrvnSrcAuth 0 "Transmission Output Speed" 1 "Wheel Speed" ;
VAL_ 609 BSIS2P_BrkPdlDrvAppPrsDetcdAuth 0 "FALSE" 1 "TRUE" ;
VAL_ 609 BSIS2P_BrkPdlDrvAppPrsDtdAuth_In 0 "FALSE" 1 "TRUE" ;
VAL_ 609 BSIS2P_BrkPdlDrvApplPresAuth_Inv 0 "FALSE" 1 "TRUE" ;
VAL_ 609 BSIS2P_ABSFldAuth 0 "FALSE" 1 "TRUE" ;
VAL_ 609 BSIS2P_ABSAtvAuth 0 "FALSE" 1 "TRUE" ;
VAL_ 610 AAASSRP_StrgReqStsAuth 0 "Unknown" 1 "Active" 2 "Inactive" ;
VAL_ 610 EPSOP_ElecPwStrgTqOvlyStsAuth 0 "Unknown" 1 "Temporarily Inhibited" 2 "Inactive" 3 "Active" 4 "Temporarily Limited" 5 "Failed" ;
VAL_ 610 EngCyldrDctvRqd 0 "FALSE" 1 "TRUE" ;
VAL_ 610 EngCylDctvMd 0 "All Cylinders Active" 1 "Deactivation In Progress" 2 "Half of Total Cylinders Active" 3 "Reactivation In Progress" ;
VAL_ 610 SWHOP_StrgWhlHndsOffDtnStatAuth 0 "Hands On" 1 "Hands Off" 2 "Unknown" ;
VAL_ 610 SSASIP_StrgWhlTrqIntegStsAuth 0 "Unknown" 1 "Redundant ASIL D" 2 "Non Redundant ASIL D" 3 "Failed" ;
VAL_ 1475 PTOAccelUpnBrkRelIndOn 0 "FALSE" 1 "TRUE" ;
VAL_ 1475 PTOEngRunTmrCstCurrSetVal 0 "Setting Unknown" 1 "Min 10" 2 "Min 30" 3 "Min 90" 4 "Min 120" 5 "Min 150" 6 "Min 180" 7 "Min 210" 8 "Min 240" 9 "Min 270" 10 "Min 200" 11 "Min 330" 12 "Min 360" 13 "Min 390" 14 "Min 420" 15 "Min 450" ;
VAL_ 1481 PTOStndbySpdCstSetAval 0 "FALSE" 1 "TRUE" ;
VAL_ 1481 PTOSetPrkBrkIndOn 0 "FALSE" 1 "TRUE" ;
VAL_ 1481 PTOSet2SpdCstSetAval 0 "FALSE" 1 "TRUE" ;
VAL_ 1481 PTOSet1SpdCstSetAval 0 "FALSE" 1 "TRUE" ;
VAL_ 1481 PTOServIndOn 0 "FALSE" 1 "TRUE" ;
VAL_ 1481 PTORelBrkPedIndOn 0 "FALSE" 1 "TRUE" ;
VAL_ 1481 PTORelAccelPedIndOn 0 "FALSE" 1 "TRUE" ;
VAL_ 1481 PTORdcEngSpdIndOn 0 "FALSE" 1 "TRUE" ;
VAL_ 1481 PTExPrtclFltrWrn3IndOn 0 "FALSE" 1 "TRUE" ;
VAL_ 1481 PTExPrtclFltrMnlRgnSts 0 "Cleaning Not Required" 1 "Allowed" 2 "Not Allowed" 3 "In Progress" 4 "Complete" 5 "Pending Driver Input" 6 "Not Available" 7 "Do Not Press Pedals" ;
VAL_ 1481 ServFuelSysTrnsfrPmpIO 0 "FALSE" 1 "TRUE" ;
VAL_ 1481 PTOTransInGrIndOn 0 "FALSE" 1 "TRUE" ;
VAL_ 1481 PTOTpStpSpdCstSetAval 0 "FALSE" 1 "TRUE" ;
VAL_ 1486 HiVltgChrgrSysSts 0 "Default" 1 "Idle" 2 "Initializing" 3 "Active" 4 "Complete" 5 "Aborted" 6 "Utility Override Active" 7 "Utility Override Reduced Power" 8 "Pause Due to Update" 9 "Connection Unpowered" 10 "Unconnected" ;
VAL_ 1486 PTOEngUpnBrkRelIndOn 0 "FALSE" 1 "TRUE" ;
VAL_ 1486 PTODisengCruzCtlIndOn 0 "FALSE" 1 "TRUE" ;
VAL_ 1486 PTOEngmntStsInd 0 "No Indication" 1 "Continuous Indication" 2 "Slow Flashing Indication" 3 "Fast Flashing Indication" ;
VAL_ 1486 PTOEngRunTmrCstAvlFlg2 0 "FALSE" 1 "TRUE" ;
VAL_ 1486 PTOEngRunTmrCstAvlFlg15 0 "FALSE" 1 "TRUE" ;
VAL_ 1486 PTOEngRunTmrCstAvlFlg14 0 "FALSE" 1 "TRUE" ;
VAL_ 1486 PTOEngRunTmrCstAvlFlg13 0 "FALSE" 1 "TRUE" ;
VAL_ 1486 PTOEngRunTmrCstAvlFlg12 0 "FALSE" 1 "TRUE" ;
VAL_ 1486 EngAftRunIndReq 0 "No Action" 1 "No Indication" 2 "Idle Needed" 3 "Overheated" 4 "Interrupted" ;
